VERSION ""

NS_ :

BS_:

BU_: L_DHRR_FD L_UWB_BLE_MST_FD L_UWB_RR_FD L_UWB_BLE_SLV_FD L_UWB_FR_FD L_ROA_FR_FD L_ROA_FD L_DHRL_FD L_UWB_TRNK_FD L_EDT_FD L_UWB_FRNK_FD L_UWB_FL_FD GW_BDC_FD L_UWB_RL_FD L_SAL_FD L_WPC_FD L_TPMS_FD L_DHL_FD L_DHR_FD

BO_ 402391152 NM_CGW_CCU: 32 GW_BDC_FD
 SG_ SNI_CGW_CCU : 0|8@1+ (1,0) [0|0] ""  L_DHL_FD,L_DHRL_FD,L_DHRR_FD,L_DHR_FD,L_SAL_FD,L_TPMS_FD,L_UWB_BLE_MST_FD,L_UWB_BLE_SLV_FD,L_UWB_FL_FD,L_UWB_FRNK_FD,L_UWB_FR_FD,L_UWB_RL_FD,L_UWB_RR_FD,L_UWB_TRNK_FD,L_WPC_FD
 SG_ CBV_NMCoSRB_CGW_CCU : 11|1@1+ (1,0) [0|0] ""  L_DHL_FD,L_DHRL_FD,L_DHRR_FD,L_DHR_FD,L_SAL_FD,L_TPMS_FD,L_UWB_BLE_MST_FD,L_UWB_BLE_SLV_FD,L_UWB_FL_FD,L_UWB_FRNK_FD,L_UWB_FR_FD,L_UWB_RL_FD,L_UWB_RR_FD,L_UWB_TRNK_FD,L_WPC_FD
 SG_ CBV_AWB_CGW_CCU : 12|1@1+ (1,0) [0|0] ""  L_DHL_FD,L_DHRL_FD,L_DHRR_FD,L_DHR_FD,L_SAL_FD,L_TPMS_FD,L_UWB_BLE_MST_FD,L_UWB_BLE_SLV_FD,L_UWB_FL_FD,L_UWB_FRNK_FD,L_UWB_FR_FD,L_UWB_RL_FD,L_UWB_RR_FD,L_UWB_TRNK_FD,L_WPC_FD
 SG_ PNI_CGW_CCU_2 : 128|64@1+ (1,0) [0|0] ""  L_DHL_FD,L_DHRL_FD,L_DHRR_FD,L_DHR_FD,L_SAL_FD,L_TPMS_FD,L_UWB_BLE_MST_FD,L_UWB_BLE_SLV_FD,L_UWB_FL_FD,L_UWB_FRNK_FD,L_UWB_FR_FD,L_UWB_RL_FD,L_UWB_RR_FD,L_UWB_TRNK_FD,L_WPC_FD
 SG_ CBV_PNIB_CGW_CCU : 14|1@1+ (1,0) [0|0] ""  L_DHL_FD,L_DHRL_FD,L_DHRR_FD,L_DHR_FD,L_SAL_FD,L_TPMS_FD,L_UWB_BLE_MST_FD,L_UWB_BLE_SLV_FD,L_UWB_FL_FD,L_UWB_FRNK_FD,L_UWB_FR_FD,L_UWB_RL_FD,L_UWB_RR_FD,L_UWB_TRNK_FD,L_WPC_FD
 SG_ NRR_CGW_CCU : 16|8@1+ (1,0) [0|0] ""  L_DHL_FD,L_DHRL_FD,L_DHRR_FD,L_DHR_FD,L_SAL_FD,L_TPMS_FD,L_UWB_BLE_MST_FD,L_UWB_BLE_SLV_FD,L_UWB_FL_FD,L_UWB_FRNK_FD,L_UWB_FR_FD,L_UWB_RL_FD,L_UWB_RR_FD,L_UWB_TRNK_FD,L_WPC_FD
 SG_ PNI_CGW_CCU_3 : 192|64@1+ (1,0) [0|0] ""  L_DHL_FD,L_DHRL_FD,L_DHRR_FD,L_DHR_FD,L_SAL_FD,L_TPMS_FD,L_UWB_BLE_MST_FD,L_UWB_BLE_SLV_FD,L_UWB_FL_FD,L_UWB_FRNK_FD,L_UWB_FR_FD,L_UWB_RL_FD,L_UWB_RR_FD,L_UWB_TRNK_FD,L_WPC_FD
 SG_ NM_State_CGW_CCU : 24|8@1+ (1,0) [0|0] ""  L_DHL_FD,L_DHRL_FD,L_DHRR_FD,L_DHR_FD,L_SAL_FD,L_TPMS_FD,L_UWB_BLE_MST_FD,L_UWB_BLE_SLV_FD,L_UWB_FL_FD,L_UWB_FRNK_FD,L_UWB_FR_FD,L_UWB_RL_FD,L_UWB_RR_FD,L_UWB_TRNK_FD,L_WPC_FD
 SG_ PNI_CGW_CCU : 32|32@1+ (1,0) [0|0] ""  L_DHL_FD,L_DHRL_FD,L_DHRR_FD,L_DHR_FD,L_SAL_FD,L_TPMS_FD,L_UWB_BLE_MST_FD,L_UWB_BLE_SLV_FD,L_UWB_FL_FD,L_UWB_FRNK_FD,L_UWB_FR_FD,L_UWB_RL_FD,L_UWB_RR_FD,L_UWB_TRNK_FD,L_WPC_FD
 SG_ PNI_CGW_CCU_1 : 64|64@1+ (1,0) [0|0] ""  L_DHL_FD,L_DHRL_FD,L_DHRR_FD,L_DHR_FD,L_SAL_FD,L_TPMS_FD,L_UWB_BLE_MST_FD,L_UWB_BLE_SLV_FD,L_UWB_FL_FD,L_UWB_FRNK_FD,L_UWB_FR_FD,L_UWB_RL_FD,L_UWB_RR_FD,L_UWB_TRNK_FD,L_WPC_FD
 SG_ CBV_RMR_CGW_CCU : 8|1@1+ (1,0) [0|0] ""  L_DHL_FD,L_DHRL_FD,L_DHRR_FD,L_DHR_FD,L_SAL_FD,L_TPMS_FD,L_UWB_BLE_MST_FD,L_UWB_BLE_SLV_FD,L_UWB_FL_FD,L_UWB_FRNK_FD,L_UWB_FR_FD,L_UWB_RL_FD,L_UWB_RR_FD,L_UWB_TRNK_FD,L_WPC_FD
 SG_ CBV_NMCoID_CGW_CCU : 9|2@1+ (1,0) [0|0] ""  L_DHL_FD,L_DHRL_FD,L_DHRR_FD,L_DHR_FD,L_SAL_FD,L_TPMS_FD,L_UWB_BLE_MST_FD,L_UWB_BLE_SLV_FD,L_UWB_FL_FD,L_UWB_FRNK_FD,L_UWB_FR_FD,L_UWB_RL_FD,L_UWB_RR_FD,L_UWB_TRNK_FD,L_WPC_FD

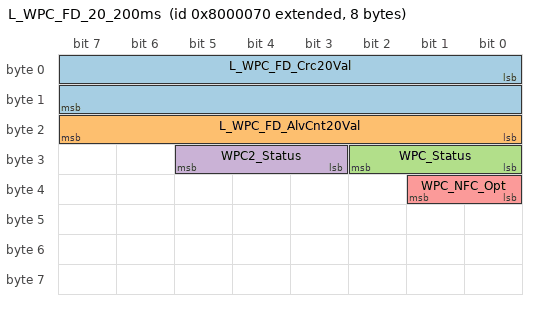
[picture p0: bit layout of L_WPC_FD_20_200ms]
BO_ 2281701488 L_WPC_FD_20_200ms: 8 L_WPC_FD
 SG_ L_WPC_FD_Crc20Val : 0|16@1+ (1,0) [0|0] "0"  Vector__XXX
 SG_ L_WPC_FD_AlvCnt20Val : 16|8@1+ (1,0) [0|0] "0"  Vector__XXX
 SG_ WPC_Status : 24|3@1+ (1,0) [0|0] ""  GW_BDC_FD
 SG_ WPC2_Status : 27|3@1+ (1,0) [0|0] ""  GW_BDC_FD
 SG_ WPC_NFC_Opt : 32|2@1+ (1,0) [0|0] ""  GW_BDC_FD

BO_ 2549874733 NM_L_DHRR_FD: 32 L_DHRR_FD
 SG_ SNI_L_DHRR_FD : 0|8@1+ (1,0) [0|0] ""  GW_BDC_FD,L_DHL_FD,L_DHRL_FD,L_DHR_FD,L_SAL_FD,L_TPMS_FD,L_UWB_BLE_MST_FD,L_UWB_BLE_SLV_FD,L_UWB_FL_FD,L_UWB_FRNK_FD,L_UWB_FR_FD,L_UWB_RL_FD,L_UWB_RR_FD,L_UWB_TRNK_FD,L_WPC_FD
 SG_ CBV_RMR_L_DHRR_FD : 8|1@1+ (1,0) [0|0] ""  GW_BDC_FD,L_DHL_FD,L_DHRL_FD,L_DHR_FD,L_SAL_FD,L_TPMS_FD,L_UWB_BLE_MST_FD,L_UWB_BLE_SLV_FD,L_UWB_FL_FD,L_UWB_FRNK_FD,L_UWB_FR_FD,L_UWB_RL_FD,L_UWB_RR_FD,L_UWB_TRNK_FD,L_WPC_FD
 SG_ CBV_NMCoID_L_DHRR_FD : 9|2@1+ (1,0) [0|0] ""  GW_BDC_FD,L_DHL_FD,L_DHRL_FD,L_DHR_FD,L_SAL_FD,L_TPMS_FD,L_UWB_BLE_MST_FD,L_UWB_BLE_SLV_FD,L_UWB_FL_FD,L_UWB_FRNK_FD,L_UWB_FR_FD,L_UWB_RL_FD,L_UWB_RR_FD,L_UWB_TRNK_FD,L_WPC_FD
 SG_ CBV_NMCoSRB_L_DHRR_FD : 11|1@1+ (1,0) [0|0] ""  GW_BDC_FD,L_DHL_FD,L_DHRL_FD,L_DHR_FD,L_SAL_FD,L_TPMS_FD,L_UWB_BLE_MST_FD,L_UWB_BLE_SLV_FD,L_UWB_FL_FD,L_UWB_FRNK_FD,L_UWB_FR_FD,L_UWB_RL_FD,L_UWB_RR_FD,L_UWB_TRNK_FD,L_WPC_FD
 SG_ CBV_AWB_L_DHRR_FD : 12|1@1+ (1,0) [0|0] ""  GW_BDC_FD,L_DHL_FD,L_DHRL_FD,L_DHR_FD,L_SAL_FD,L_TPMS_FD,L_UWB_BLE_MST_FD,L_UWB_BLE_SLV_FD,L_UWB_FL_FD,L_UWB_FRNK_FD,L_UWB_FR_FD,L_UWB_RL_FD,L_UWB_RR_FD,L_UWB_TRNK_FD,L_WPC_FD
 SG_ CBV_PNIB_L_DHRR_FD : 14|1@1+ (1,0) [0|0] ""  GW_BDC_FD,L_DHL_FD,L_DHRL_FD,L_DHR_FD,L_SAL_FD,L_TPMS_FD,L_UWB_BLE_MST_FD,L_UWB_BLE_SLV_FD,L_UWB_FL_FD,L_UWB_FRNK_FD,L_UWB_FR_FD,L_UWB_RL_FD,L_UWB_RR_FD,L_UWB_TRNK_FD,L_WPC_FD
 SG_ NRR_L_DHRR_FD : 16|8@1+ (1,0) [0|0] ""  GW_BDC_FD,L_DHL_FD,L_DHRL_FD,L_DHR_FD,L_SAL_FD,L_TPMS_FD,L_UWB_BLE_MST_FD,L_UWB_BLE_SLV_FD,L_UWB_FL_FD,L_UWB_FRNK_FD,L_UWB_FR_FD,L_UWB_RL_FD,L_UWB_RR_FD,L_UWB_TRNK_FD,L_WPC_FD
 SG_ NM_State_L_DHRR_FD : 24|8@1+ (1,0) [0|0] ""  GW_BDC_FD,L_DHL_FD,L_DHRL_FD,L_DHR_FD,L_SAL_FD,L_TPMS_FD,L_UWB_BLE_MST_FD,L_UWB_BLE_SLV_FD,L_UWB_FL_FD,L_UWB_FRNK_FD,L_UWB_FR_FD,L_UWB_RL_FD,L_UWB_RR_FD,L_UWB_TRNK_FD,L_WPC_FD
 SG_ PNI_L_DHRR_FD : 32|32@1+ (1,0) [0|0] ""  GW_BDC_FD,L_DHL_FD,L_DHRL_FD,L_DHR_FD,L_SAL_FD,L_TPMS_FD,L_UWB_BLE_MST_FD,L_UWB_BLE_SLV_FD,L_UWB_FL_FD,L_UWB_FRNK_FD,L_UWB_FR_FD,L_UWB_RL_FD,L_UWB_RR_FD,L_UWB_TRNK_FD,L_WPC_FD
 SG_ PNI_L_DHRR_FD_1 : 64|64@1+ (1,0) [0|0] ""  GW_BDC_FD,L_DHL_FD,L_DHRL_FD,L_DHR_FD,L_SAL_FD,L_TPMS_FD,L_UWB_BLE_MST_FD,L_UWB_BLE_SLV_FD,L_UWB_FL_FD,L_UWB_FRNK_FD,L_UWB_FR_FD,L_UWB_RL_FD,L_UWB_RR_FD,L_UWB_TRNK_FD,L_WPC_FD
 SG_ PNI_L_DHRR_FD_2 : 128|64@1+ (1,0) [0|0] ""  GW_BDC_FD,L_DHL_FD,L_DHRL_FD,L_DHR_FD,L_SAL_FD,L_TPMS_FD,L_UWB_BLE_MST_FD,L_UWB_BLE_SLV_FD,L_UWB_FL_FD,L_UWB_FRNK_FD,L_UWB_FR_FD,L_UWB_RL_FD,L_UWB_RR_FD,L_UWB_TRNK_FD,L_WPC_FD
 SG_ PNI_L_DHRR_FD_3 : 192|64@1+ (1,0) [0|0] ""  GW_BDC_FD,L_DHL_FD,L_DHRL_FD,L_DHR_FD,L_SAL_FD,L_TPMS_FD,L_UWB_BLE_MST_FD,L_UWB_BLE_SLV_FD,L_UWB_FL_FD,L_UWB_FRNK_FD,L_UWB_FR_FD,L_UWB_RL_FD,L_UWB_RR_FD,L_UWB_TRNK_FD,L_WPC_FD

BO_ 2549874720 NM_L_UWB_BLE_MST_FD: 32 L_UWB_BLE_MST_FD
 SG_ SNI_L_UWB_BLE_MST_FD : 0|8@1+ (1,0) [0|0] ""  GW_BDC_FD,L_DHL_FD,L_DHRL_FD,L_DHRR_FD,L_DHR_FD,L_SAL_FD,L_TPMS_FD,L_UWB_BLE_SLV_FD,L_UWB_FL_FD,L_UWB_FRNK_FD,L_UWB_FR_FD,L_UWB_RL_FD,L_UWB_RR_FD,L_UWB_TRNK_FD,L_WPC_FD
 SG_ CBV_RMR_L_UWB_BLE_MST_FD : 8|1@1+ (1,0) [0|0] ""  GW_BDC_FD,L_DHL_FD,L_DHRL_FD,L_DHRR_FD,L_DHR_FD,L_SAL_FD,L_TPMS_FD,L_UWB_BLE_SLV_FD,L_UWB_FL_FD,L_UWB_FRNK_FD,L_UWB_FR_FD,L_UWB_RL_FD,L_UWB_RR_FD,L_UWB_TRNK_FD,L_WPC_FD
 SG_ CBV_NMCoID_L_UWB_BLE_MST_FD : 9|2@1+ (1,0) [0|0] ""  GW_BDC_FD,L_DHL_FD,L_DHRL_FD,L_DHRR_FD,L_DHR_FD,L_SAL_FD,L_TPMS_FD,L_UWB_BLE_SLV_FD,L_UWB_FL_FD,L_UWB_FRNK_FD,L_UWB_FR_FD,L_UWB_RL_FD,L_UWB_RR_FD,L_UWB_TRNK_FD,L_WPC_FD
 SG_ CBV_NMCoSRB_L_UWB_BLE_MST_FD : 11|1@1+ (1,0) [0|0] ""  GW_BDC_FD,L_DHL_FD,L_DHRL_FD,L_DHRR_FD,L_DHR_FD,L_SAL_FD,L_TPMS_FD,L_UWB_BLE_SLV_FD,L_UWB_FL_FD,L_UWB_FRNK_FD,L_UWB_FR_FD,L_UWB_RL_FD,L_UWB_RR_FD,L_UWB_TRNK_FD,L_WPC_FD
 SG_ CBV_AWB_L_UWB_BLE_MST_FD : 12|1@1+ (1,0) [0|0] ""  GW_BDC_FD,L_DHL_FD,L_DHRL_FD,L_DHRR_FD,L_DHR_FD,L_SAL_FD,L_TPMS_FD,L_UWB_BLE_SLV_FD,L_UWB_FL_FD,L_UWB_FRNK_FD,L_UWB_FR_FD,L_UWB_RL_FD,L_UWB_RR_FD,L_UWB_TRNK_FD,L_WPC_FD
 SG_ CBV_PNIB_L_UWB_BLE_MST_FD : 14|1@1+ (1,0) [0|0] ""  GW_BDC_FD,L_DHL_FD,L_DHRL_FD,L_DHRR_FD,L_DHR_FD,L_SAL_FD,L_TPMS_FD,L_UWB_BLE_SLV_FD,L_UWB_FL_FD,L_UWB_FRNK_FD,L_UWB_FR_FD,L_UWB_RL_FD,L_UWB_RR_FD,L_UWB_TRNK_FD,L_WPC_FD
 SG_ NRR_L_UWB_BLE_MST_FD : 16|8@1+ (1,0) [0|0] ""  GW_BDC_FD,L_DHL_FD,L_DHRL_FD,L_DHRR_FD,L_DHR_FD,L_SAL_FD,L_TPMS_FD,L_UWB_BLE_SLV_FD,L_UWB_FL_FD,L_UWB_FRNK_FD,L_UWB_FR_FD,L_UWB_RL_FD,L_UWB_RR_FD,L_UWB_TRNK_FD,L_WPC_FD
 SG_ NM_State_L_UWB_BLE_MST_FD : 24|8@1+ (1,0) [0|0] ""  GW_BDC_FD,L_DHL_FD,L_DHRL_FD,L_DHRR_FD,L_DHR_FD,L_SAL_FD,L_TPMS_FD,L_UWB_BLE_SLV_FD,L_UWB_FL_FD,L_UWB_FRNK_FD,L_UWB_FR_FD,L_UWB_RL_FD,L_UWB_RR_FD,L_UWB_TRNK_FD,L_WPC_FD
 SG_ PNI_L_UWB_BLE_MST_FD : 32|32@1+ (1,0) [0|0] ""  GW_BDC_FD,L_DHL_FD,L_DHRL_FD,L_DHRR_FD,L_DHR_FD,L_SAL_FD,L_TPMS_FD,L_UWB_BLE_SLV_FD,L_UWB_FL_FD,L_UWB_FRNK_FD,L_UWB_FR_FD,L_UWB_RL_FD,L_UWB_RR_FD,L_UWB_TRNK_FD,L_WPC_FD
 SG_ PNI_L_UWB_BLE_MST_FD_1 : 64|64@1+ (1,0) [0|0] ""  GW_BDC_FD,L_DHL_FD,L_DHRL_FD,L_DHRR_FD,L_DHR_FD,L_SAL_FD,L_TPMS_FD,L_UWB_BLE_SLV_FD,L_UWB_FL_FD,L_UWB_FRNK_FD,L_UWB_FR_FD,L_UWB_RL_FD,L_UWB_RR_FD,L_UWB_TRNK_FD,L_WPC_FD
 SG_ PNI_L_UWB_BLE_MST_FD_2 : 128|64@1+ (1,0) [0|0] ""  GW_BDC_FD,L_DHL_FD,L_DHRL_FD,L_DHRR_FD,L_DHR_FD,L_SAL_FD,L_TPMS_FD,L_UWB_BLE_SLV_FD,L_UWB_FL_FD,L_UWB_FRNK_FD,L_UWB_FR_FD,L_UWB_RL_FD,L_UWB_RR_FD,L_UWB_TRNK_FD,L_WPC_FD
 SG_ PNI_L_UWB_BLE_MST_FD_3 : 192|64@1+ (1,0) [0|0] ""  GW_BDC_FD,L_DHL_FD,L_DHRL_FD,L_DHRR_FD,L_DHR_FD,L_SAL_FD,L_TPMS_FD,L_UWB_BLE_SLV_FD,L_UWB_FL_FD,L_UWB_FRNK_FD,L_UWB_FR_FD,L_UWB_RL_FD,L_UWB_RR_FD,L_UWB_TRNK_FD,L_WPC_FD

BO_ 2549874726 NM_L_UWB_RR_FD: 32 L_UWB_RR_FD
 SG_ SNI_L_UWB_RR_FD : 0|8@1+ (1,0) [0|0] ""  GW_BDC_FD,L_DHL_FD,L_DHRL_FD,L_DHRR_FD,L_DHR_FD,L_SAL_FD,L_TPMS_FD,L_UWB_BLE_MST_FD,L_UWB_BLE_SLV_FD,L_UWB_FL_FD,L_UWB_FRNK_FD,L_UWB_FR_FD,L_UWB_RL_FD,L_UWB_TRNK_FD,L_WPC_FD
 SG_ CBV_RMR_L_UWB_RR_FD : 8|1@1+ (1,0) [0|0] ""  GW_BDC_FD,L_DHL_FD,L_DHRL_FD,L_DHRR_FD,L_DHR_FD,L_SAL_FD,L_TPMS_FD,L_UWB_BLE_MST_FD,L_UWB_BLE_SLV_FD,L_UWB_FL_FD,L_UWB_FRNK_FD,L_UWB_FR_FD,L_UWB_RL_FD,L_UWB_TRNK_FD,L_WPC_FD
 SG_ CBV_NMCoID_L_UWB_RR_FD : 9|2@1+ (1,0) [0|0] ""  GW_BDC_FD,L_DHL_FD,L_DHRL_FD,L_DHRR_FD,L_DHR_FD,L_SAL_FD,L_TPMS_FD,L_UWB_BLE_MST_FD,L_UWB_BLE_SLV_FD,L_UWB_FL_FD,L_UWB_FRNK_FD,L_UWB_FR_FD,L_UWB_RL_FD,L_UWB_TRNK_FD,L_WPC_FD
 SG_ CBV_NMCoSRB_L_UWB_RR_FD : 11|1@1+ (1,0) [0|0] ""  GW_BDC_FD,L_DHL_FD,L_DHRL_FD,L_DHRR_FD,L_DHR_FD,L_SAL_FD,L_TPMS_FD,L_UWB_BLE_MST_FD,L_UWB_BLE_SLV_FD,L_UWB_FL_FD,L_UWB_FRNK_FD,L_UWB_FR_FD,L_UWB_RL_FD,L_UWB_TRNK_FD,L_WPC_FD
 SG_ CBV_AWB_L_UWB_RR_FD : 12|1@1+ (1,0) [0|0] ""  GW_BDC_FD,L_DHL_FD,L_DHRL_FD,L_DHRR_FD,L_DHR_FD,L_SAL_FD,L_TPMS_FD,L_UWB_BLE_MST_FD,L_UWB_BLE_SLV_FD,L_UWB_FL_FD,L_UWB_FRNK_FD,L_UWB_FR_FD,L_UWB_RL_FD,L_UWB_TRNK_FD,L_WPC_FD
 SG_ CBV_PNIB_L_UWB_RR_FD : 14|1@1+ (1,0) [0|0] ""  GW_BDC_FD,L_DHL_FD,L_DHRL_FD,L_DHRR_FD,L_DHR_FD,L_SAL_FD,L_TPMS_FD,L_UWB_BLE_MST_FD,L_UWB_BLE_SLV_FD,L_UWB_FL_FD,L_UWB_FRNK_FD,L_UWB_FR_FD,L_UWB_RL_FD,L_UWB_TRNK_FD,L_WPC_FD
 SG_ NRR_L_UWB_RR_FD : 16|8@1+ (1,0) [0|0] ""  GW_BDC_FD,L_DHL_FD,L_DHRL_FD,L_DHRR_FD,L_DHR_FD,L_SAL_FD,L_TPMS_FD,L_UWB_BLE_MST_FD,L_UWB_BLE_SLV_FD,L_UWB_FL_FD,L_UWB_FRNK_FD,L_UWB_FR_FD,L_UWB_RL_FD,L_UWB_TRNK_FD,L_WPC_FD
 SG_ NM_State_L_UWB_RR_FD : 24|8@1+ (1,0) [0|0] ""  GW_BDC_FD,L_DHL_FD,L_DHRL_FD,L_DHRR_FD,L_DHR_FD,L_SAL_FD,L_TPMS_FD,L_UWB_BLE_MST_FD,L_UWB_BLE_SLV_FD,L_UWB_FL_FD,L_UWB_FRNK_FD,L_UWB_FR_FD,L_UWB_RL_FD,L_UWB_TRNK_FD,L_WPC_FD
 SG_ PNI_L_UWB_RR_FD : 32|32@1+ (1,0) [0|0] ""  GW_BDC_FD,L_DHL_FD,L_DHRL_FD,L_DHRR_FD,L_DHR_FD,L_SAL_FD,L_TPMS_FD,L_UWB_BLE_MST_FD,L_UWB_BLE_SLV_FD,L_UWB_FL_FD,L_UWB_FRNK_FD,L_UWB_FR_FD,L_UWB_RL_FD,L_UWB_TRNK_FD,L_WPC_FD
 SG_ PNI_L_UWB_RR_FD_1 : 64|64@1+ (1,0) [0|0] ""  GW_BDC_FD,L_DHL_FD,L_DHRL_FD,L_DHRR_FD,L_DHR_FD,L_SAL_FD,L_TPMS_FD,L_UWB_BLE_MST_FD,L_UWB_BLE_SLV_FD,L_UWB_FL_FD,L_UWB_FRNK_FD,L_UWB_FR_FD,L_UWB_RL_FD,L_UWB_TRNK_FD,L_WPC_FD
 SG_ PNI_L_UWB_RR_FD_2 : 128|64@1+ (1,0) [0|0] ""  GW_BDC_FD,L_DHL_FD,L_DHRL_FD,L_DHRR_FD,L_DHR_FD,L_SAL_FD,L_TPMS_FD,L_UWB_BLE_MST_FD,L_UWB_BLE_SLV_FD,L_UWB_FL_FD,L_UWB_FRNK_FD,L_UWB_FR_FD,L_UWB_RL_FD,L_UWB_TRNK_FD,L_WPC_FD
 SG_ PNI_L_UWB_RR_FD_3 : 192|64@1+ (1,0) [0|0] ""  GW_BDC_FD,L_DHL_FD,L_DHRL_FD,L_DHRR_FD,L_DHR_FD,L_SAL_FD,L_TPMS_FD,L_UWB_BLE_MST_FD,L_UWB_BLE_SLV_FD,L_UWB_FL_FD,L_UWB_FRNK_FD,L_UWB_FR_FD,L_UWB_RL_FD,L_UWB_TRNK_FD,L_WPC_FD

BO_ 2549874721 NM_L_UWB_BLE_SLV_FD: 32 L_UWB_BLE_SLV_FD
 SG_ SNI_L_UWB_BLE_SLV_FD : 0|8@1+ (1,0) [0|0] ""  GW_BDC_FD,L_DHL_FD,L_DHRL_FD,L_DHRR_FD,L_DHR_FD,L_SAL_FD,L_TPMS_FD,L_UWB_BLE_MST_FD,L_UWB_FL_FD,L_UWB_FRNK_FD,L_UWB_FR_FD,L_UWB_RL_FD,L_UWB_RR_FD,L_UWB_TRNK_FD,L_WPC_FD
 SG_ CBV_RMR_L_UWB_BLE_SLV_FD : 8|1@1+ (1,0) [0|0] ""  GW_BDC_FD,L_DHL_FD,L_DHRL_FD,L_DHRR_FD,L_DHR_FD,L_SAL_FD,L_TPMS_FD,L_UWB_BLE_MST_FD,L_UWB_FL_FD,L_UWB_FRNK_FD,L_UWB_FR_FD,L_UWB_RL_FD,L_UWB_RR_FD,L_UWB_TRNK_FD,L_WPC_FD
 SG_ CBV_NMCoID_L_UWB_BLE_SLV_FD : 9|2@1+ (1,0) [0|0] ""  GW_BDC_FD,L_DHL_FD,L_DHRL_FD,L_DHRR_FD,L_DHR_FD,L_SAL_FD,L_TPMS_FD,L_UWB_BLE_MST_FD,L_UWB_FL_FD,L_UWB_FRNK_FD,L_UWB_FR_FD,L_UWB_RL_FD,L_UWB_RR_FD,L_UWB_TRNK_FD,L_WPC_FD
 SG_ CBV_NMCoSRB_L_UWB_BLE_SLV_FD : 11|1@1+ (1,0) [0|0] ""  GW_BDC_FD,L_DHL_FD,L_DHRL_FD,L_DHRR_FD,L_DHR_FD,L_SAL_FD,L_TPMS_FD,L_UWB_BLE_MST_FD,L_UWB_FL_FD,L_UWB_FRNK_FD,L_UWB_FR_FD,L_UWB_RL_FD,L_UWB_RR_FD,L_UWB_TRNK_FD,L_WPC_FD
 SG_ CBV_AWB_L_UWB_BLE_SLV_FD : 12|1@1+ (1,0) [0|0] ""  GW_BDC_FD,L_DHL_FD,L_DHRL_FD,L_DHRR_FD,L_DHR_FD,L_SAL_FD,L_TPMS_FD,L_UWB_BLE_MST_FD,L_UWB_FL_FD,L_UWB_FRNK_FD,L_UWB_FR_FD,L_UWB_RL_FD,L_UWB_RR_FD,L_UWB_TRNK_FD,L_WPC_FD
 SG_ CBV_PNIB_L_UWB_BLE_SLV_FD : 14|1@1+ (1,0) [0|0] ""  GW_BDC_FD,L_DHL_FD,L_DHRL_FD,L_DHRR_FD,L_DHR_FD,L_SAL_FD,L_TPMS_FD,L_UWB_BLE_MST_FD,L_UWB_FL_FD,L_UWB_FRNK_FD,L_UWB_FR_FD,L_UWB_RL_FD,L_UWB_RR_FD,L_UWB_TRNK_FD,L_WPC_FD
 SG_ NRR_L_UWB_BLE_SLV_FD : 16|8@1+ (1,0) [0|0] ""  GW_BDC_FD,L_DHL_FD,L_DHRL_FD,L_DHRR_FD,L_DHR_FD,L_SAL_FD,L_TPMS_FD,L_UWB_BLE_MST_FD,L_UWB_FL_FD,L_UWB_FRNK_FD,L_UWB_FR_FD,L_UWB_RL_FD,L_UWB_RR_FD,L_UWB_TRNK_FD,L_WPC_FD
 SG_ NM_State_L_UWB_BLE_SLV_FD : 24|8@1+ (1,0) [0|0] ""  GW_BDC_FD,L_DHL_FD,L_DHRL_FD,L_DHRR_FD,L_DHR_FD,L_SAL_FD,L_TPMS_FD,L_UWB_BLE_MST_FD,L_UWB_FL_FD,L_UWB_FRNK_FD,L_UWB_FR_FD,L_UWB_RL_FD,L_UWB_RR_FD,L_UWB_TRNK_FD,L_WPC_FD
 SG_ PNI_L_UWB_BLE_SLV_FD : 32|32@1+ (1,0) [0|0] ""  GW_BDC_FD,L_DHL_FD,L_DHRL_FD,L_DHRR_FD,L_DHR_FD,L_SAL_FD,L_TPMS_FD,L_UWB_BLE_MST_FD,L_UWB_FL_FD,L_UWB_FRNK_FD,L_UWB_FR_FD,L_UWB_RL_FD,L_UWB_RR_FD,L_UWB_TRNK_FD,L_WPC_FD
 SG_ PNI_L_UWB_BLE_SLV_FD_1 : 64|64@1+ (1,0) [0|0] ""  GW_BDC_FD,L_DHL_FD,L_DHRL_FD,L_DHRR_FD,L_DHR_FD,L_SAL_FD,L_TPMS_FD,L_UWB_BLE_MST_FD,L_UWB_FL_FD,L_UWB_FRNK_FD,L_UWB_FR_FD,L_UWB_RL_FD,L_UWB_RR_FD,L_UWB_TRNK_FD,L_WPC_FD
 SG_ PNI_L_UWB_BLE_SLV_FD_2 : 128|64@1+ (1,0) [0|0] ""  GW_BDC_FD,L_DHL_FD,L_DHRL_FD,L_DHRR_FD,L_DHR_FD,L_SAL_FD,L_TPMS_FD,L_UWB_BLE_MST_FD,L_UWB_FL_FD,L_UWB_FRNK_FD,L_UWB_FR_FD,L_UWB_RL_FD,L_UWB_RR_FD,L_UWB_TRNK_FD,L_WPC_FD
 SG_ PNI_L_UWB_BLE_SLV_FD_3 : 192|64@1+ (1,0) [0|0] ""  GW_BDC_FD,L_DHL_FD,L_DHRL_FD,L_DHRR_FD,L_DHR_FD,L_SAL_FD,L_TPMS_FD,L_UWB_BLE_MST_FD,L_UWB_FL_FD,L_UWB_FRNK_FD,L_UWB_FR_FD,L_UWB_RL_FD,L_UWB_RR_FD,L_UWB_TRNK_FD,L_WPC_FD

BO_ 2549874723 NM_L_UWB_FR_FD: 32 L_UWB_FR_FD
 SG_ SNI_L_UWB_FR_FD : 0|8@1+ (1,0) [0|0] ""  GW_BDC_FD,L_DHL_FD,L_DHRL_FD,L_DHRR_FD,L_DHR_FD,L_SAL_FD,L_TPMS_FD,L_UWB_BLE_MST_FD,L_UWB_BLE_SLV_FD,L_UWB_FL_FD,L_UWB_FRNK_FD,L_UWB_RL_FD,L_UWB_RR_FD,L_UWB_TRNK_FD,L_WPC_FD
 SG_ CBV_RMR_L_UWB_FR_FD : 8|1@1+ (1,0) [0|0] ""  GW_BDC_FD,L_DHL_FD,L_DHRL_FD,L_DHRR_FD,L_DHR_FD,L_SAL_FD,L_TPMS_FD,L_UWB_BLE_MST_FD,L_UWB_BLE_SLV_FD,L_UWB_FL_FD,L_UWB_FRNK_FD,L_UWB_RL_FD,L_UWB_RR_FD,L_UWB_TRNK_FD,L_WPC_FD
 SG_ CBV_NMCoID_L_UWB_FR_FD : 9|2@1+ (1,0) [0|0] ""  GW_BDC_FD,L_DHL_FD,L_DHRL_FD,L_DHRR_FD,L_DHR_FD,L_SAL_FD,L_TPMS_FD,L_UWB_BLE_MST_FD,L_UWB_BLE_SLV_FD,L_UWB_FL_FD,L_UWB_FRNK_FD,L_UWB_RL_FD,L_UWB_RR_FD,L_UWB_TRNK_FD,L_WPC_FD
 SG_ CBV_NMCoSRB_L_UWB_FR_FD : 11|1@1+ (1,0) [0|0] ""  GW_BDC_FD,L_DHL_FD,L_DHRL_FD,L_DHRR_FD,L_DHR_FD,L_SAL_FD,L_TPMS_FD,L_UWB_BLE_MST_FD,L_UWB_BLE_SLV_FD,L_UWB_FL_FD,L_UWB_FRNK_FD,L_UWB_RL_FD,L_UWB_RR_FD,L_UWB_TRNK_FD,L_WPC_FD
 SG_ CBV_AWB_L_UWB_FR_FD : 12|1@1+ (1,0) [0|0] ""  GW_BDC_FD,L_DHL_FD,L_DHRL_FD,L_DHRR_FD,L_DHR_FD,L_SAL_FD,L_TPMS_FD,L_UWB_BLE_MST_FD,L_UWB_BLE_SLV_FD,L_UWB_FL_FD,L_UWB_FRNK_FD,L_UWB_RL_FD,L_UWB_RR_FD,L_UWB_TRNK_FD,L_WPC_FD
 SG_ CBV_PNIB_L_UWB_FR_FD : 14|1@1+ (1,0) [0|0] ""  GW_BDC_FD,L_DHL_FD,L_DHRL_FD,L_DHRR_FD,L_DHR_FD,L_SAL_FD,L_TPMS_FD,L_UWB_BLE_MST_FD,L_UWB_BLE_SLV_FD,L_UWB_FL_FD,L_UWB_FRNK_FD,L_UWB_RL_FD,L_UWB_RR_FD,L_UWB_TRNK_FD,L_WPC_FD
 SG_ NRR_L_UWB_FR_FD : 16|8@1+ (1,0) [0|0] ""  GW_BDC_FD,L_DHL_FD,L_DHRL_FD,L_DHRR_FD,L_DHR_FD,L_SAL_FD,L_TPMS_FD,L_UWB_BLE_MST_FD,L_UWB_BLE_SLV_FD,L_UWB_FL_FD,L_UWB_FRNK_FD,L_UWB_RL_FD,L_UWB_RR_FD,L_UWB_TRNK_FD,L_WPC_FD
 SG_ NM_State_L_UWB_FR_FD : 24|8@1+ (1,0) [0|0] ""  GW_BDC_FD,L_DHL_FD,L_DHRL_FD,L_DHRR_FD,L_DHR_FD,L_SAL_FD,L_TPMS_FD,L_UWB_BLE_MST_FD,L_UWB_BLE_SLV_FD,L_UWB_FL_FD,L_UWB_FRNK_FD,L_UWB_RL_FD,L_UWB_RR_FD,L_UWB_TRNK_FD,L_WPC_FD
 SG_ PNI_L_UWB_FR_FD : 32|32@1+ (1,0) [0|0] ""  GW_BDC_FD,L_DHL_FD,L_DHRL_FD,L_DHRR_FD,L_DHR_FD,L_SAL_FD,L_TPMS_FD,L_UWB_BLE_MST_FD,L_UWB_BLE_SLV_FD,L_UWB_FL_FD,L_UWB_FRNK_FD,L_UWB_RL_FD,L_UWB_RR_FD,L_UWB_TRNK_FD,L_WPC_FD
 SG_ PNI_L_UWB_FR_FD_1 : 64|64@1+ (1,0) [0|0] ""  GW_BDC_FD,L_DHL_FD,L_DHRL_FD,L_DHRR_FD,L_DHR_FD,L_SAL_FD,L_TPMS_FD,L_UWB_BLE_MST_FD,L_UWB_BLE_SLV_FD,L_UWB_FL_FD,L_UWB_FRNK_FD,L_UWB_RL_FD,L_UWB_RR_FD,L_UWB_TRNK_FD,L_WPC_FD
 SG_ PNI_L_UWB_FR_FD_2 : 128|64@1+ (1,0) [0|0] ""  GW_BDC_FD,L_DHL_FD,L_DHRL_FD,L_DHRR_FD,L_DHR_FD,L_SAL_FD,L_TPMS_FD,L_UWB_BLE_MST_FD,L_UWB_BLE_SLV_FD,L_UWB_FL_FD,L_UWB_FRNK_FD,L_UWB_RL_FD,L_UWB_RR_FD,L_UWB_TRNK_FD,L_WPC_FD
 SG_ PNI_L_UWB_FR_FD_3 : 192|64@1+ (1,0) [0|0] ""  GW_BDC_FD,L_DHL_FD,L_DHRL_FD,L_DHRR_FD,L_DHR_FD,L_SAL_FD,L_TPMS_FD,L_UWB_BLE_MST_FD,L_UWB_BLE_SLV_FD,L_UWB_FL_FD,L_UWB_FRNK_FD,L_UWB_RL_FD,L_UWB_RR_FD,L_UWB_TRNK_FD,L_WPC_FD

BO_ 2549874732 NM_L_DHRL_FD: 32 L_DHRL_FD
 SG_ SNI_L_DHRL_FD : 0|8@1+ (1,0) [0|0] ""  GW_BDC_FD,L_DHL_FD,L_DHRR_FD,L_DHR_FD,L_SAL_FD,L_TPMS_FD,L_UWB_BLE_MST_FD,L_UWB_BLE_SLV_FD,L_UWB_FL_FD,L_UWB_FRNK_FD,L_UWB_FR_FD,L_UWB_RL_FD,L_UWB_RR_FD,L_UWB_TRNK_FD,L_WPC_FD
 SG_ CBV_RMR_L_DHRL_FD : 8|1@1+ (1,0) [0|0] ""  GW_BDC_FD,L_DHL_FD,L_DHRR_FD,L_DHR_FD,L_SAL_FD,L_TPMS_FD,L_UWB_BLE_MST_FD,L_UWB_BLE_SLV_FD,L_UWB_FL_FD,L_UWB_FRNK_FD,L_UWB_FR_FD,L_UWB_RL_FD,L_UWB_RR_FD,L_UWB_TRNK_FD,L_WPC_FD
 SG_ CBV_NMCoID_L_DHRL_FD : 9|2@1+ (1,0) [0|0] ""  GW_BDC_FD,L_DHL_FD,L_DHRR_FD,L_DHR_FD,L_SAL_FD,L_TPMS_FD,L_UWB_BLE_MST_FD,L_UWB_BLE_SLV_FD,L_UWB_FL_FD,L_UWB_FRNK_FD,L_UWB_FR_FD,L_UWB_RL_FD,L_UWB_RR_FD,L_UWB_TRNK_FD,L_WPC_FD
 SG_ CBV_NMCoSRB_L_DHRL_FD : 11|1@1+ (1,0) [0|0] ""  GW_BDC_FD,L_DHL_FD,L_DHRR_FD,L_DHR_FD,L_SAL_FD,L_TPMS_FD,L_UWB_BLE_MST_FD,L_UWB_BLE_SLV_FD,L_UWB_FL_FD,L_UWB_FRNK_FD,L_UWB_FR_FD,L_UWB_RL_FD,L_UWB_RR_FD,L_UWB_TRNK_FD,L_WPC_FD
 SG_ CBV_AWB_L_DHRL_FD : 12|1@1+ (1,0) [0|0] ""  GW_BDC_FD,L_DHL_FD,L_DHRR_FD,L_DHR_FD,L_SAL_FD,L_TPMS_FD,L_UWB_BLE_MST_FD,L_UWB_BLE_SLV_FD,L_UWB_FL_FD,L_UWB_FRNK_FD,L_UWB_FR_FD,L_UWB_RL_FD,L_UWB_RR_FD,L_UWB_TRNK_FD,L_WPC_FD
 SG_ CBV_PNIB_L_DHRL_FD : 14|1@1+ (1,0) [0|0] ""  GW_BDC_FD,L_DHL_FD,L_DHRR_FD,L_DHR_FD,L_SAL_FD,L_TPMS_FD,L_UWB_BLE_MST_FD,L_UWB_BLE_SLV_FD,L_UWB_FL_FD,L_UWB_FRNK_FD,L_UWB_FR_FD,L_UWB_RL_FD,L_UWB_RR_FD,L_UWB_TRNK_FD,L_WPC_FD
 SG_ NRR_L_DHRL_FD : 16|8@1+ (1,0) [0|0] ""  GW_BDC_FD,L_DHL_FD,L_DHRR_FD,L_DHR_FD,L_SAL_FD,L_TPMS_FD,L_UWB_BLE_MST_FD,L_UWB_BLE_SLV_FD,L_UWB_FL_FD,L_UWB_FRNK_FD,L_UWB_FR_FD,L_UWB_RL_FD,L_UWB_RR_FD,L_UWB_TRNK_FD,L_WPC_FD
 SG_ NM_State_L_DHRL_FD : 24|8@1+ (1,0) [0|0] ""  GW_BDC_FD,L_DHL_FD,L_DHRR_FD,L_DHR_FD,L_SAL_FD,L_TPMS_FD,L_UWB_BLE_MST_FD,L_UWB_BLE_SLV_FD,L_UWB_FL_FD,L_UWB_FRNK_FD,L_UWB_FR_FD,L_UWB_RL_FD,L_UWB_RR_FD,L_UWB_TRNK_FD,L_WPC_FD
 SG_ PNI_L_DHRL_FD : 32|32@1+ (1,0) [0|0] ""  GW_BDC_FD,L_DHL_FD,L_DHRR_FD,L_DHR_FD,L_SAL_FD,L_TPMS_FD,L_UWB_BLE_MST_FD,L_UWB_BLE_SLV_FD,L_UWB_FL_FD,L_UWB_FRNK_FD,L_UWB_FR_FD,L_UWB_RL_FD,L_UWB_RR_FD,L_UWB_TRNK_FD,L_WPC_FD
 SG_ PNI_L_DHRL_FD_1 : 64|64@1+ (1,0) [0|0] ""  GW_BDC_FD,L_DHL_FD,L_DHRR_FD,L_DHR_FD,L_SAL_FD,L_TPMS_FD,L_UWB_BLE_MST_FD,L_UWB_BLE_SLV_FD,L_UWB_FL_FD,L_UWB_FRNK_FD,L_UWB_FR_FD,L_UWB_RL_FD,L_UWB_RR_FD,L_UWB_TRNK_FD,L_WPC_FD
 SG_ PNI_L_DHRL_FD_2 : 128|64@1+ (1,0) [0|0] ""  GW_BDC_FD,L_DHL_FD,L_DHRR_FD,L_DHR_FD,L_SAL_FD,L_TPMS_FD,L_UWB_BLE_MST_FD,L_UWB_BLE_SLV_FD,L_UWB_FL_FD,L_UWB_FRNK_FD,L_UWB_FR_FD,L_UWB_RL_FD,L_UWB_RR_FD,L_UWB_TRNK_FD,L_WPC_FD
 SG_ PNI_L_DHRL_FD_3 : 192|64@1+ (1,0) [0|0] ""  GW_BDC_FD,L_DHL_FD,L_DHRR_FD,L_DHR_FD,L_SAL_FD,L_TPMS_FD,L_UWB_BLE_MST_FD,L_UWB_BLE_SLV_FD,L_UWB_FL_FD,L_UWB_FRNK_FD,L_UWB_FR_FD,L_UWB_RL_FD,L_UWB_RR_FD,L_UWB_TRNK_FD,L_WPC_FD

BO_ 2549874727 NM_L_UWB_TRNK_FD: 32 L_UWB_TRNK_FD
 SG_ SNI_L_UWB_TRNK_FD : 0|8@1+ (1,0) [0|0] ""  GW_BDC_FD,L_DHL_FD,L_DHRL_FD,L_DHRR_FD,L_DHR_FD,L_SAL_FD,L_TPMS_FD,L_UWB_BLE_MST_FD,L_UWB_BLE_SLV_FD,L_UWB_FL_FD,L_UWB_FRNK_FD,L_UWB_FR_FD,L_UWB_RL_FD,L_UWB_RR_FD,L_WPC_FD
 SG_ CBV_RMR_L_UWB_TRNK_FD : 8|1@1+ (1,0) [0|0] ""  GW_BDC_FD,L_DHL_FD,L_DHRL_FD,L_DHRR_FD,L_DHR_FD,L_SAL_FD,L_TPMS_FD,L_UWB_BLE_MST_FD,L_UWB_BLE_SLV_FD,L_UWB_FL_FD,L_UWB_FRNK_FD,L_UWB_FR_FD,L_UWB_RL_FD,L_UWB_RR_FD,L_WPC_FD
 SG_ CBV_NMCoID_L_UWB_TRNK_FD : 9|2@1+ (1,0) [0|0] ""  GW_BDC_FD,L_DHL_FD,L_DHRL_FD,L_DHRR_FD,L_DHR_FD,L_SAL_FD,L_TPMS_FD,L_UWB_BLE_MST_FD,L_UWB_BLE_SLV_FD,L_UWB_FL_FD,L_UWB_FRNK_FD,L_UWB_FR_FD,L_UWB_RL_FD,L_UWB_RR_FD,L_WPC_FD
 SG_ CBV_NMCoSRB_L_UWB_TRNK_FD : 11|1@1+ (1,0) [0|0] ""  GW_BDC_FD,L_DHL_FD,L_DHRL_FD,L_DHRR_FD,L_DHR_FD,L_SAL_FD,L_TPMS_FD,L_UWB_BLE_MST_FD,L_UWB_BLE_SLV_FD,L_UWB_FL_FD,L_UWB_FRNK_FD,L_UWB_FR_FD,L_UWB_RL_FD,L_UWB_RR_FD,L_WPC_FD
 SG_ CBV_AWB_L_UWB_TRNK_FD : 12|1@1+ (1,0) [0|0] ""  GW_BDC_FD,L_DHL_FD,L_DHRL_FD,L_DHRR_FD,L_DHR_FD,L_SAL_FD,L_TPMS_FD,L_UWB_BLE_MST_FD,L_UWB_BLE_SLV_FD,L_UWB_FL_FD,L_UWB_FRNK_FD,L_UWB_FR_FD,L_UWB_RL_FD,L_UWB_RR_FD,L_WPC_FD
 SG_ CBV_PNIB_L_UWB_TRNK_FD : 14|1@1+ (1,0) [0|0] ""  GW_BDC_FD,L_DHL_FD,L_DHRL_FD,L_DHRR_FD,L_DHR_FD,L_SAL_FD,L_TPMS_FD,L_UWB_BLE_MST_FD,L_UWB_BLE_SLV_FD,L_UWB_FL_FD,L_UWB_FRNK_FD,L_UWB_FR_FD,L_UWB_RL_FD,L_UWB_RR_FD,L_WPC_FD
 SG_ NRR_L_UWB_TRNK_FD : 16|8@1+ (1,0) [0|0] ""  GW_BDC_FD,L_DHL_FD,L_DHRL_FD,L_DHRR_FD,L_DHR_FD,L_SAL_FD,L_TPMS_FD,L_UWB_BLE_MST_FD,L_UWB_BLE_SLV_FD,L_UWB_FL_FD,L_UWB_FRNK_FD,L_UWB_FR_FD,L_UWB_RL_FD,L_UWB_RR_FD,L_WPC_FD
 SG_ NM_State_L_UWB_TRNK_FD : 24|8@1+ (1,0) [0|0] ""  GW_BDC_FD,L_DHL_FD,L_DHRL_FD,L_DHRR_FD,L_DHR_FD,L_SAL_FD,L_TPMS_FD,L_UWB_BLE_MST_FD,L_UWB_BLE_SLV_FD,L_UWB_FL_FD,L_UWB_FRNK_FD,L_UWB_FR_FD,L_UWB_RL_FD,L_UWB_RR_FD,L_WPC_FD
 SG_ PNI_L_UWB_TRNK_FD : 32|32@1+ (1,0) [0|0] ""  GW_BDC_FD,L_DHL_FD,L_DHRL_FD,L_DHRR_FD,L_DHR_FD,L_SAL_FD,L_TPMS_FD,L_UWB_BLE_MST_FD,L_UWB_BLE_SLV_FD,L_UWB_FL_FD,L_UWB_FRNK_FD,L_UWB_FR_FD,L_UWB_RL_FD,L_UWB_RR_FD,L_WPC_FD
 SG_ PNI_L_UWB_TRNK_FD_1 : 64|64@1+ (1,0) [0|0] ""  GW_BDC_FD,L_DHL_FD,L_DHRL_FD,L_DHRR_FD,L_DHR_FD,L_SAL_FD,L_TPMS_FD,L_UWB_BLE_MST_FD,L_UWB_BLE_SLV_FD,L_UWB_FL_FD,L_UWB_FRNK_FD,L_UWB_FR_FD,L_UWB_RL_FD,L_UWB_RR_FD,L_WPC_FD
 SG_ PNI_L_UWB_TRNK_FD_2 : 128|64@1+ (1,0) [0|0] ""  GW_BDC_FD,L_DHL_FD,L_DHRL_FD,L_DHRR_FD,L_DHR_FD,L_SAL_FD,L_TPMS_FD,L_UWB_BLE_MST_FD,L_UWB_BLE_SLV_FD,L_UWB_FL_FD,L_UWB_FRNK_FD,L_UWB_FR_FD,L_UWB_RL_FD,L_UWB_RR_FD,L_WPC_FD
 SG_ PNI_L_UWB_TRNK_FD_3 : 192|64@1+ (1,0) [0|0] ""  GW_BDC_FD,L_DHL_FD,L_DHRL_FD,L_DHRR_FD,L_DHR_FD,L_SAL_FD,L_TPMS_FD,L_UWB_BLE_MST_FD,L_UWB_BLE_SLV_FD,L_UWB_FL_FD,L_UWB_FRNK_FD,L_UWB_FR_FD,L_UWB_RL_FD,L_UWB_RR_FD,L_WPC_FD

BO_ 2549874724 NM_L_UWB_FRNK_FD: 32 L_UWB_FRNK_FD
 SG_ SNI_L_UWB_FRNK_FD : 0|8@1+ (1,0) [0|0] ""  GW_BDC_FD,L_DHL_FD,L_DHRL_FD,L_DHRR_FD,L_DHR_FD,L_SAL_FD,L_TPMS_FD,L_UWB_BLE_MST_FD,L_UWB_BLE_SLV_FD,L_UWB_FL_FD,L_UWB_FR_FD,L_UWB_RL_FD,L_UWB_RR_FD,L_UWB_TRNK_FD,L_WPC_FD
 SG_ CBV_RMR_L_UWB_FRNK_FD : 8|1@1+ (1,0) [0|0] ""  GW_BDC_FD,L_DHL_FD,L_DHRL_FD,L_DHRR_FD,L_DHR_FD,L_SAL_FD,L_TPMS_FD,L_UWB_BLE_MST_FD,L_UWB_BLE_SLV_FD,L_UWB_FL_FD,L_UWB_FR_FD,L_UWB_RL_FD,L_UWB_RR_FD,L_UWB_TRNK_FD,L_WPC_FD
 SG_ CBV_NMCoID_L_UWB_FRNK_FD : 9|2@1+ (1,0) [0|0] ""  GW_BDC_FD,L_DHL_FD,L_DHRL_FD,L_DHRR_FD,L_DHR_FD,L_SAL_FD,L_TPMS_FD,L_UWB_BLE_MST_FD,L_UWB_BLE_SLV_FD,L_UWB_FL_FD,L_UWB_FR_FD,L_UWB_RL_FD,L_UWB_RR_FD,L_UWB_TRNK_FD,L_WPC_FD
 SG_ CBV_NMCoSRB_L_UWB_FRNK_FD : 11|1@1+ (1,0) [0|0] ""  GW_BDC_FD,L_DHL_FD,L_DHRL_FD,L_DHRR_FD,L_DHR_FD,L_SAL_FD,L_TPMS_FD,L_UWB_BLE_MST_FD,L_UWB_BLE_SLV_FD,L_UWB_FL_FD,L_UWB_FR_FD,L_UWB_RL_FD,L_UWB_RR_FD,L_UWB_TRNK_FD,L_WPC_FD
 SG_ CBV_AWB_L_UWB_FRNK_FD : 12|1@1+ (1,0) [0|0] ""  GW_BDC_FD,L_DHL_FD,L_DHRL_FD,L_DHRR_FD,L_DHR_FD,L_SAL_FD,L_TPMS_FD,L_UWB_BLE_MST_FD,L_UWB_BLE_SLV_FD,L_UWB_FL_FD,L_UWB_FR_FD,L_UWB_RL_FD,L_UWB_RR_FD,L_UWB_TRNK_FD,L_WPC_FD
 SG_ CBV_PNIB_L_UWB_FRNK_FD : 14|1@1+ (1,0) [0|0] ""  GW_BDC_FD,L_DHL_FD,L_DHRL_FD,L_DHRR_FD,L_DHR_FD,L_SAL_FD,L_TPMS_FD,L_UWB_BLE_MST_FD,L_UWB_BLE_SLV_FD,L_UWB_FL_FD,L_UWB_FR_FD,L_UWB_RL_FD,L_UWB_RR_FD,L_UWB_TRNK_FD,L_WPC_FD
 SG_ NRR_L_UWB_FRNK_FD : 16|8@1+ (1,0) [0|0] ""  GW_BDC_FD,L_DHL_FD,L_DHRL_FD,L_DHRR_FD,L_DHR_FD,L_SAL_FD,L_TPMS_FD,L_UWB_BLE_MST_FD,L_UWB_BLE_SLV_FD,L_UWB_FL_FD,L_UWB_FR_FD,L_UWB_RL_FD,L_UWB_RR_FD,L_UWB_TRNK_FD,L_WPC_FD
 SG_ NM_State_L_UWB_FRNK_FD : 24|8@1+ (1,0) [0|0] ""  GW_BDC_FD,L_DHL_FD,L_DHRL_FD,L_DHRR_FD,L_DHR_FD,L_SAL_FD,L_TPMS_FD,L_UWB_BLE_MST_FD,L_UWB_BLE_SLV_FD,L_UWB_FL_FD,L_UWB_FR_FD,L_UWB_RL_FD,L_UWB_RR_FD,L_UWB_TRNK_FD,L_WPC_FD
 SG_ PNI_L_UWB_FRNK_FD : 32|32@1+ (1,0) [0|0] ""  GW_BDC_FD,L_DHL_FD,L_DHRL_FD,L_DHRR_FD,L_DHR_FD,L_SAL_FD,L_TPMS_FD,L_UWB_BLE_MST_FD,L_UWB_BLE_SLV_FD,L_UWB_FL_FD,L_UWB_FR_FD,L_UWB_RL_FD,L_UWB_RR_FD,L_UWB_TRNK_FD,L_WPC_FD
 SG_ PNI_L_UWB_FRNK_FD_1 : 64|64@1+ (1,0) [0|0] ""  GW_BDC_FD,L_DHL_FD,L_DHRL_FD,L_DHRR_FD,L_DHR_FD,L_SAL_FD,L_TPMS_FD,L_UWB_BLE_MST_FD,L_UWB_BLE_SLV_FD,L_UWB_FL_FD,L_UWB_FR_FD,L_UWB_RL_FD,L_UWB_RR_FD,L_UWB_TRNK_FD,L_WPC_FD
 SG_ PNI_L_UWB_FRNK_FD_2 : 128|64@1+ (1,0) [0|0] ""  GW_BDC_FD,L_DHL_FD,L_DHRL_FD,L_DHRR_FD,L_DHR_FD,L_SAL_FD,L_TPMS_FD,L_UWB_BLE_MST_FD,L_UWB_BLE_SLV_FD,L_UWB_FL_FD,L_UWB_FR_FD,L_UWB_RL_FD,L_UWB_RR_FD,L_UWB_TRNK_FD,L_WPC_FD
 SG_ PNI_L_UWB_FRNK_FD_3 : 192|64@1+ (1,0) [0|0] ""  GW_BDC_FD,L_DHL_FD,L_DHRL_FD,L_DHRR_FD,L_DHR_FD,L_SAL_FD,L_TPMS_FD,L_UWB_BLE_MST_FD,L_UWB_BLE_SLV_FD,L_UWB_FL_FD,L_UWB_FR_FD,L_UWB_RL_FD,L_UWB_RR_FD,L_UWB_TRNK_FD,L_WPC_FD

BO_ 2549874722 NM_L_UWB_FL_FD: 32 L_UWB_FL_FD
 SG_ SNI_L_UWB_FL_FD : 0|8@1+ (1,0) [0|0] ""  GW_BDC_FD,L_DHL_FD,L_DHRL_FD,L_DHRR_FD,L_DHR_FD,L_SAL_FD,L_TPMS_FD,L_UWB_BLE_MST_FD,L_UWB_BLE_SLV_FD,L_UWB_FRNK_FD,L_UWB_FR_FD,L_UWB_RL_FD,L_UWB_RR_FD,L_UWB_TRNK_FD,L_WPC_FD
 SG_ CBV_RMR_L_UWB_FL_FD : 8|1@1+ (1,0) [0|0] ""  GW_BDC_FD,L_DHL_FD,L_DHRL_FD,L_DHRR_FD,L_DHR_FD,L_SAL_FD,L_TPMS_FD,L_UWB_BLE_MST_FD,L_UWB_BLE_SLV_FD,L_UWB_FRNK_FD,L_UWB_FR_FD,L_UWB_RL_FD,L_UWB_RR_FD,L_UWB_TRNK_FD,L_WPC_FD
 SG_ CBV_NMCoID_L_UWB_FL_FD : 9|2@1+ (1,0) [0|0] ""  GW_BDC_FD,L_DHL_FD,L_DHRL_FD,L_DHRR_FD,L_DHR_FD,L_SAL_FD,L_TPMS_FD,L_UWB_BLE_MST_FD,L_UWB_BLE_SLV_FD,L_UWB_FRNK_FD,L_UWB_FR_FD,L_UWB_RL_FD,L_UWB_RR_FD,L_UWB_TRNK_FD,L_WPC_FD
 SG_ CBV_NMCoSRB_L_UWB_FL_FD : 11|1@1+ (1,0) [0|0] ""  GW_BDC_FD,L_DHL_FD,L_DHRL_FD,L_DHRR_FD,L_DHR_FD,L_SAL_FD,L_TPMS_FD,L_UWB_BLE_MST_FD,L_UWB_BLE_SLV_FD,L_UWB_FRNK_FD,L_UWB_FR_FD,L_UWB_RL_FD,L_UWB_RR_FD,L_UWB_TRNK_FD,L_WPC_FD
 SG_ CBV_AWB_L_UWB_FL_FD : 12|1@1+ (1,0) [0|0] ""  GW_BDC_FD,L_DHL_FD,L_DHRL_FD,L_DHRR_FD,L_DHR_FD,L_SAL_FD,L_TPMS_FD,L_UWB_BLE_MST_FD,L_UWB_BLE_SLV_FD,L_UWB_FRNK_FD,L_UWB_FR_FD,L_UWB_RL_FD,L_UWB_RR_FD,L_UWB_TRNK_FD,L_WPC_FD
 SG_ CBV_PNIB_L_UWB_FL_FD : 14|1@1+ (1,0) [0|0] ""  GW_BDC_FD,L_DHL_FD,L_DHRL_FD,L_DHRR_FD,L_DHR_FD,L_SAL_FD,L_TPMS_FD,L_UWB_BLE_MST_FD,L_UWB_BLE_SLV_FD,L_UWB_FRNK_FD,L_UWB_FR_FD,L_UWB_RL_FD,L_UWB_RR_FD,L_UWB_TRNK_FD,L_WPC_FD
 SG_ NRR_L_UWB_FL_FD : 16|8@1+ (1,0) [0|0] ""  GW_BDC_FD,L_DHL_FD,L_DHRL_FD,L_DHRR_FD,L_DHR_FD,L_SAL_FD,L_TPMS_FD,L_UWB_BLE_MST_FD,L_UWB_BLE_SLV_FD,L_UWB_FRNK_FD,L_UWB_FR_FD,L_UWB_RL_FD,L_UWB_RR_FD,L_UWB_TRNK_FD,L_WPC_FD
 SG_ NM_State_L_UWB_FL_FD : 24|8@1+ (1,0) [0|0] ""  GW_BDC_FD,L_DHL_FD,L_DHRL_FD,L_DHRR_FD,L_DHR_FD,L_SAL_FD,L_TPMS_FD,L_UWB_BLE_MST_FD,L_UWB_BLE_SLV_FD,L_UWB_FRNK_FD,L_UWB_FR_FD,L_UWB_RL_FD,L_UWB_RR_FD,L_UWB_TRNK_FD,L_WPC_FD
 SG_ PNI_L_UWB_FL_FD : 32|32@1+ (1,0) [0|0] ""  GW_BDC_FD,L_DHL_FD,L_DHRL_FD,L_DHRR_FD,L_DHR_FD,L_SAL_FD,L_TPMS_FD,L_UWB_BLE_MST_FD,L_UWB_BLE_SLV_FD,L_UWB_FRNK_FD,L_UWB_FR_FD,L_UWB_RL_FD,L_UWB_RR_FD,L_UWB_TRNK_FD,L_WPC_FD
 SG_ PNI_L_UWB_FL_FD_1 : 64|64@1+ (1,0) [0|0] ""  GW_BDC_FD,L_DHL_FD,L_DHRL_FD,L_DHRR_FD,L_DHR_FD,L_SAL_FD,L_TPMS_FD,L_UWB_BLE_MST_FD,L_UWB_BLE_SLV_FD,L_UWB_FRNK_FD,L_UWB_FR_FD,L_UWB_RL_FD,L_UWB_RR_FD,L_UWB_TRNK_FD,L_WPC_FD
 SG_ PNI_L_UWB_FL_FD_2 : 128|64@1+ (1,0) [0|0] ""  GW_BDC_FD,L_DHL_FD,L_DHRL_FD,L_DHRR_FD,L_DHR_FD,L_SAL_FD,L_TPMS_FD,L_UWB_BLE_MST_FD,L_UWB_BLE_SLV_FD,L_UWB_FRNK_FD,L_UWB_FR_FD,L_UWB_RL_FD,L_UWB_RR_FD,L_UWB_TRNK_FD,L_WPC_FD
 SG_ PNI_L_UWB_FL_FD_3 : 192|64@1+ (1,0) [0|0] ""  GW_BDC_FD,L_DHL_FD,L_DHRL_FD,L_DHRR_FD,L_DHR_FD,L_SAL_FD,L_TPMS_FD,L_UWB_BLE_MST_FD,L_UWB_BLE_SLV_FD,L_UWB_FRNK_FD,L_UWB_FR_FD,L_UWB_RL_FD,L_UWB_RR_FD,L_UWB_TRNK_FD,L_WPC_FD

BO_ 2549874816 NM_GW_BDC_FD: 32 GW_BDC_FD
 SG_ SNI_GW_BDC_FD : 0|8@1+ (1,0) [0|0] ""  L_DHL_FD,L_DHRL_FD,L_DHRR_FD,L_DHR_FD,L_SAL_FD,L_TPMS_FD,L_UWB_BLE_MST_FD,L_UWB_BLE_SLV_FD,L_UWB_FL_FD,L_UWB_FRNK_FD,L_UWB_FR_FD,L_UWB_RL_FD,L_UWB_RR_FD,L_UWB_TRNK_FD,L_WPC_FD
 SG_ CBV_RMR_GW_BDC_FD : 8|1@1+ (1,0) [0|0] ""  L_DHL_FD,L_DHRL_FD,L_DHRR_FD,L_DHR_FD,L_SAL_FD,L_TPMS_FD,L_UWB_BLE_MST_FD,L_UWB_BLE_SLV_FD,L_UWB_FL_FD,L_UWB_FRNK_FD,L_UWB_FR_FD,L_UWB_RL_FD,L_UWB_RR_FD,L_UWB_TRNK_FD,L_WPC_FD
 SG_ CBV_NMCoID_GW_BDC_FD : 9|2@1+ (1,0) [0|0] ""  L_DHL_FD,L_DHRL_FD,L_DHRR_FD,L_DHR_FD,L_SAL_FD,L_TPMS_FD,L_UWB_BLE_MST_FD,L_UWB_BLE_SLV_FD,L_UWB_FL_FD,L_UWB_FRNK_FD,L_UWB_FR_FD,L_UWB_RL_FD,L_UWB_RR_FD,L_UWB_TRNK_FD,L_WPC_FD
 SG_ CBV_NMCoSRB_GW_BDC_FD : 11|1@1+ (1,0) [0|0] ""  L_DHL_FD,L_DHRL_FD,L_DHRR_FD,L_DHR_FD,L_SAL_FD,L_TPMS_FD,L_UWB_BLE_MST_FD,L_UWB_BLE_SLV_FD,L_UWB_FL_FD,L_UWB_FRNK_FD,L_UWB_FR_FD,L_UWB_RL_FD,L_UWB_RR_FD,L_UWB_TRNK_FD,L_WPC_FD
 SG_ CBV_AWB_GW_BDC_FD : 12|1@1+ (1,0) [0|0] ""  L_DHL_FD,L_DHRL_FD,L_DHRR_FD,L_DHR_FD,L_SAL_FD,L_TPMS_FD,L_UWB_BLE_MST_FD,L_UWB_BLE_SLV_FD,L_UWB_FL_FD,L_UWB_FRNK_FD,L_UWB_FR_FD,L_UWB_RL_FD,L_UWB_RR_FD,L_UWB_TRNK_FD,L_WPC_FD
 SG_ CBV_PNIB_GW_BDC_FD : 14|1@1+ (1,0) [0|0] ""  L_DHL_FD,L_DHRL_FD,L_DHRR_FD,L_DHR_FD,L_SAL_FD,L_TPMS_FD,L_UWB_BLE_MST_FD,L_UWB_BLE_SLV_FD,L_UWB_FL_FD,L_UWB_FRNK_FD,L_UWB_FR_FD,L_UWB_RL_FD,L_UWB_RR_FD,L_UWB_TRNK_FD,L_WPC_FD
 SG_ NRR_GW_BDC_FD : 16|8@1+ (1,0) [0|0] ""  L_DHL_FD,L_DHRL_FD,L_DHRR_FD,L_DHR_FD,L_SAL_FD,L_TPMS_FD,L_UWB_BLE_MST_FD,L_UWB_BLE_SLV_FD,L_UWB_FL_FD,L_UWB_FRNK_FD,L_UWB_FR_FD,L_UWB_RL_FD,L_UWB_RR_FD,L_UWB_TRNK_FD,L_WPC_FD
 SG_ NM_State_GW_BDC_FD : 24|8@1+ (1,0) [0|0] ""  L_DHL_FD,L_DHRL_FD,L_DHRR_FD,L_DHR_FD,L_SAL_FD,L_TPMS_FD,L_UWB_BLE_MST_FD,L_UWB_BLE_SLV_FD,L_UWB_FL_FD,L_UWB_FRNK_FD,L_UWB_FR_FD,L_UWB_RL_FD,L_UWB_RR_FD,L_UWB_TRNK_FD,L_WPC_FD
 SG_ PNI_GW_BDC_FD : 32|32@1+ (1,0) [0|0] ""  L_DHL_FD,L_DHRL_FD,L_DHRR_FD,L_DHR_FD,L_SAL_FD,L_TPMS_FD,L_UWB_BLE_MST_FD,L_UWB_BLE_SLV_FD,L_UWB_FL_FD,L_UWB_FRNK_FD,L_UWB_FR_FD,L_UWB_RL_FD,L_UWB_RR_FD,L_UWB_TRNK_FD,L_WPC_FD
 SG_ PNI_GW_BDC_FD_1 : 64|64@1+ (1,0) [0|0] ""  L_DHL_FD,L_DHRL_FD,L_DHRR_FD,L_DHR_FD,L_SAL_FD,L_TPMS_FD,L_UWB_BLE_MST_FD,L_UWB_BLE_SLV_FD,L_UWB_FL_FD,L_UWB_FRNK_FD,L_UWB_FR_FD,L_UWB_RL_FD,L_UWB_RR_FD,L_UWB_TRNK_FD,L_WPC_FD
 SG_ PNI_GW_BDC_FD_2 : 128|64@1+ (1,0) [0|0] ""  L_DHL_FD,L_DHRL_FD,L_DHRR_FD,L_DHR_FD,L_SAL_FD,L_TPMS_FD,L_UWB_BLE_MST_FD,L_UWB_BLE_SLV_FD,L_UWB_FL_FD,L_UWB_FRNK_FD,L_UWB_FR_FD,L_UWB_RL_FD,L_UWB_RR_FD,L_UWB_TRNK_FD,L_WPC_FD
 SG_ PNI_GW_BDC_FD_3 : 192|64@1+ (1,0) [0|0] ""  L_DHL_FD,L_DHRL_FD,L_DHRR_FD,L_DHR_FD,L_SAL_FD,L_TPMS_FD,L_UWB_BLE_MST_FD,L_UWB_BLE_SLV_FD,L_UWB_FL_FD,L_UWB_FRNK_FD,L_UWB_FR_FD,L_UWB_RL_FD,L_UWB_RR_FD,L_UWB_TRNK_FD,L_WPC_FD

BO_ 2549874725 NM_L_UWB_RL_FD: 32 L_UWB_RL_FD
 SG_ SNI_L_UWB_RL_FD : 0|8@1+ (1,0) [0|0] ""  GW_BDC_FD,L_DHL_FD,L_DHRL_FD,L_DHRR_FD,L_DHR_FD,L_SAL_FD,L_TPMS_FD,L_UWB_BLE_MST_FD,L_UWB_BLE_SLV_FD,L_UWB_FL_FD,L_UWB_FRNK_FD,L_UWB_FR_FD,L_UWB_RR_FD,L_UWB_TRNK_FD,L_WPC_FD
 SG_ CBV_RMR_L_UWB_RL_FD : 8|1@1+ (1,0) [0|0] ""  GW_BDC_FD,L_DHL_FD,L_DHRL_FD,L_DHRR_FD,L_DHR_FD,L_SAL_FD,L_TPMS_FD,L_UWB_BLE_MST_FD,L_UWB_BLE_SLV_FD,L_UWB_FL_FD,L_UWB_FRNK_FD,L_UWB_FR_FD,L_UWB_RR_FD,L_UWB_TRNK_FD,L_WPC_FD
 SG_ CBV_NMCoID_L_UWB_RL_FD : 9|2@1+ (1,0) [0|0] ""  GW_BDC_FD,L_DHL_FD,L_DHRL_FD,L_DHRR_FD,L_DHR_FD,L_SAL_FD,L_TPMS_FD,L_UWB_BLE_MST_FD,L_UWB_BLE_SLV_FD,L_UWB_FL_FD,L_UWB_FRNK_FD,L_UWB_FR_FD,L_UWB_RR_FD,L_UWB_TRNK_FD,L_WPC_FD
 SG_ CBV_NMCoSRB_L_UWB_RL_FD : 11|1@1+ (1,0) [0|0] ""  GW_BDC_FD,L_DHL_FD,L_DHRL_FD,L_DHRR_FD,L_DHR_FD,L_SAL_FD,L_TPMS_FD,L_UWB_BLE_MST_FD,L_UWB_BLE_SLV_FD,L_UWB_FL_FD,L_UWB_FRNK_FD,L_UWB_FR_FD,L_UWB_RR_FD,L_UWB_TRNK_FD,L_WPC_FD
 SG_ CBV_AWB_L_UWB_RL_FD : 12|1@1+ (1,0) [0|0] ""  GW_BDC_FD,L_DHL_FD,L_DHRL_FD,L_DHRR_FD,L_DHR_FD,L_SAL_FD,L_TPMS_FD,L_UWB_BLE_MST_FD,L_UWB_BLE_SLV_FD,L_UWB_FL_FD,L_UWB_FRNK_FD,L_UWB_FR_FD,L_UWB_RR_FD,L_UWB_TRNK_FD,L_WPC_FD
 SG_ CBV_PNIB_L_UWB_RL_FD : 14|1@1+ (1,0) [0|0] ""  GW_BDC_FD,L_DHL_FD,L_DHRL_FD,L_DHRR_FD,L_DHR_FD,L_SAL_FD,L_TPMS_FD,L_UWB_BLE_MST_FD,L_UWB_BLE_SLV_FD,L_UWB_FL_FD,L_UWB_FRNK_FD,L_UWB_FR_FD,L_UWB_RR_FD,L_UWB_TRNK_FD,L_WPC_FD
 SG_ NRR_L_UWB_RL_FD : 16|8@1+ (1,0) [0|0] ""  GW_BDC_FD,L_DHL_FD,L_DHRL_FD,L_DHRR_FD,L_DHR_FD,L_SAL_FD,L_TPMS_FD,L_UWB_BLE_MST_FD,L_UWB_BLE_SLV_FD,L_UWB_FL_FD,L_UWB_FRNK_FD,L_UWB_FR_FD,L_UWB_RR_FD,L_UWB_TRNK_FD,L_WPC_FD
 SG_ NM_State_L_UWB_RL_FD : 24|8@1+ (1,0) [0|0] ""  GW_BDC_FD,L_DHL_FD,L_DHRL_FD,L_DHRR_FD,L_DHR_FD,L_SAL_FD,L_TPMS_FD,L_UWB_BLE_MST_FD,L_UWB_BLE_SLV_FD,L_UWB_FL_FD,L_UWB_FRNK_FD,L_UWB_FR_FD,L_UWB_RR_FD,L_UWB_TRNK_FD,L_WPC_FD
 SG_ PNI_L_UWB_RL_FD : 32|32@1+ (1,0) [0|0] ""  GW_BDC_FD,L_DHL_FD,L_DHRL_FD,L_DHRR_FD,L_DHR_FD,L_SAL_FD,L_TPMS_FD,L_UWB_BLE_MST_FD,L_UWB_BLE_SLV_FD,L_UWB_FL_FD,L_UWB_FRNK_FD,L_UWB_FR_FD,L_UWB_RR_FD,L_UWB_TRNK_FD,L_WPC_FD
 SG_ PNI_L_UWB_RL_FD_1 : 64|64@1+ (1,0) [0|0] ""  GW_BDC_FD,L_DHL_FD,L_DHRL_FD,L_DHRR_FD,L_DHR_FD,L_SAL_FD,L_TPMS_FD,L_UWB_BLE_MST_FD,L_UWB_BLE_SLV_FD,L_UWB_FL_FD,L_UWB_FRNK_FD,L_UWB_FR_FD,L_UWB_RR_FD,L_UWB_TRNK_FD,L_WPC_FD
 SG_ PNI_L_UWB_RL_FD_2 : 128|64@1+ (1,0) [0|0] ""  GW_BDC_FD,L_DHL_FD,L_DHRL_FD,L_DHRR_FD,L_DHR_FD,L_SAL_FD,L_TPMS_FD,L_UWB_BLE_MST_FD,L_UWB_BLE_SLV_FD,L_UWB_FL_FD,L_UWB_FRNK_FD,L_UWB_FR_FD,L_UWB_RR_FD,L_UWB_TRNK_FD,L_WPC_FD
 SG_ PNI_L_UWB_RL_FD_3 : 192|64@1+ (1,0) [0|0] ""  GW_BDC_FD,L_DHL_FD,L_DHRL_FD,L_DHRR_FD,L_DHR_FD,L_SAL_FD,L_TPMS_FD,L_UWB_BLE_MST_FD,L_UWB_BLE_SLV_FD,L_UWB_FL_FD,L_UWB_FRNK_FD,L_UWB_FR_FD,L_UWB_RR_FD,L_UWB_TRNK_FD,L_WPC_FD

BO_ 2549874857 NM_L_SAL_FD: 32 L_SAL_FD
 SG_ SNI_L_SAL_FD : 0|8@1+ (1,0) [0|0] ""  GW_BDC_FD,L_DHL_FD,L_DHRL_FD,L_DHRR_FD,L_DHR_FD,L_TPMS_FD,L_UWB_BLE_MST_FD,L_UWB_BLE_SLV_FD,L_UWB_FL_FD,L_UWB_FRNK_FD,L_UWB_FR_FD,L_UWB_RL_FD,L_UWB_RR_FD,L_UWB_TRNK_FD,L_WPC_FD
 SG_ CBV_RMR_L_SAL_FD : 8|1@1+ (1,0) [0|0] ""  GW_BDC_FD,L_DHL_FD,L_DHRL_FD,L_DHRR_FD,L_DHR_FD,L_TPMS_FD,L_UWB_BLE_MST_FD,L_UWB_BLE_SLV_FD,L_UWB_FL_FD,L_UWB_FRNK_FD,L_UWB_FR_FD,L_UWB_RL_FD,L_UWB_RR_FD,L_UWB_TRNK_FD,L_WPC_FD
 SG_ CBV_NMCoID_L_SAL_FD : 9|2@1+ (1,0) [0|0] ""  GW_BDC_FD,L_DHL_FD,L_DHRL_FD,L_DHRR_FD,L_DHR_FD,L_TPMS_FD,L_UWB_BLE_MST_FD,L_UWB_BLE_SLV_FD,L_UWB_FL_FD,L_UWB_FRNK_FD,L_UWB_FR_FD,L_UWB_RL_FD,L_UWB_RR_FD,L_UWB_TRNK_FD,L_WPC_FD
 SG_ CBV_NMCoSRB_L_SAL_FD : 11|1@1+ (1,0) [0|0] ""  GW_BDC_FD,L_DHL_FD,L_DHRL_FD,L_DHRR_FD,L_DHR_FD,L_TPMS_FD,L_UWB_BLE_MST_FD,L_UWB_BLE_SLV_FD,L_UWB_FL_FD,L_UWB_FRNK_FD,L_UWB_FR_FD,L_UWB_RL_FD,L_UWB_RR_FD,L_UWB_TRNK_FD,L_WPC_FD
 SG_ CBV_AWB_L_SAL_FD : 12|1@1+ (1,0) [0|0] ""  GW_BDC_FD,L_DHL_FD,L_DHRL_FD,L_DHRR_FD,L_DHR_FD,L_TPMS_FD,L_UWB_BLE_MST_FD,L_UWB_BLE_SLV_FD,L_UWB_FL_FD,L_UWB_FRNK_FD,L_UWB_FR_FD,L_UWB_RL_FD,L_UWB_RR_FD,L_UWB_TRNK_FD,L_WPC_FD
 SG_ CBV_PNIB_L_SAL_FD : 14|1@1+ (1,0) [0|0] ""  GW_BDC_FD,L_DHL_FD,L_DHRL_FD,L_DHRR_FD,L_DHR_FD,L_TPMS_FD,L_UWB_BLE_MST_FD,L_UWB_BLE_SLV_FD,L_UWB_FL_FD,L_UWB_FRNK_FD,L_UWB_FR_FD,L_UWB_RL_FD,L_UWB_RR_FD,L_UWB_TRNK_FD,L_WPC_FD
 SG_ NRR_L_SAL_FD : 16|8@1+ (1,0) [0|0] ""  GW_BDC_FD,L_DHL_FD,L_DHRL_FD,L_DHRR_FD,L_DHR_FD,L_TPMS_FD,L_UWB_BLE_MST_FD,L_UWB_BLE_SLV_FD,L_UWB_FL_FD,L_UWB_FRNK_FD,L_UWB_FR_FD,L_UWB_RL_FD,L_UWB_RR_FD,L_UWB_TRNK_FD,L_WPC_FD
 SG_ NM_State_L_SAL_FD : 24|8@1+ (1,0) [0|0] ""  GW_BDC_FD,L_DHL_FD,L_DHRL_FD,L_DHRR_FD,L_DHR_FD,L_TPMS_FD,L_UWB_BLE_MST_FD,L_UWB_BLE_SLV_FD,L_UWB_FL_FD,L_UWB_FRNK_FD,L_UWB_FR_FD,L_UWB_RL_FD,L_UWB_RR_FD,L_UWB_TRNK_FD,L_WPC_FD
 SG_ PNI_L_SAL_FD : 32|32@1+ (1,0) [0|0] ""  GW_BDC_FD,L_DHL_FD,L_DHRL_FD,L_DHRR_FD,L_DHR_FD,L_TPMS_FD,L_UWB_BLE_MST_FD,L_UWB_BLE_SLV_FD,L_UWB_FL_FD,L_UWB_FRNK_FD,L_UWB_FR_FD,L_UWB_RL_FD,L_UWB_RR_FD,L_UWB_TRNK_FD,L_WPC_FD
 SG_ PNI_L_SAL_FD_1 : 64|64@1+ (1,0) [0|0] ""  GW_BDC_FD,L_DHL_FD,L_DHRL_FD,L_DHRR_FD,L_DHR_FD,L_TPMS_FD,L_UWB_BLE_MST_FD,L_UWB_BLE_SLV_FD,L_UWB_FL_FD,L_UWB_FRNK_FD,L_UWB_FR_FD,L_UWB_RL_FD,L_UWB_RR_FD,L_UWB_TRNK_FD,L_WPC_FD
 SG_ PNI_L_SAL_FD_2 : 128|64@1+ (1,0) [0|0] ""  GW_BDC_FD,L_DHL_FD,L_DHRL_FD,L_DHRR_FD,L_DHR_FD,L_TPMS_FD,L_UWB_BLE_MST_FD,L_UWB_BLE_SLV_FD,L_UWB_FL_FD,L_UWB_FRNK_FD,L_UWB_FR_FD,L_UWB_RL_FD,L_UWB_RR_FD,L_UWB_TRNK_FD,L_WPC_FD
 SG_ PNI_L_SAL_FD_3 : 192|64@1+ (1,0) [0|0] ""  GW_BDC_FD,L_DHL_FD,L_DHRL_FD,L_DHRR_FD,L_DHR_FD,L_TPMS_FD,L_UWB_BLE_MST_FD,L_UWB_BLE_SLV_FD,L_UWB_FL_FD,L_UWB_FRNK_FD,L_UWB_FR_FD,L_UWB_RL_FD,L_UWB_RR_FD,L_UWB_TRNK_FD,L_WPC_FD

BO_ 2549874718 NM_L_WPC_FD: 32 L_WPC_FD
 SG_ SNI_L_WPC_FD : 0|8@1+ (1,0) [0|0] ""  GW_BDC_FD,L_DHL_FD,L_DHRL_FD,L_DHRR_FD,L_DHR_FD,L_SAL_FD,L_TPMS_FD,L_UWB_BLE_MST_FD,L_UWB_BLE_SLV_FD,L_UWB_FL_FD,L_UWB_FRNK_FD,L_UWB_FR_FD,L_UWB_RL_FD,L_UWB_RR_FD,L_UWB_TRNK_FD
 SG_ CBV_RMR_L_WPC_FD : 8|1@1+ (1,0) [0|0] ""  GW_BDC_FD,L_DHL_FD,L_DHRL_FD,L_DHRR_FD,L_DHR_FD,L_SAL_FD,L_TPMS_FD,L_UWB_BLE_MST_FD,L_UWB_BLE_SLV_FD,L_UWB_FL_FD,L_UWB_FRNK_FD,L_UWB_FR_FD,L_UWB_RL_FD,L_UWB_RR_FD,L_UWB_TRNK_FD
 SG_ CBV_NMCoID_L_WPC_FD : 9|2@1+ (1,0) [0|0] ""  GW_BDC_FD,L_DHL_FD,L_DHRL_FD,L_DHRR_FD,L_DHR_FD,L_SAL_FD,L_TPMS_FD,L_UWB_BLE_MST_FD,L_UWB_BLE_SLV_FD,L_UWB_FL_FD,L_UWB_FRNK_FD,L_UWB_FR_FD,L_UWB_RL_FD,L_UWB_RR_FD,L_UWB_TRNK_FD
 SG_ CBV_NMCoSRB_L_WPC_FD : 11|1@1+ (1,0) [0|0] ""  GW_BDC_FD,L_DHL_FD,L_DHRL_FD,L_DHRR_FD,L_DHR_FD,L_SAL_FD,L_TPMS_FD,L_UWB_BLE_MST_FD,L_UWB_BLE_SLV_FD,L_UWB_FL_FD,L_UWB_FRNK_FD,L_UWB_FR_FD,L_UWB_RL_FD,L_UWB_RR_FD,L_UWB_TRNK_FD
 SG_ CBV_AWB_L_WPC_FD : 12|1@1+ (1,0) [0|0] ""  GW_BDC_FD,L_DHL_FD,L_DHRL_FD,L_DHRR_FD,L_DHR_FD,L_SAL_FD,L_TPMS_FD,L_UWB_BLE_MST_FD,L_UWB_BLE_SLV_FD,L_UWB_FL_FD,L_UWB_FRNK_FD,L_UWB_FR_FD,L_UWB_RL_FD,L_UWB_RR_FD,L_UWB_TRNK_FD
 SG_ CBV_PNIB_L_WPC_FD : 14|1@1+ (1,0) [0|0] ""  GW_BDC_FD,L_DHL_FD,L_DHRL_FD,L_DHRR_FD,L_DHR_FD,L_SAL_FD,L_TPMS_FD,L_UWB_BLE_MST_FD,L_UWB_BLE_SLV_FD,L_UWB_FL_FD,L_UWB_FRNK_FD,L_UWB_FR_FD,L_UWB_RL_FD,L_UWB_RR_FD,L_UWB_TRNK_FD
 SG_ NRR_L_WPC_FD : 16|8@1+ (1,0) [0|0] ""  GW_BDC_FD,L_DHL_FD,L_DHRL_FD,L_DHRR_FD,L_DHR_FD,L_SAL_FD,L_TPMS_FD,L_UWB_BLE_MST_FD,L_UWB_BLE_SLV_FD,L_UWB_FL_FD,L_UWB_FRNK_FD,L_UWB_FR_FD,L_UWB_RL_FD,L_UWB_RR_FD,L_UWB_TRNK_FD
 SG_ NM_State_L_WPC_FD : 24|8@1+ (1,0) [0|0] ""  GW_BDC_FD,L_DHL_FD,L_DHRL_FD,L_DHRR_FD,L_DHR_FD,L_SAL_FD,L_TPMS_FD,L_UWB_BLE_MST_FD,L_UWB_BLE_SLV_FD,L_UWB_FL_FD,L_UWB_FRNK_FD,L_UWB_FR_FD,L_UWB_RL_FD,L_UWB_RR_FD,L_UWB_TRNK_FD
 SG_ PNI_L_WPC_FD : 32|32@1+ (1,0) [0|0] ""  GW_BDC_FD,L_DHL_FD,L_DHRL_FD,L_DHRR_FD,L_DHR_FD,L_SAL_FD,L_TPMS_FD,L_UWB_BLE_MST_FD,L_UWB_BLE_SLV_FD,L_UWB_FL_FD,L_UWB_FRNK_FD,L_UWB_FR_FD,L_UWB_RL_FD,L_UWB_RR_FD,L_UWB_TRNK_FD
 SG_ PNI_L_WPC_FD_1 : 64|64@1+ (1,0) [0|0] ""  GW_BDC_FD,L_DHL_FD,L_DHRL_FD,L_DHRR_FD,L_DHR_FD,L_SAL_FD,L_TPMS_FD,L_UWB_BLE_MST_FD,L_UWB_BLE_SLV_FD,L_UWB_FL_FD,L_UWB_FRNK_FD,L_UWB_FR_FD,L_UWB_RL_FD,L_UWB_RR_FD,L_UWB_TRNK_FD
 SG_ PNI_L_WPC_FD_2 : 128|64@1+ (1,0) [0|0] ""  GW_BDC_FD,L_DHL_FD,L_DHRL_FD,L_DHRR_FD,L_DHR_FD,L_SAL_FD,L_TPMS_FD,L_UWB_BLE_MST_FD,L_UWB_BLE_SLV_FD,L_UWB_FL_FD,L_UWB_FRNK_FD,L_UWB_FR_FD,L_UWB_RL_FD,L_UWB_RR_FD,L_UWB_TRNK_FD
 SG_ PNI_L_WPC_FD_3 : 192|64@1+ (1,0) [0|0] ""  GW_BDC_FD,L_DHL_FD,L_DHRL_FD,L_DHRR_FD,L_DHR_FD,L_SAL_FD,L_TPMS_FD,L_UWB_BLE_MST_FD,L_UWB_BLE_SLV_FD,L_UWB_FL_FD,L_UWB_FRNK_FD,L_UWB_FR_FD,L_UWB_RL_FD,L_UWB_RR_FD,L_UWB_TRNK_FD

BO_ 2549874728 NM_L_TPMS_FD: 32 L_TPMS_FD
 SG_ SNI_L_TPMS_FD : 0|8@1+ (1,0) [0|0] ""  GW_BDC_FD,L_DHL_FD,L_DHRL_FD,L_DHRR_FD,L_DHR_FD,L_SAL_FD,L_UWB_BLE_MST_FD,L_UWB_BLE_SLV_FD,L_UWB_FL_FD,L_UWB_FRNK_FD,L_UWB_FR_FD,L_UWB_RL_FD,L_UWB_RR_FD,L_UWB_TRNK_FD,L_WPC_FD
 SG_ CBV_RMR_L_TPMS_FD : 8|1@1+ (1,0) [0|0] ""  GW_BDC_FD,L_DHL_FD,L_DHRL_FD,L_DHRR_FD,L_DHR_FD,L_SAL_FD,L_UWB_BLE_MST_FD,L_UWB_BLE_SLV_FD,L_UWB_FL_FD,L_UWB_FRNK_FD,L_UWB_FR_FD,L_UWB_RL_FD,L_UWB_RR_FD,L_UWB_TRNK_FD,L_WPC_FD
 SG_ CBV_NMCoID_L_TPMS_FD : 9|2@1+ (1,0) [0|0] ""  GW_BDC_FD,L_DHL_FD,L_DHRL_FD,L_DHRR_FD,L_DHR_FD,L_SAL_FD,L_UWB_BLE_MST_FD,L_UWB_BLE_SLV_FD,L_UWB_FL_FD,L_UWB_FRNK_FD,L_UWB_FR_FD,L_UWB_RL_FD,L_UWB_RR_FD,L_UWB_TRNK_FD,L_WPC_FD
 SG_ CBV_NMCoSRB_L_TPMS_FD : 11|1@1+ (1,0) [0|0] ""  GW_BDC_FD,L_DHL_FD,L_DHRL_FD,L_DHRR_FD,L_DHR_FD,L_SAL_FD,L_UWB_BLE_MST_FD,L_UWB_BLE_SLV_FD,L_UWB_FL_FD,L_UWB_FRNK_FD,L_UWB_FR_FD,L_UWB_RL_FD,L_UWB_RR_FD,L_UWB_TRNK_FD,L_WPC_FD
 SG_ CBV_AWB_L_TPMS_FD : 12|1@1+ (1,0) [0|0] ""  GW_BDC_FD,L_DHL_FD,L_DHRL_FD,L_DHRR_FD,L_DHR_FD,L_SAL_FD,L_UWB_BLE_MST_FD,L_UWB_BLE_SLV_FD,L_UWB_FL_FD,L_UWB_FRNK_FD,L_UWB_FR_FD,L_UWB_RL_FD,L_UWB_RR_FD,L_UWB_TRNK_FD,L_WPC_FD
 SG_ CBV_PNIB_L_TPMS_FD : 14|1@1+ (1,0) [0|0] ""  GW_BDC_FD,L_DHL_FD,L_DHRL_FD,L_DHRR_FD,L_DHR_FD,L_SAL_FD,L_UWB_BLE_MST_FD,L_UWB_BLE_SLV_FD,L_UWB_FL_FD,L_UWB_FRNK_FD,L_UWB_FR_FD,L_UWB_RL_FD,L_UWB_RR_FD,L_UWB_TRNK_FD,L_WPC_FD
 SG_ NRR_L_TPMS_FD : 16|8@1+ (1,0) [0|0] ""  GW_BDC_FD,L_DHL_FD,L_DHRL_FD,L_DHRR_FD,L_DHR_FD,L_SAL_FD,L_UWB_BLE_MST_FD,L_UWB_BLE_SLV_FD,L_UWB_FL_FD,L_UWB_FRNK_FD,L_UWB_FR_FD,L_UWB_RL_FD,L_UWB_RR_FD,L_UWB_TRNK_FD,L_WPC_FD
 SG_ NM_State_L_TPMS_FD : 24|8@1+ (1,0) [0|0] ""  GW_BDC_FD,L_DHL_FD,L_DHRL_FD,L_DHRR_FD,L_DHR_FD,L_SAL_FD,L_UWB_BLE_MST_FD,L_UWB_BLE_SLV_FD,L_UWB_FL_FD,L_UWB_FRNK_FD,L_UWB_FR_FD,L_UWB_RL_FD,L_UWB_RR_FD,L_UWB_TRNK_FD,L_WPC_FD
 SG_ PNI_L_TPMS_FD : 32|32@1+ (1,0) [0|0] ""  GW_BDC_FD,L_DHL_FD,L_DHRL_FD,L_DHRR_FD,L_DHR_FD,L_SAL_FD,L_UWB_BLE_MST_FD,L_UWB_BLE_SLV_FD,L_UWB_FL_FD,L_UWB_FRNK_FD,L_UWB_FR_FD,L_UWB_RL_FD,L_UWB_RR_FD,L_UWB_TRNK_FD,L_WPC_FD
 SG_ PNI_L_TPMS_FD_1 : 64|64@1+ (1,0) [0|0] ""  GW_BDC_FD,L_DHL_FD,L_DHRL_FD,L_DHRR_FD,L_DHR_FD,L_SAL_FD,L_UWB_BLE_MST_FD,L_UWB_BLE_SLV_FD,L_UWB_FL_FD,L_UWB_FRNK_FD,L_UWB_FR_FD,L_UWB_RL_FD,L_UWB_RR_FD,L_UWB_TRNK_FD,L_WPC_FD
 SG_ PNI_L_TPMS_FD_2 : 128|64@1+ (1,0) [0|0] ""  GW_BDC_FD,L_DHL_FD,L_DHRL_FD,L_DHRR_FD,L_DHR_FD,L_SAL_FD,L_UWB_BLE_MST_FD,L_UWB_BLE_SLV_FD,L_UWB_FL_FD,L_UWB_FRNK_FD,L_UWB_FR_FD,L_UWB_RL_FD,L_UWB_RR_FD,L_UWB_TRNK_FD,L_WPC_FD
 SG_ PNI_L_TPMS_FD_3 : 192|64@1+ (1,0) [0|0] ""  GW_BDC_FD,L_DHL_FD,L_DHRL_FD,L_DHRR_FD,L_DHR_FD,L_SAL_FD,L_UWB_BLE_MST_FD,L_UWB_BLE_SLV_FD,L_UWB_FL_FD,L_UWB_FRNK_FD,L_UWB_FR_FD,L_UWB_RL_FD,L_UWB_RR_FD,L_UWB_TRNK_FD,L_WPC_FD

BO_ 2549874730 NM_L_DHL_FD: 32 L_DHL_FD
 SG_ SNI_L_DHL_FD : 0|8@1+ (1,0) [0|0] ""  GW_BDC_FD,L_DHRL_FD,L_DHRR_FD,L_DHR_FD,L_SAL_FD,L_TPMS_FD,L_UWB_BLE_MST_FD,L_UWB_BLE_SLV_FD,L_UWB_FL_FD,L_UWB_FRNK_FD,L_UWB_FR_FD,L_UWB_RL_FD,L_UWB_RR_FD,L_UWB_TRNK_FD,L_WPC_FD
 SG_ CBV_RMR_L_DHL_FD : 8|1@1+ (1,0) [0|0] ""  GW_BDC_FD,L_DHRL_FD,L_DHRR_FD,L_DHR_FD,L_SAL_FD,L_TPMS_FD,L_UWB_BLE_MST_FD,L_UWB_BLE_SLV_FD,L_UWB_FL_FD,L_UWB_FRNK_FD,L_UWB_FR_FD,L_UWB_RL_FD,L_UWB_RR_FD,L_UWB_TRNK_FD,L_WPC_FD
 SG_ CBV_NMCoID_L_DHL_FD : 9|2@1+ (1,0) [0|0] ""  GW_BDC_FD,L_DHRL_FD,L_DHRR_FD,L_DHR_FD,L_SAL_FD,L_TPMS_FD,L_UWB_BLE_MST_FD,L_UWB_BLE_SLV_FD,L_UWB_FL_FD,L_UWB_FRNK_FD,L_UWB_FR_FD,L_UWB_RL_FD,L_UWB_RR_FD,L_UWB_TRNK_FD,L_WPC_FD
 SG_ CBV_NMCoSRB_L_DHL_FD : 11|1@1+ (1,0) [0|0] ""  GW_BDC_FD,L_DHRL_FD,L_DHRR_FD,L_DHR_FD,L_SAL_FD,L_TPMS_FD,L_UWB_BLE_MST_FD,L_UWB_BLE_SLV_FD,L_UWB_FL_FD,L_UWB_FRNK_FD,L_UWB_FR_FD,L_UWB_RL_FD,L_UWB_RR_FD,L_UWB_TRNK_FD,L_WPC_FD
 SG_ CBV_AWB_L_DHL_FD : 12|1@1+ (1,0) [0|0] ""  GW_BDC_FD,L_DHRL_FD,L_DHRR_FD,L_DHR_FD,L_SAL_FD,L_TPMS_FD,L_UWB_BLE_MST_FD,L_UWB_BLE_SLV_FD,L_UWB_FL_FD,L_UWB_FRNK_FD,L_UWB_FR_FD,L_UWB_RL_FD,L_UWB_RR_FD,L_UWB_TRNK_FD,L_WPC_FD
 SG_ CBV_PNIB_L_DHL_FD : 14|1@1+ (1,0) [0|0] ""  GW_BDC_FD,L_DHRL_FD,L_DHRR_FD,L_DHR_FD,L_SAL_FD,L_TPMS_FD,L_UWB_BLE_MST_FD,L_UWB_BLE_SLV_FD,L_UWB_FL_FD,L_UWB_FRNK_FD,L_UWB_FR_FD,L_UWB_RL_FD,L_UWB_RR_FD,L_UWB_TRNK_FD,L_WPC_FD
 SG_ NRR_L_DHL_FD : 16|8@1+ (1,0) [0|0] ""  GW_BDC_FD,L_DHRL_FD,L_DHRR_FD,L_DHR_FD,L_SAL_FD,L_TPMS_FD,L_UWB_BLE_MST_FD,L_UWB_BLE_SLV_FD,L_UWB_FL_FD,L_UWB_FRNK_FD,L_UWB_FR_FD,L_UWB_RL_FD,L_UWB_RR_FD,L_UWB_TRNK_FD,L_WPC_FD
 SG_ NM_State_L_DHL_FD : 24|8@1+ (1,0) [0|0] ""  GW_BDC_FD,L_DHRL_FD,L_DHRR_FD,L_DHR_FD,L_SAL_FD,L_TPMS_FD,L_UWB_BLE_MST_FD,L_UWB_BLE_SLV_FD,L_UWB_FL_FD,L_UWB_FRNK_FD,L_UWB_FR_FD,L_UWB_RL_FD,L_UWB_RR_FD,L_UWB_TRNK_FD,L_WPC_FD
 SG_ PNI_L_DHL_FD : 32|32@1+ (1,0) [0|0] ""  GW_BDC_FD,L_DHRL_FD,L_DHRR_FD,L_DHR_FD,L_SAL_FD,L_TPMS_FD,L_UWB_BLE_MST_FD,L_UWB_BLE_SLV_FD,L_UWB_FL_FD,L_UWB_FRNK_FD,L_UWB_FR_FD,L_UWB_RL_FD,L_UWB_RR_FD,L_UWB_TRNK_FD,L_WPC_FD
 SG_ PNI_L_DHL_FD_1 : 64|64@1+ (1,0) [0|0] ""  GW_BDC_FD,L_DHRL_FD,L_DHRR_FD,L_DHR_FD,L_SAL_FD,L_TPMS_FD,L_UWB_BLE_MST_FD,L_UWB_BLE_SLV_FD,L_UWB_FL_FD,L_UWB_FRNK_FD,L_UWB_FR_FD,L_UWB_RL_FD,L_UWB_RR_FD,L_UWB_TRNK_FD,L_WPC_FD
 SG_ PNI_L_DHL_FD_2 : 128|64@1+ (1,0) [0|0] ""  GW_BDC_FD,L_DHRL_FD,L_DHRR_FD,L_DHR_FD,L_SAL_FD,L_TPMS_FD,L_UWB_BLE_MST_FD,L_UWB_BLE_SLV_FD,L_UWB_FL_FD,L_UWB_FRNK_FD,L_UWB_FR_FD,L_UWB_RL_FD,L_UWB_RR_FD,L_UWB_TRNK_FD,L_WPC_FD
 SG_ PNI_L_DHL_FD_3 : 192|64@1+ (1,0) [0|0] ""  GW_BDC_FD,L_DHRL_FD,L_DHRR_FD,L_DHR_FD,L_SAL_FD,L_TPMS_FD,L_UWB_BLE_MST_FD,L_UWB_BLE_SLV_FD,L_UWB_FL_FD,L_UWB_FRNK_FD,L_UWB_FR_FD,L_UWB_RL_FD,L_UWB_RR_FD,L_UWB_TRNK_FD,L_WPC_FD

BO_ 2549874731 NM_L_DHR_FD: 32 L_DHR_FD
 SG_ SNI_L_DHR_FD : 0|8@1+ (1,0) [0|0] ""  GW_BDC_FD,L_DHL_FD,L_DHRL_FD,L_DHRR_FD,L_SAL_FD,L_TPMS_FD,L_UWB_BLE_MST_FD,L_UWB_BLE_SLV_FD,L_UWB_FL_FD,L_UWB_FRNK_FD,L_UWB_FR_FD,L_UWB_RL_FD,L_UWB_RR_FD,L_UWB_TRNK_FD,L_WPC_FD
 SG_ CBV_RMR_L_DHR_FD : 8|1@1+ (1,0) [0|0] ""  GW_BDC_FD,L_DHL_FD,L_DHRL_FD,L_DHRR_FD,L_SAL_FD,L_TPMS_FD,L_UWB_BLE_MST_FD,L_UWB_BLE_SLV_FD,L_UWB_FL_FD,L_UWB_FRNK_FD,L_UWB_FR_FD,L_UWB_RL_FD,L_UWB_RR_FD,L_UWB_TRNK_FD,L_WPC_FD
 SG_ CBV_NMCoID_L_DHR_FD : 9|2@1+ (1,0) [0|0] ""  GW_BDC_FD,L_DHL_FD,L_DHRL_FD,L_DHRR_FD,L_SAL_FD,L_TPMS_FD,L_UWB_BLE_MST_FD,L_UWB_BLE_SLV_FD,L_UWB_FL_FD,L_UWB_FRNK_FD,L_UWB_FR_FD,L_UWB_RL_FD,L_UWB_RR_FD,L_UWB_TRNK_FD,L_WPC_FD
 SG_ CBV_NMCoSRB_L_DHR_FD : 11|1@1+ (1,0) [0|0] ""  GW_BDC_FD,L_DHL_FD,L_DHRL_FD,L_DHRR_FD,L_SAL_FD,L_TPMS_FD,L_UWB_BLE_MST_FD,L_UWB_BLE_SLV_FD,L_UWB_FL_FD,L_UWB_FRNK_FD,L_UWB_FR_FD,L_UWB_RL_FD,L_UWB_RR_FD,L_UWB_TRNK_FD,L_WPC_FD
 SG_ CBV_AWB_L_DHR_FD : 12|1@1+ (1,0) [0|0] ""  GW_BDC_FD,L_DHL_FD,L_DHRL_FD,L_DHRR_FD,L_SAL_FD,L_TPMS_FD,L_UWB_BLE_MST_FD,L_UWB_BLE_SLV_FD,L_UWB_FL_FD,L_UWB_FRNK_FD,L_UWB_FR_FD,L_UWB_RL_FD,L_UWB_RR_FD,L_UWB_TRNK_FD,L_WPC_FD
 SG_ CBV_PNIB_L_DHR_FD : 14|1@1+ (1,0) [0|0] ""  GW_BDC_FD,L_DHL_FD,L_DHRL_FD,L_DHRR_FD,L_SAL_FD,L_TPMS_FD,L_UWB_BLE_MST_FD,L_UWB_BLE_SLV_FD,L_UWB_FL_FD,L_UWB_FRNK_FD,L_UWB_FR_FD,L_UWB_RL_FD,L_UWB_RR_FD,L_UWB_TRNK_FD,L_WPC_FD
 SG_ NRR_L_DHR_FD : 16|8@1+ (1,0) [0|0] ""  GW_BDC_FD,L_DHL_FD,L_DHRL_FD,L_DHRR_FD,L_SAL_FD,L_TPMS_FD,L_UWB_BLE_MST_FD,L_UWB_BLE_SLV_FD,L_UWB_FL_FD,L_UWB_FRNK_FD,L_UWB_FR_FD,L_UWB_RL_FD,L_UWB_RR_FD,L_UWB_TRNK_FD,L_WPC_FD
 SG_ NM_State_L_DHR_FD : 24|8@1+ (1,0) [0|0] ""  GW_BDC_FD,L_DHL_FD,L_DHRL_FD,L_DHRR_FD,L_SAL_FD,L_TPMS_FD,L_UWB_BLE_MST_FD,L_UWB_BLE_SLV_FD,L_UWB_FL_FD,L_UWB_FRNK_FD,L_UWB_FR_FD,L_UWB_RL_FD,L_UWB_RR_FD,L_UWB_TRNK_FD,L_WPC_FD
 SG_ PNI_L_DHR_FD : 32|32@1+ (1,0) [0|0] ""  GW_BDC_FD,L_DHL_FD,L_DHRL_FD,L_DHRR_FD,L_SAL_FD,L_TPMS_FD,L_UWB_BLE_MST_FD,L_UWB_BLE_SLV_FD,L_UWB_FL_FD,L_UWB_FRNK_FD,L_UWB_FR_FD,L_UWB_RL_FD,L_UWB_RR_FD,L_UWB_TRNK_FD,L_WPC_FD
 SG_ PNI_L_DHR_FD_1 : 64|64@1+ (1,0) [0|0] ""  GW_BDC_FD,L_DHL_FD,L_DHRL_FD,L_DHRR_FD,L_SAL_FD,L_TPMS_FD,L_UWB_BLE_MST_FD,L_UWB_BLE_SLV_FD,L_UWB_FL_FD,L_UWB_FRNK_FD,L_UWB_FR_FD,L_UWB_RL_FD,L_UWB_RR_FD,L_UWB_TRNK_FD,L_WPC_FD
 SG_ PNI_L_DHR_FD_2 : 128|64@1+ (1,0) [0|0] ""  GW_BDC_FD,L_DHL_FD,L_DHRL_FD,L_DHRR_FD,L_SAL_FD,L_TPMS_FD,L_UWB_BLE_MST_FD,L_UWB_BLE_SLV_FD,L_UWB_FL_FD,L_UWB_FRNK_FD,L_UWB_FR_FD,L_UWB_RL_FD,L_UWB_RR_FD,L_UWB_TRNK_FD,L_WPC_FD
 SG_ PNI_L_DHR_FD_3 : 192|64@1+ (1,0) [0|0] ""  GW_BDC_FD,L_DHL_FD,L_DHRL_FD,L_DHRR_FD,L_SAL_FD,L_TPMS_FD,L_UWB_BLE_MST_FD,L_UWB_BLE_SLV_FD,L_UWB_FL_FD,L_UWB_FRNK_FD,L_UWB_FR_FD,L_UWB_RL_FD,L_UWB_RR_FD,L_UWB_TRNK_FD,L_WPC_FD

CM_ BO_ 2281701488 "[PE] Periodic and On Event";
CM_ SG_ 2281701488 L_WPC_FD_Crc20Val "L_WPC_FD_CyclicRedundancyCheck20Value";
CM_ SG_ 2281701488 L_WPC_FD_AlvCnt20Val "L_WPC_FD_AliveCounter20Value";
CM_ SG_ 2281701488 WPC_Status "WPC Processing Status";
CM_ SG_ 2281701488 WPC2_Status "WPC2 Processing Status";
CM_ SG_ 2281701488 WPC_NFC_Opt "WPC NFC Option Applied Signal";
CM_ BO_ 402391152 "[P] Periodic";
CM_ SG_ 402391152 SNI_CGW_CCU "ASR NM Source Node Identifier";
CM_ SG_ 402391152 CBV_NMCoSRB_CGW_CCU "ASR NM Control Bit Vector - ASR NM Coordinator Sleep Ready Bit";
CM_ SG_ 402391152 CBV_AWB_CGW_CCU "ASR NM Control Bit Vector - Active Wakeup Bit";
CM_ SG_ 402391152 PNI_CGW_CCU_2 "ASR NM Partial Networking Information";
CM_ SG_ 402391152 CBV_PNIB_CGW_CCU "ASR NM Control Bit Vector - PN Info Bit";
CM_ SG_ 402391152 NRR_CGW_CCU "ASR NM Network Request Reason";
CM_ SG_ 402391152 PNI_CGW_CCU_3 "ASR NM Partial Networking Information";
CM_ SG_ 402391152 NM_State_CGW_CCU "ASR NM State_Current State_Previous State";
CM_ SG_ 402391152 PNI_CGW_CCU "ASR NM Partial Networking Information";
CM_ SG_ 402391152 PNI_CGW_CCU_1 "ASR NM Partial Networking Information";
CM_ SG_ 402391152 CBV_RMR_CGW_CCU "ASR NM Control Bit Vector - Repeat Message Request";
CM_ SG_ 402391152 CBV_NMCoID_CGW_CCU "ASR NM Control Bit Vector - ASR NM Coordinator ID";
CM_ SG_ 2549874733 SNI_L_DHRR_FD "ASR NM Source Node Identifier";
CM_ SG_ 2549874733 CBV_RMR_L_DHRR_FD "ASR NM Control Bit Vector - Repeat Message Request";
CM_ SG_ 2549874733 CBV_NMCoID_L_DHRR_FD "ASR NM Control Bit Vector - ASR NM Coordinator ID";
CM_ SG_ 2549874733 CBV_NMCoSRB_L_DHRR_FD "ASR NM Control Bit Vector - ASR NM Coordinator Sleep Ready Bit";
CM_ SG_ 2549874733 CBV_AWB_L_DHRR_FD "ASR NM Control Bit Vector - Active Wakeup Bit";
CM_ SG_ 2549874733 CBV_PNIB_L_DHRR_FD "ASR NM Control Bit Vector - PN Info Bit";
CM_ SG_ 2549874733 NRR_L_DHRR_FD "ASR NM Network Request Reason";
CM_ SG_ 2549874733 NM_State_L_DHRR_FD "ASR NM State_Current State_Previous State";
CM_ SG_ 2549874733 PNI_L_DHRR_FD "ASR NM Partial Networking Information";
CM_ SG_ 2549874733 PNI_L_DHRR_FD_1 "ASR NM Partial Networking Information";
CM_ SG_ 2549874733 PNI_L_DHRR_FD_2 "ASR NM Partial Networking Information";
CM_ SG_ 2549874733 PNI_L_DHRR_FD_3 "ASR NM Partial Networking Information";
CM_ SG_ 2549874720 SNI_L_UWB_BLE_MST_FD "ASR NM Source Node Identifier";
CM_ SG_ 2549874720 CBV_RMR_L_UWB_BLE_MST_FD "ASR NM Control Bit Vector - Repeat Message Request";
CM_ SG_ 2549874720 CBV_NMCoID_L_UWB_BLE_MST_FD "ASR NM Control Bit Vector - ASR NM Coordinator ID";
CM_ SG_ 2549874720 CBV_NMCoSRB_L_UWB_BLE_MST_FD "ASR NM Control Bit Vector - ASR NM Coordinator Sleep Ready Bit";
CM_ SG_ 2549874720 CBV_AWB_L_UWB_BLE_MST_FD "ASR NM Control Bit Vector - Active Wakeup Bit";
CM_ SG_ 2549874720 CBV_PNIB_L_UWB_BLE_MST_FD "ASR NM Control Bit Vector - PN Info Bit";
CM_ SG_ 2549874720 NRR_L_UWB_BLE_MST_FD "ASR NM Network Request Reason";
CM_ SG_ 2549874720 NM_State_L_UWB_BLE_MST_FD "ASR NM State_Current State_Previous State";
CM_ SG_ 2549874720 PNI_L_UWB_BLE_MST_FD "ASR NM Partial Networking Information";
CM_ SG_ 2549874720 PNI_L_UWB_BLE_MST_FD_1 "ASR NM Partial Networking Information";
CM_ SG_ 2549874720 PNI_L_UWB_BLE_MST_FD_2 "ASR NM Partial Networking Information";
CM_ SG_ 2549874720 PNI_L_UWB_BLE_MST_FD_3 "ASR NM Partial Networking Information";
CM_ SG_ 2549874726 SNI_L_UWB_RR_FD "ASR NM Source Node Identifier";
CM_ SG_ 2549874726 CBV_RMR_L_UWB_RR_FD "ASR NM Control Bit Vector - Repeat Message Request";
CM_ SG_ 2549874726 CBV_NMCoID_L_UWB_RR_FD "ASR NM Control Bit Vector - ASR NM Coordinator ID";
CM_ SG_ 2549874726 CBV_NMCoSRB_L_UWB_RR_FD "ASR NM Control Bit Vector - ASR NM Coordinator Sleep Ready Bit";
CM_ SG_ 2549874726 CBV_AWB_L_UWB_RR_FD "ASR NM Control Bit Vector - Active Wakeup Bit";
CM_ SG_ 2549874726 CBV_PNIB_L_UWB_RR_FD "ASR NM Control Bit Vector - PN Info Bit";
CM_ SG_ 2549874726 NRR_L_UWB_RR_FD "ASR NM Network Request Reason";
CM_ SG_ 2549874726 NM_State_L_UWB_RR_FD "ASR NM State_Current State_Previous State";
CM_ SG_ 2549874726 PNI_L_UWB_RR_FD "ASR NM Partial Networking Information";
CM_ SG_ 2549874726 PNI_L_UWB_RR_FD_1 "ASR NM Partial Networking Information";
CM_ SG_ 2549874726 PNI_L_UWB_RR_FD_2 "ASR NM Partial Networking Information";
CM_ SG_ 2549874726 PNI_L_UWB_RR_FD_3 "ASR NM Partial Networking Information";
CM_ SG_ 2549874721 SNI_L_UWB_BLE_SLV_FD "ASR NM Source Node Identifier";
CM_ SG_ 2549874721 CBV_RMR_L_UWB_BLE_SLV_FD "ASR NM Control Bit Vector - Repeat Message Request";
CM_ SG_ 2549874721 CBV_NMCoID_L_UWB_BLE_SLV_FD "ASR NM Control Bit Vector - ASR NM Coordinator ID";
CM_ SG_ 2549874721 CBV_NMCoSRB_L_UWB_BLE_SLV_FD "ASR NM Control Bit Vector - ASR NM Coordinator Sleep Ready Bit";
CM_ SG_ 2549874721 CBV_AWB_L_UWB_BLE_SLV_FD "ASR NM Control Bit Vector - Active Wakeup Bit";
CM_ SG_ 2549874721 CBV_PNIB_L_UWB_BLE_SLV_FD "ASR NM Control Bit Vector - PN Info Bit";
CM_ SG_ 2549874721 NRR_L_UWB_BLE_SLV_FD "ASR NM Network Request Reason";
CM_ SG_ 2549874721 NM_State_L_UWB_BLE_SLV_FD "ASR NM State_Current State_Previous State";
CM_ SG_ 2549874721 PNI_L_UWB_BLE_SLV_FD "ASR NM Partial Networking Information";
CM_ SG_ 2549874721 PNI_L_UWB_BLE_SLV_FD_1 "ASR NM Partial Networking Information";
CM_ SG_ 2549874721 PNI_L_UWB_BLE_SLV_FD_2 "ASR NM Partial Networking Information";
CM_ SG_ 2549874721 PNI_L_UWB_BLE_SLV_FD_3 "ASR NM Partial Networking Information";
CM_ SG_ 2549874723 SNI_L_UWB_FR_FD "ASR NM Source Node Identifier";
CM_ SG_ 2549874723 CBV_RMR_L_UWB_FR_FD "ASR NM Control Bit Vector - Repeat Message Request";
CM_ SG_ 2549874723 CBV_NMCoID_L_UWB_FR_FD "ASR NM Control Bit Vector - ASR NM Coordinator ID";
CM_ SG_ 2549874723 CBV_NMCoSRB_L_UWB_FR_FD "ASR NM Control Bit Vector - ASR NM Coordinator Sleep Ready Bit";
CM_ SG_ 2549874723 CBV_AWB_L_UWB_FR_FD "ASR NM Control Bit Vector - Active Wakeup Bit";
CM_ SG_ 2549874723 CBV_PNIB_L_UWB_FR_FD "ASR NM Control Bit Vector - PN Info Bit";
CM_ SG_ 2549874723 NRR_L_UWB_FR_FD "ASR NM Network Request Reason";
CM_ SG_ 2549874723 NM_State_L_UWB_FR_FD "ASR NM State_Current State_Previous State";
CM_ SG_ 2549874723 PNI_L_UWB_FR_FD "ASR NM Partial Networking Information";
CM_ SG_ 2549874723 PNI_L_UWB_FR_FD_1 "ASR NM Partial Networking Information";
CM_ SG_ 2549874723 PNI_L_UWB_FR_FD_2 "ASR NM Partial Networking Information";
CM_ SG_ 2549874723 PNI_L_UWB_FR_FD_3 "ASR NM Partial Networking Information";
CM_ SG_ 2549874732 SNI_L_DHRL_FD "ASR NM Source Node Identifier";
CM_ SG_ 2549874732 CBV_RMR_L_DHRL_FD "ASR NM Control Bit Vector - Repeat Message Request";
CM_ SG_ 2549874732 CBV_NMCoID_L_DHRL_FD "ASR NM Control Bit Vector - ASR NM Coordinator ID";
CM_ SG_ 2549874732 CBV_NMCoSRB_L_DHRL_FD "ASR NM Control Bit Vector - ASR NM Coordinator Sleep Ready Bit";
CM_ SG_ 2549874732 CBV_AWB_L_DHRL_FD "ASR NM Control Bit Vector - Active Wakeup Bit";
CM_ SG_ 2549874732 CBV_PNIB_L_DHRL_FD "ASR NM Control Bit Vector - PN Info Bit";
CM_ SG_ 2549874732 NRR_L_DHRL_FD "ASR NM Network Request Reason";
CM_ SG_ 2549874732 NM_State_L_DHRL_FD "ASR NM State_Current State_Previous State";
CM_ SG_ 2549874732 PNI_L_DHRL_FD "ASR NM Partial Networking Information";
CM_ SG_ 2549874732 PNI_L_DHRL_FD_1 "ASR NM Partial Networking Information";
CM_ SG_ 2549874732 PNI_L_DHRL_FD_2 "ASR NM Partial Networking Information";
CM_ SG_ 2549874732 PNI_L_DHRL_FD_3 "ASR NM Partial Networking Information";
CM_ SG_ 2549874727 SNI_L_UWB_TRNK_FD "ASR NM Source Node Identifier";
CM_ SG_ 2549874727 CBV_RMR_L_UWB_TRNK_FD "ASR NM Control Bit Vector - Repeat Message Request";
CM_ SG_ 2549874727 CBV_NMCoID_L_UWB_TRNK_FD "ASR NM Control Bit Vector - ASR NM Coordinator ID";
CM_ SG_ 2549874727 CBV_NMCoSRB_L_UWB_TRNK_FD "ASR NM Control Bit Vector - ASR NM Coordinator Sleep Ready Bit";
CM_ SG_ 2549874727 CBV_AWB_L_UWB_TRNK_FD "ASR NM Control Bit Vector - Active Wakeup Bit";
CM_ SG_ 2549874727 CBV_PNIB_L_UWB_TRNK_FD "ASR NM Control Bit Vector - PN Info Bit";
CM_ SG_ 2549874727 NRR_L_UWB_TRNK_FD "ASR NM Network Request Reason";
CM_ SG_ 2549874727 NM_State_L_UWB_TRNK_FD "ASR NM State_Current State_Previous State";
CM_ SG_ 2549874727 PNI_L_UWB_TRNK_FD "ASR NM Partial Networking Information";
CM_ SG_ 2549874727 PNI_L_UWB_TRNK_FD_1 "ASR NM Partial Networking Information";
CM_ SG_ 2549874727 PNI_L_UWB_TRNK_FD_2 "ASR NM Partial Networking Information";
CM_ SG_ 2549874727 PNI_L_UWB_TRNK_FD_3 "ASR NM Partial Networking Information";
CM_ SG_ 2549874724 SNI_L_UWB_FRNK_FD "ASR NM Source Node Identifier";
CM_ SG_ 2549874724 CBV_RMR_L_UWB_FRNK_FD "ASR NM Control Bit Vector - Repeat Message Request";
CM_ SG_ 2549874724 CBV_NMCoID_L_UWB_FRNK_FD "ASR NM Control Bit Vector - ASR NM Coordinator ID";
CM_ SG_ 2549874724 CBV_NMCoSRB_L_UWB_FRNK_FD "ASR NM Control Bit Vector - ASR NM Coordinator Sleep Ready Bit";
CM_ SG_ 2549874724 CBV_AWB_L_UWB_FRNK_FD "ASR NM Control Bit Vector - Active Wakeup Bit";
CM_ SG_ 2549874724 CBV_PNIB_L_UWB_FRNK_FD "ASR NM Control Bit Vector - PN Info Bit";
CM_ SG_ 2549874724 NRR_L_UWB_FRNK_FD "ASR NM Network Request Reason";
CM_ SG_ 2549874724 NM_State_L_UWB_FRNK_FD "ASR NM State_Current State_Previous State";
CM_ SG_ 2549874724 PNI_L_UWB_FRNK_FD "ASR NM Partial Networking Information";
CM_ SG_ 2549874724 PNI_L_UWB_FRNK_FD_1 "ASR NM Partial Networking Information";
CM_ SG_ 2549874724 PNI_L_UWB_FRNK_FD_2 "ASR NM Partial Networking Information";
CM_ SG_ 2549874724 PNI_L_UWB_FRNK_FD_3 "ASR NM Partial Networking Information";
CM_ SG_ 2549874722 SNI_L_UWB_FL_FD "ASR NM Source Node Identifier";
CM_ SG_ 2549874722 CBV_RMR_L_UWB_FL_FD "ASR NM Control Bit Vector - Repeat Message Request";
CM_ SG_ 2549874722 CBV_NMCoID_L_UWB_FL_FD "ASR NM Control Bit Vector - ASR NM Coordinator ID";
CM_ SG_ 2549874722 CBV_NMCoSRB_L_UWB_FL_FD "ASR NM Control Bit Vector - ASR NM Coordinator Sleep Ready Bit";
CM_ SG_ 2549874722 CBV_AWB_L_UWB_FL_FD "ASR NM Control Bit Vector - Active Wakeup Bit";
CM_ SG_ 2549874722 CBV_PNIB_L_UWB_FL_FD "ASR NM Control Bit Vector - PN Info Bit";
CM_ SG_ 2549874722 NRR_L_UWB_FL_FD "ASR NM Network Request Reason";
CM_ SG_ 2549874722 NM_State_L_UWB_FL_FD "ASR NM State_Current State_Previous State";
CM_ SG_ 2549874722 PNI_L_UWB_FL_FD "ASR NM Partial Networking Information";
CM_ SG_ 2549874722 PNI_L_UWB_FL_FD_1 "ASR NM Partial Networking Information";
CM_ SG_ 2549874722 PNI_L_UWB_FL_FD_2 "ASR NM Partial Networking Information";
CM_ SG_ 2549874722 PNI_L_UWB_FL_FD_3 "ASR NM Partial Networking Information";
CM_ SG_ 2549874816 SNI_GW_BDC_FD "ASR NM Source Node Identifier";
CM_ SG_ 2549874816 CBV_RMR_GW_BDC_FD "ASR NM Control Bit Vector - Repeat Message Request";
CM_ SG_ 2549874816 CBV_NMCoID_GW_BDC_FD "ASR NM Control Bit Vector - ASR NM Coordinator ID";
CM_ SG_ 2549874816 CBV_NMCoSRB_GW_BDC_FD "ASR NM Control Bit Vector - ASR NM Coordinator Sleep Ready Bit";
CM_ SG_ 2549874816 CBV_AWB_GW_BDC_FD "ASR NM Control Bit Vector - Active Wakeup Bit";
CM_ SG_ 2549874816 CBV_PNIB_GW_BDC_FD "ASR NM Control Bit Vector - PN Info Bit";
CM_ SG_ 2549874816 NRR_GW_BDC_FD "ASR NM Network Request Reason";
CM_ SG_ 2549874816 NM_State_GW_BDC_FD "ASR NM State_Current State_Previous State";
CM_ SG_ 2549874816 PNI_GW_BDC_FD "ASR NM Partial Networking Information";
CM_ SG_ 2549874816 PNI_GW_BDC_FD_1 "ASR NM Partial Networking Information";
CM_ SG_ 2549874816 PNI_GW_BDC_FD_2 "ASR NM Partial Networking Information";
CM_ SG_ 2549874816 PNI_GW_BDC_FD_3 "ASR NM Partial Networking Information";
CM_ SG_ 2549874725 SNI_L_UWB_RL_FD "ASR NM Source Node Identifier";
CM_ SG_ 2549874725 CBV_RMR_L_UWB_RL_FD "ASR NM Control Bit Vector - Repeat Message Request";
CM_ SG_ 2549874725 CBV_NMCoID_L_UWB_RL_FD "ASR NM Control Bit Vector - ASR NM Coordinator ID";
CM_ SG_ 2549874725 CBV_NMCoSRB_L_UWB_RL_FD "ASR NM Control Bit Vector - ASR NM Coordinator Sleep Ready Bit";
CM_ SG_ 2549874725 CBV_AWB_L_UWB_RL_FD "ASR NM Control Bit Vector - Active Wakeup Bit";
CM_ SG_ 2549874725 CBV_PNIB_L_UWB_RL_FD "ASR NM Control Bit Vector - PN Info Bit";
CM_ SG_ 2549874725 NRR_L_UWB_RL_FD "ASR NM Network Request Reason";
CM_ SG_ 2549874725 NM_State_L_UWB_RL_FD "ASR NM State_Current State_Previous State";
CM_ SG_ 2549874725 PNI_L_UWB_RL_FD "ASR NM Partial Networking Information";
CM_ SG_ 2549874725 PNI_L_UWB_RL_FD_1 "ASR NM Partial Networking Information";
CM_ SG_ 2549874725 PNI_L_UWB_RL_FD_2 "ASR NM Partial Networking Information";
CM_ SG_ 2549874725 PNI_L_UWB_RL_FD_3 "ASR NM Partial Networking Information";
CM_ SG_ 2549874857 SNI_L_SAL_FD "ASR NM Source Node Identifier";
CM_ SG_ 2549874857 CBV_RMR_L_SAL_FD "ASR NM Control Bit Vector - Repeat Message Request";
CM_ SG_ 2549874857 CBV_NMCoID_L_SAL_FD "ASR NM Control Bit Vector - ASR NM Coordinator ID";
CM_ SG_ 2549874857 CBV_NMCoSRB_L_SAL_FD "ASR NM Control Bit Vector - ASR NM Coordinator Sleep Ready Bit";
CM_ SG_ 2549874857 CBV_AWB_L_SAL_FD "ASR NM Control Bit Vector - Active Wakeup Bit";
CM_ SG_ 2549874857 CBV_PNIB_L_SAL_FD "ASR NM Control Bit Vector - PN Info Bit";
CM_ SG_ 2549874857 NRR_L_SAL_FD "ASR NM Network Request Reason";
CM_ SG_ 2549874857 NM_State_L_SAL_FD "ASR NM State_Current State_Previous State";
CM_ SG_ 2549874857 PNI_L_SAL_FD "ASR NM Partial Networking Information";
CM_ SG_ 2549874857 PNI_L_SAL_FD_1 "ASR NM Partial Networking Information";
CM_ SG_ 2549874857 PNI_L_SAL_FD_2 "ASR NM Partial Networking Information";
CM_ SG_ 2549874857 PNI_L_SAL_FD_3 "ASR NM Partial Networking Information";
CM_ SG_ 2549874718 SNI_L_WPC_FD "ASR NM Source Node Identifier";
CM_ SG_ 2549874718 CBV_RMR_L_WPC_FD "ASR NM Control Bit Vector - Repeat Message Request";
CM_ SG_ 2549874718 CBV_NMCoID_L_WPC_FD "ASR NM Control Bit Vector - ASR NM Coordinator ID";
CM_ SG_ 2549874718 CBV_NMCoSRB_L_WPC_FD "ASR NM Control Bit Vector - ASR NM Coordinator Sleep Ready Bit";
CM_ SG_ 2549874718 CBV_AWB_L_WPC_FD "ASR NM Control Bit Vector - Active Wakeup Bit";
CM_ SG_ 2549874718 CBV_PNIB_L_WPC_FD "ASR NM Control Bit Vector - PN Info Bit";
CM_ SG_ 2549874718 NRR_L_WPC_FD "ASR NM Network Request Reason";
CM_ SG_ 2549874718 NM_State_L_WPC_FD "ASR NM State_Current State_Previous State";
CM_ SG_ 2549874718 PNI_L_WPC_FD "ASR NM Partial Networking Information";
CM_ SG_ 2549874718 PNI_L_WPC_FD_1 "ASR NM Partial Networking Information";
CM_ SG_ 2549874718 PNI_L_WPC_FD_2 "ASR NM Partial Networking Information";
CM_ SG_ 2549874718 PNI_L_WPC_FD_3 "ASR NM Partial Networking Information";
CM_ SG_ 2549874728 SNI_L_TPMS_FD "ASR NM Source Node Identifier";
CM_ SG_ 2549874728 CBV_RMR_L_TPMS_FD "ASR NM Control Bit Vector - Repeat Message Request";
CM_ SG_ 2549874728 CBV_NMCoID_L_TPMS_FD "ASR NM Control Bit Vector - ASR NM Coordinator ID";
CM_ SG_ 2549874728 CBV_NMCoSRB_L_TPMS_FD "ASR NM Control Bit Vector - ASR NM Coordinator Sleep Ready Bit";
CM_ SG_ 2549874728 CBV_AWB_L_TPMS_FD "ASR NM Control Bit Vector - Active Wakeup Bit";
CM_ SG_ 2549874728 CBV_PNIB_L_TPMS_FD "ASR NM Control Bit Vector - PN Info Bit";
CM_ SG_ 2549874728 NRR_L_TPMS_FD "ASR NM Network Request Reason";
CM_ SG_ 2549874728 NM_State_L_TPMS_FD "ASR NM State_Current State_Previous State";
CM_ SG_ 2549874728 PNI_L_TPMS_FD "ASR NM Partial Networking Information";
CM_ SG_ 2549874728 PNI_L_TPMS_FD_1 "ASR NM Partial Networking Information";
CM_ SG_ 2549874728 PNI_L_TPMS_FD_2 "ASR NM Partial Networking Information";
CM_ SG_ 2549874728 PNI_L_TPMS_FD_3 "ASR NM Partial Networking Information";
CM_ SG_ 2549874730 SNI_L_DHL_FD "ASR NM Source Node Identifier";
CM_ SG_ 2549874730 CBV_RMR_L_DHL_FD "ASR NM Control Bit Vector - Repeat Message Request";
CM_ SG_ 2549874730 CBV_NMCoID_L_DHL_FD "ASR NM Control Bit Vector - ASR NM Coordinator ID";
CM_ SG_ 2549874730 CBV_NMCoSRB_L_DHL_FD "ASR NM Control Bit Vector - ASR NM Coordinator Sleep Ready Bit";
CM_ SG_ 2549874730 CBV_AWB_L_DHL_FD "ASR NM Control Bit Vector - Active Wakeup Bit";
CM_ SG_ 2549874730 CBV_PNIB_L_DHL_FD "ASR NM Control Bit Vector - PN Info Bit";
CM_ SG_ 2549874730 NRR_L_DHL_FD "ASR NM Network Request Reason";
CM_ SG_ 2549874730 NM_State_L_DHL_FD "ASR NM State_Current State_Previous State";
CM_ SG_ 2549874730 PNI_L_DHL_FD "ASR NM Partial Networking Information";
CM_ SG_ 2549874730 PNI_L_DHL_FD_1 "ASR NM Partial Networking Information";
CM_ SG_ 2549874730 PNI_L_DHL_FD_2 "ASR NM Partial Networking Information";
CM_ SG_ 2549874730 PNI_L_DHL_FD_3 "ASR NM Partial Networking Information";
CM_ SG_ 2549874731 SNI_L_DHR_FD "ASR NM Source Node Identifier";
CM_ SG_ 2549874731 CBV_RMR_L_DHR_FD "ASR NM Control Bit Vector - Repeat Message Request";
CM_ SG_ 2549874731 CBV_NMCoID_L_DHR_FD "ASR NM Control Bit Vector - ASR NM Coordinator ID";
CM_ SG_ 2549874731 CBV_NMCoSRB_L_DHR_FD "ASR NM Control Bit Vector - ASR NM Coordinator Sleep Ready Bit";
CM_ SG_ 2549874731 CBV_AWB_L_DHR_FD "ASR NM Control Bit Vector - Active Wakeup Bit";
CM_ SG_ 2549874731 CBV_PNIB_L_DHR_FD "ASR NM Control Bit Vector - PN Info Bit";
CM_ SG_ 2549874731 NRR_L_DHR_FD "ASR NM Network Request Reason";
CM_ SG_ 2549874731 NM_State_L_DHR_FD "ASR NM State_Current State_Previous State";
CM_ SG_ 2549874731 PNI_L_DHR_FD "ASR NM Partial Networking Information";
CM_ SG_ 2549874731 PNI_L_DHR_FD_1 "ASR NM Partial Networking Information";
CM_ SG_ 2549874731 PNI_L_DHR_FD_2 "ASR NM Partial Networking Information";
CM_ SG_ 2549874731 PNI_L_DHR_FD_3 "ASR NM Partial Networking Information";
BA_DEF_ BO_ "CANFD_BRS" ENUM "0","1" ;
BA_DEF_ BO_ "GenMsgEVName" STRING ;
BA_DEF_ BO_ "NmAsrMessage" ENUM "No","Yes" ;
BA_DEF_ BO_ "DiagState" ENUM "No","Yes" ;
BA_DEF_ BO_ "TpMessage" ENUM "No","Yes" ;
BA_DEF_ BO_ "UsrMsgIDSforwardDeviation" INT 0 100 ;
BA_DEF_ BO_ "UsrMsgIDSbackwardDeviation" INT 50 1000 ;
BA_DEF_ BO_ "GenMsgCycleTime" INT 0 2000 ;
BA_DEF_ BO_ "GenMsgStartDelayTime" INT 0 2000 ;
BA_DEF_ BO_ "GenMsgSendType" ENUM "Cyclic","NoMsgSendType" ;
BA_DEF_ BO_ "GenMsgCycleTimeFast" INT 0 500 ;
BA_DEF_ BO_ "GenMsgDelayTime" INT 0 20 ;
BA_DEF_ BO_ "GenMsgILSupport" ENUM "No","Yes" ;
BA_DEF_ BO_ "GenMsgNrOfRepetition" INT 0 3 ;
BA_DEF_ BO_ "TpTxIndex" INT 0 65535 ;
BA_DEF_ BO_ "VFrameFormat" ENUM "StandardCAN","ExtendedCAN","reserved","reserved","reserved","reserved","reserved","reserved","reserved","reserved","reserved","reserved","reserved","reserved","StandardCAN_FD","ExtendedCAN_FD" ;
BA_DEF_ SG_ "UserSigValidity" ENUM "B+","ACC","IG","IG1","IG2","IG3","IG1 or IG2","IG1 or IG3","Undef" ;
BA_DEF_ SG_ "TimeoutValue" STRING ;
BA_DEF_ SG_ "UsrSigPurpose" ENUM "Undef","FN","DIAG","DIAG(Req)","DIAG(Res)","DIAG(Func)","DEV","CCP","NM","TP" ;
BA_DEF_ SG_ "GenSigStartValue" INT 0 1215752192 ;
BA_DEF_ SG_ "NetworkRequest" ENUM "Yes","No" ;
BA_DEF_ SG_ "NetworkRequestHoldingTime" INT 0 65535 ;
BA_DEF_ SG_ "Description" STRING ;
BA_DEF_ SG_ "Version" STRING ;
BA_DEF_ SG_ "GenSigEnvVarType" ENUM "Int","Float","Undef" ;
BA_DEF_ SG_ "GenSigSendType" ENUM "Cyclic","OnWrite","OnWriteWithRepetition","OnChange","OnChangeWithRepetition","IfActive","IfActiveWithRepetition","NoSigSendType","OnChangeAndIfActive","OnChangeAndIfActiveWithRepetition" ;
BA_DEF_ SG_ "GwSigLatencyTime" INT 0 65536 ;
BA_DEF_ SG_ "GwSigMissingSourceType" ENUM "Undef","OldValue","DefaultValue","InitialValue" ;
BA_DEF_ SG_ "NWM-WakeupAllowed" ENUM "<n.a.>" ;
BA_DEF_ SG_ "RoutingFactor" INT 1 1215752192 ;
BA_DEF_REL_ BU_SG_REL_ "GenSigTimeoutTime" INT 0 7000 ;
BA_DEF_DEF_ "CANFD_BRS" "1" ;
BA_DEF_DEF_ "GenMsgEVName" "@Signame" ;
BA_DEF_DEF_ "NmAsrMessage" "No" ;
BA_DEF_DEF_ "DiagState" "No" ;
BA_DEF_DEF_ "TpMessage" "No" ;
BA_DEF_DEF_ "UsrMsgIDSforwardDeviation" 10 ;
BA_DEF_DEF_ "UsrMsgIDSbackwardDeviation" 100 ;
BA_DEF_DEF_ "GenMsgCycleTime" 200 ;
BA_DEF_DEF_ "GenMsgStartDelayTime" 0 ;
BA_DEF_DEF_ "GenMsgSendType" "NoMsgSendType" ;
BA_DEF_DEF_ "GenMsgCycleTimeFast" 40 ;
BA_DEF_DEF_ "GenMsgDelayTime" 20 ;
BA_DEF_DEF_ "GenMsgILSupport" "Yes" ;
BA_DEF_DEF_ "GenMsgNrOfRepetition" 3 ;
BA_DEF_DEF_ "TpTxIndex" 0 ;
BA_DEF_DEF_ "VFrameFormat" "StandardCAN" ;
BA_DEF_DEF_ "UserSigValidity" "IG" ;
BA_DEF_DEF_ "TimeoutValue" "" ;
BA_DEF_DEF_ "UsrSigPurpose" "FN" ;
BA_DEF_DEF_ "GenSigStartValue" 0 ;
BA_DEF_DEF_ "NetworkRequest" "No" ;
BA_DEF_DEF_ "NetworkRequestHoldingTime" 0 ;
BA_DEF_DEF_ "Description" "" ;
BA_DEF_DEF_ "Version" "" ;
BA_DEF_DEF_ "GenSigEnvVarType" "Undef" ;
BA_DEF_DEF_ "GenSigSendType" "NoSigSendType" ;
BA_DEF_DEF_ "GwSigLatencyTime" 40 ;
BA_DEF_DEF_ "GwSigMissingSourceType" "Undef" ;
BA_DEF_DEF_ "NWM-WakeupAllowed" "<n.a.>" ;
BA_DEF_DEF_ "RoutingFactor" 1 ;
BA_DEF_DEF_REL_ "GenSigTimeoutTime" 500 ;
BA_ "GenMsgSendType" BO_ 2281701488 0;
BA_ "VFrameFormat" BO_ 2281701488 15;
BA_ "Description" SG_ 2281701488 L_WPC_FD_Crc20Val "The data area for CRC calculation is based on the data length (DLC) of the message DB.

The CRC shall be calculated over the entire data block (excluding the CRC bytes) including the user data, alive counter and Data ID



- CRC Polynomial (0x1021) , Initial Value : 0xFFFF, XOR value : 0x0000, Data ID : Message ID + 0xF800 

- The initial value is for CRC calculation and the message should be sent with the calculated result value. 

- The mathematical expression to 16 bit CRC polynomial is given here. G(x) = x16 + x12 + x5 + 1



<For CRC calculation of CAN-FD Msg for HS CAN domain ECUs>



- HS-CAN Messages that routed from CAN-FD domain are using 29 bit Extended CAN ID and splitted into 8 Byte Messages.

(from 1 to 4 Msgs, depending on source CAN-FD Msg¡¯s DLC)

- For splitted CAN-FD Msgs¡¯ CRC calculation, HS CAN ECUs should use source CAN-FD Msg¡¯s original STD ID. 

- The original STD ID can be read from Ext ID¡¯s 4~6th Byte.

Eg. STD 0x6AA : EXT SPLT 0x1A8[6AA]01 / 0x1A8[6AA]02 / 0x1A8[6AA]03 / 0x1A8[6AA]04 

(2~4th splitited Msgs can be omitted depending on source CAN-FD Msg¡¯s DLC)

- Aslo, HS-CAN ECUs should use merged data block (from whole splitted Msg) for CRC calculation.";
BA_ "GenSigSendType" SG_ 2281701488 L_WPC_FD_Crc20Val 4;
BA_ "GenSigStartValue" SG_ 2281701488 L_WPC_FD_Crc20Val 65535;
BA_ "UserSigValidity" SG_ 2281701488 L_WPC_FD_Crc20Val 3;
BA_ "Version" SG_ 2281701488 L_WPC_FD_Crc20Val "23.01.02";
BA_ "Description" SG_ 2281701488 L_WPC_FD_AlvCnt20Val "For the first transmission request for a data element the counter shall be initialized with 0 and shall be incremented by 1 for every subsequent send request. 

When the counter reaches the maximum value(0xFF), then it shall restart with 0 for the next send request";
BA_ "GenSigSendType" SG_ 2281701488 L_WPC_FD_AlvCnt20Val 4;
BA_ "UserSigValidity" SG_ 2281701488 L_WPC_FD_AlvCnt20Val 3;
BA_ "Version" SG_ 2281701488 L_WPC_FD_AlvCnt20Val "23.01.02";
BA_ "GenSigSendType" SG_ 2281701488 WPC_Status 4;
BA_ "UserSigValidity" SG_ 2281701488 WPC_Status 0;
BA_REL_ "GenSigTimeoutTime" BU_SG_REL_ GW_BDC_FD SG_ 2281701488 WPC_Status 1500;
BA_ "Version" SG_ 2281701488 WPC_Status "23.01.02";
BA_ "Description" SG_ 2281701488 WPC2_Status "WPC2 Processing Status";
BA_ "GenSigSendType" SG_ 2281701488 WPC2_Status 4;
BA_ "UserSigValidity" SG_ 2281701488 WPC2_Status 0;
BA_REL_ "GenSigTimeoutTime" BU_SG_REL_ GW_BDC_FD SG_ 2281701488 WPC2_Status 1500;
BA_ "Version" SG_ 2281701488 WPC2_Status "24.06.00";
BA_ "GenSigSendType" SG_ 2281701488 WPC_NFC_Opt 4;
BA_ "UserSigValidity" SG_ 2281701488 WPC_NFC_Opt 0;
BA_REL_ "GenSigTimeoutTime" BU_SG_REL_ GW_BDC_FD SG_ 2281701488 WPC_NFC_Opt 1500;
BA_ "Version" SG_ 2281701488 WPC_NFC_Opt "23.01.02";
BA_ "GenMsgSendType" BO_ 402391152 0;
BA_ "GenMsgCycleTime" BO_ 402391152 100;
BA_ "GenMsgCycleTimeFast" BO_ 402391152 0;
BA_ "GenMsgNrOfRepetition" BO_ 402391152 0;
BA_ "VFrameFormat" BO_ 402391152 15;
BA_ "UsrSigPurpose" SG_ 402391152 SNI_CGW_CCU 8;
BA_ "UserSigValidity" SG_ 402391152 SNI_CGW_CCU 0;
BA_REL_ "GenSigTimeoutTime" BU_SG_REL_ L_DHL_FD SG_ 402391152 SNI_CGW_CCU 1500;
BA_REL_ "GenSigTimeoutTime" BU_SG_REL_ L_DHRL_FD SG_ 402391152 SNI_CGW_CCU 1500;
BA_REL_ "GenSigTimeoutTime" BU_SG_REL_ L_DHRR_FD SG_ 402391152 SNI_CGW_CCU 1500;
BA_REL_ "GenSigTimeoutTime" BU_SG_REL_ L_DHR_FD SG_ 402391152 SNI_CGW_CCU 1500;
BA_REL_ "GenSigTimeoutTime" BU_SG_REL_ L_SAL_FD SG_ 402391152 SNI_CGW_CCU 1500;
BA_REL_ "GenSigTimeoutTime" BU_SG_REL_ L_TPMS_FD SG_ 402391152 SNI_CGW_CCU 1500;
BA_REL_ "GenSigTimeoutTime" BU_SG_REL_ L_UWB_BLE_MST_FD SG_ 402391152 SNI_CGW_CCU 1500;
BA_REL_ "GenSigTimeoutTime" BU_SG_REL_ L_UWB_BLE_SLV_FD SG_ 402391152 SNI_CGW_CCU 1500;
BA_REL_ "GenSigTimeoutTime" BU_SG_REL_ L_UWB_FL_FD SG_ 402391152 SNI_CGW_CCU 1500;
BA_REL_ "GenSigTimeoutTime" BU_SG_REL_ L_UWB_FRNK_FD SG_ 402391152 SNI_CGW_CCU 1500;
BA_REL_ "GenSigTimeoutTime" BU_SG_REL_ L_UWB_FR_FD SG_ 402391152 SNI_CGW_CCU 1500;
BA_REL_ "GenSigTimeoutTime" BU_SG_REL_ L_UWB_RL_FD SG_ 402391152 SNI_CGW_CCU 1500;
BA_REL_ "GenSigTimeoutTime" BU_SG_REL_ L_UWB_RR_FD SG_ 402391152 SNI_CGW_CCU 1500;
BA_REL_ "GenSigTimeoutTime" BU_SG_REL_ L_UWB_TRNK_FD SG_ 402391152 SNI_CGW_CCU 1500;
BA_REL_ "GenSigTimeoutTime" BU_SG_REL_ L_WPC_FD SG_ 402391152 SNI_CGW_CCU 1500;
BA_ "RoutingFactor" SG_ 402391152 SNI_CGW_CCU 0;
BA_ "UsrSigPurpose" SG_ 402391152 CBV_NMCoSRB_CGW_CCU 8;
BA_ "UserSigValidity" SG_ 402391152 CBV_NMCoSRB_CGW_CCU 0;
BA_REL_ "GenSigTimeoutTime" BU_SG_REL_ L_DHL_FD SG_ 402391152 CBV_NMCoSRB_CGW_CCU 1500;
BA_REL_ "GenSigTimeoutTime" BU_SG_REL_ L_DHRL_FD SG_ 402391152 CBV_NMCoSRB_CGW_CCU 1500;
BA_REL_ "GenSigTimeoutTime" BU_SG_REL_ L_DHRR_FD SG_ 402391152 CBV_NMCoSRB_CGW_CCU 1500;
BA_REL_ "GenSigTimeoutTime" BU_SG_REL_ L_DHR_FD SG_ 402391152 CBV_NMCoSRB_CGW_CCU 1500;
BA_REL_ "GenSigTimeoutTime" BU_SG_REL_ L_SAL_FD SG_ 402391152 CBV_NMCoSRB_CGW_CCU 1500;
BA_REL_ "GenSigTimeoutTime" BU_SG_REL_ L_TPMS_FD SG_ 402391152 CBV_NMCoSRB_CGW_CCU 1500;
BA_REL_ "GenSigTimeoutTime" BU_SG_REL_ L_UWB_BLE_MST_FD SG_ 402391152 CBV_NMCoSRB_CGW_CCU 1500;
BA_REL_ "GenSigTimeoutTime" BU_SG_REL_ L_UWB_BLE_SLV_FD SG_ 402391152 CBV_NMCoSRB_CGW_CCU 1500;
BA_REL_ "GenSigTimeoutTime" BU_SG_REL_ L_UWB_FL_FD SG_ 402391152 CBV_NMCoSRB_CGW_CCU 1500;
BA_REL_ "GenSigTimeoutTime" BU_SG_REL_ L_UWB_FRNK_FD SG_ 402391152 CBV_NMCoSRB_CGW_CCU 1500;
BA_REL_ "GenSigTimeoutTime" BU_SG_REL_ L_UWB_FR_FD SG_ 402391152 CBV_NMCoSRB_CGW_CCU 1500;
BA_REL_ "GenSigTimeoutTime" BU_SG_REL_ L_UWB_RL_FD SG_ 402391152 CBV_NMCoSRB_CGW_CCU 1500;
BA_REL_ "GenSigTimeoutTime" BU_SG_REL_ L_UWB_RR_FD SG_ 402391152 CBV_NMCoSRB_CGW_CCU 1500;
BA_REL_ "GenSigTimeoutTime" BU_SG_REL_ L_UWB_TRNK_FD SG_ 402391152 CBV_NMCoSRB_CGW_CCU 1500;
BA_REL_ "GenSigTimeoutTime" BU_SG_REL_ L_WPC_FD SG_ 402391152 CBV_NMCoSRB_CGW_CCU 1500;
BA_ "RoutingFactor" SG_ 402391152 CBV_NMCoSRB_CGW_CCU 0;
BA_ "UsrSigPurpose" SG_ 402391152 CBV_AWB_CGW_CCU 8;
BA_ "UserSigValidity" SG_ 402391152 CBV_AWB_CGW_CCU 0;
BA_REL_ "GenSigTimeoutTime" BU_SG_REL_ L_DHL_FD SG_ 402391152 CBV_AWB_CGW_CCU 1500;
BA_REL_ "GenSigTimeoutTime" BU_SG_REL_ L_DHRL_FD SG_ 402391152 CBV_AWB_CGW_CCU 1500;
BA_REL_ "GenSigTimeoutTime" BU_SG_REL_ L_DHRR_FD SG_ 402391152 CBV_AWB_CGW_CCU 1500;
BA_REL_ "GenSigTimeoutTime" BU_SG_REL_ L_DHR_FD SG_ 402391152 CBV_AWB_CGW_CCU 1500;
BA_REL_ "GenSigTimeoutTime" BU_SG_REL_ L_SAL_FD SG_ 402391152 CBV_AWB_CGW_CCU 1500;
BA_REL_ "GenSigTimeoutTime" BU_SG_REL_ L_TPMS_FD SG_ 402391152 CBV_AWB_CGW_CCU 1500;
BA_REL_ "GenSigTimeoutTime" BU_SG_REL_ L_UWB_BLE_MST_FD SG_ 402391152 CBV_AWB_CGW_CCU 1500;
BA_REL_ "GenSigTimeoutTime" BU_SG_REL_ L_UWB_BLE_SLV_FD SG_ 402391152 CBV_AWB_CGW_CCU 1500;
BA_REL_ "GenSigTimeoutTime" BU_SG_REL_ L_UWB_FL_FD SG_ 402391152 CBV_AWB_CGW_CCU 1500;
BA_REL_ "GenSigTimeoutTime" BU_SG_REL_ L_UWB_FRNK_FD SG_ 402391152 CBV_AWB_CGW_CCU 1500;
BA_REL_ "GenSigTimeoutTime" BU_SG_REL_ L_UWB_FR_FD SG_ 402391152 CBV_AWB_CGW_CCU 1500;
BA_REL_ "GenSigTimeoutTime" BU_SG_REL_ L_UWB_RL_FD SG_ 402391152 CBV_AWB_CGW_CCU 1500;
BA_REL_ "GenSigTimeoutTime" BU_SG_REL_ L_UWB_RR_FD SG_ 402391152 CBV_AWB_CGW_CCU 1500;
BA_REL_ "GenSigTimeoutTime" BU_SG_REL_ L_UWB_TRNK_FD SG_ 402391152 CBV_AWB_CGW_CCU 1500;
BA_REL_ "GenSigTimeoutTime" BU_SG_REL_ L_WPC_FD SG_ 402391152 CBV_AWB_CGW_CCU 1500;
BA_ "RoutingFactor" SG_ 402391152 CBV_AWB_CGW_CCU 0;
BA_ "Description" SG_ 402391152 PNI_CGW_CCU_2 "For PN ECUs, each partial networking cluster (PNC) is assigned a Partial Networking Information bit. The Partial Networking Information bit field contains the signals PNC_1 to PNC_224.







PNC_1(All ECUs), PNC_2(OTA Cooperative ECUs), PNC_3(OTA Cooperative ECUs for infotainment channel)







PNC_2, PNC_3 signal sends to support ECUs that needed to perform the OTA cooperative function.



0 : Support ECUs are not required.



1 : Support ECUs are required.







PNC_4 ~ PNC_224 signals are individually assinged to the target ECU.



Refer to ES95480-03 for details.







Detailed information is as follows: 6. PNC Configuration @ cody-ecm";
BA_ "UsrSigPurpose" SG_ 402391152 PNI_CGW_CCU_2 8;
BA_ "UserSigValidity" SG_ 402391152 PNI_CGW_CCU_2 0;
BA_REL_ "GenSigTimeoutTime" BU_SG_REL_ L_DHL_FD SG_ 402391152 PNI_CGW_CCU_2 1500;
BA_REL_ "GenSigTimeoutTime" BU_SG_REL_ L_DHRL_FD SG_ 402391152 PNI_CGW_CCU_2 1500;
BA_REL_ "GenSigTimeoutTime" BU_SG_REL_ L_DHRR_FD SG_ 402391152 PNI_CGW_CCU_2 1500;
BA_REL_ "GenSigTimeoutTime" BU_SG_REL_ L_DHR_FD SG_ 402391152 PNI_CGW_CCU_2 1500;
BA_REL_ "GenSigTimeoutTime" BU_SG_REL_ L_SAL_FD SG_ 402391152 PNI_CGW_CCU_2 1500;
BA_REL_ "GenSigTimeoutTime" BU_SG_REL_ L_TPMS_FD SG_ 402391152 PNI_CGW_CCU_2 1500;
BA_REL_ "GenSigTimeoutTime" BU_SG_REL_ L_UWB_BLE_MST_FD SG_ 402391152 PNI_CGW_CCU_2 1500;
BA_REL_ "GenSigTimeoutTime" BU_SG_REL_ L_UWB_BLE_SLV_FD SG_ 402391152 PNI_CGW_CCU_2 1500;
BA_REL_ "GenSigTimeoutTime" BU_SG_REL_ L_UWB_FL_FD SG_ 402391152 PNI_CGW_CCU_2 1500;
BA_REL_ "GenSigTimeoutTime" BU_SG_REL_ L_UWB_FRNK_FD SG_ 402391152 PNI_CGW_CCU_2 1500;
BA_REL_ "GenSigTimeoutTime" BU_SG_REL_ L_UWB_FR_FD SG_ 402391152 PNI_CGW_CCU_2 1500;
BA_REL_ "GenSigTimeoutTime" BU_SG_REL_ L_UWB_RL_FD SG_ 402391152 PNI_CGW_CCU_2 1500;
BA_REL_ "GenSigTimeoutTime" BU_SG_REL_ L_UWB_RR_FD SG_ 402391152 PNI_CGW_CCU_2 1500;
BA_REL_ "GenSigTimeoutTime" BU_SG_REL_ L_UWB_TRNK_FD SG_ 402391152 PNI_CGW_CCU_2 1500;
BA_REL_ "GenSigTimeoutTime" BU_SG_REL_ L_WPC_FD SG_ 402391152 PNI_CGW_CCU_2 1500;
BA_ "RoutingFactor" SG_ 402391152 PNI_CGW_CCU_2 0;
BA_ "UsrSigPurpose" SG_ 402391152 CBV_PNIB_CGW_CCU 8;
BA_ "UserSigValidity" SG_ 402391152 CBV_PNIB_CGW_CCU 0;
BA_REL_ "GenSigTimeoutTime" BU_SG_REL_ L_DHL_FD SG_ 402391152 CBV_PNIB_CGW_CCU 1500;
BA_REL_ "GenSigTimeoutTime" BU_SG_REL_ L_DHRL_FD SG_ 402391152 CBV_PNIB_CGW_CCU 1500;
BA_REL_ "GenSigTimeoutTime" BU_SG_REL_ L_DHRR_FD SG_ 402391152 CBV_PNIB_CGW_CCU 1500;
BA_REL_ "GenSigTimeoutTime" BU_SG_REL_ L_DHR_FD SG_ 402391152 CBV_PNIB_CGW_CCU 1500;
BA_REL_ "GenSigTimeoutTime" BU_SG_REL_ L_SAL_FD SG_ 402391152 CBV_PNIB_CGW_CCU 1500;
BA_REL_ "GenSigTimeoutTime" BU_SG_REL_ L_TPMS_FD SG_ 402391152 CBV_PNIB_CGW_CCU 1500;
BA_REL_ "GenSigTimeoutTime" BU_SG_REL_ L_UWB_BLE_MST_FD SG_ 402391152 CBV_PNIB_CGW_CCU 1500;
BA_REL_ "GenSigTimeoutTime" BU_SG_REL_ L_UWB_BLE_SLV_FD SG_ 402391152 CBV_PNIB_CGW_CCU 1500;
BA_REL_ "GenSigTimeoutTime" BU_SG_REL_ L_UWB_FL_FD SG_ 402391152 CBV_PNIB_CGW_CCU 1500;
BA_REL_ "GenSigTimeoutTime" BU_SG_REL_ L_UWB_FRNK_FD SG_ 402391152 CBV_PNIB_CGW_CCU 1500;
BA_REL_ "GenSigTimeoutTime" BU_SG_REL_ L_UWB_FR_FD SG_ 402391152 CBV_PNIB_CGW_CCU 1500;
BA_REL_ "GenSigTimeoutTime" BU_SG_REL_ L_UWB_RL_FD SG_ 402391152 CBV_PNIB_CGW_CCU 1500;
BA_REL_ "GenSigTimeoutTime" BU_SG_REL_ L_UWB_RR_FD SG_ 402391152 CBV_PNIB_CGW_CCU 1500;
BA_REL_ "GenSigTimeoutTime" BU_SG_REL_ L_UWB_TRNK_FD SG_ 402391152 CBV_PNIB_CGW_CCU 1500;
BA_REL_ "GenSigTimeoutTime" BU_SG_REL_ L_WPC_FD SG_ 402391152 CBV_PNIB_CGW_CCU 1500;
BA_ "RoutingFactor" SG_ 402391152 CBV_PNIB_CGW_CCU 0;
BA_ "UsrSigPurpose" SG_ 402391152 NRR_CGW_CCU 8;
BA_ "UserSigValidity" SG_ 402391152 NRR_CGW_CCU 0;
BA_REL_ "GenSigTimeoutTime" BU_SG_REL_ L_DHL_FD SG_ 402391152 NRR_CGW_CCU 1500;
BA_REL_ "GenSigTimeoutTime" BU_SG_REL_ L_DHRL_FD SG_ 402391152 NRR_CGW_CCU 1500;
BA_REL_ "GenSigTimeoutTime" BU_SG_REL_ L_DHRR_FD SG_ 402391152 NRR_CGW_CCU 1500;
BA_REL_ "GenSigTimeoutTime" BU_SG_REL_ L_DHR_FD SG_ 402391152 NRR_CGW_CCU 1500;
BA_REL_ "GenSigTimeoutTime" BU_SG_REL_ L_SAL_FD SG_ 402391152 NRR_CGW_CCU 1500;
BA_REL_ "GenSigTimeoutTime" BU_SG_REL_ L_TPMS_FD SG_ 402391152 NRR_CGW_CCU 1500;
BA_REL_ "GenSigTimeoutTime" BU_SG_REL_ L_UWB_BLE_MST_FD SG_ 402391152 NRR_CGW_CCU 1500;
BA_REL_ "GenSigTimeoutTime" BU_SG_REL_ L_UWB_BLE_SLV_FD SG_ 402391152 NRR_CGW_CCU 1500;
BA_REL_ "GenSigTimeoutTime" BU_SG_REL_ L_UWB_FL_FD SG_ 402391152 NRR_CGW_CCU 1500;
BA_REL_ "GenSigTimeoutTime" BU_SG_REL_ L_UWB_FRNK_FD SG_ 402391152 NRR_CGW_CCU 1500;
BA_REL_ "GenSigTimeoutTime" BU_SG_REL_ L_UWB_FR_FD SG_ 402391152 NRR_CGW_CCU 1500;
BA_REL_ "GenSigTimeoutTime" BU_SG_REL_ L_UWB_RL_FD SG_ 402391152 NRR_CGW_CCU 1500;
BA_REL_ "GenSigTimeoutTime" BU_SG_REL_ L_UWB_RR_FD SG_ 402391152 NRR_CGW_CCU 1500;
BA_REL_ "GenSigTimeoutTime" BU_SG_REL_ L_UWB_TRNK_FD SG_ 402391152 NRR_CGW_CCU 1500;
BA_REL_ "GenSigTimeoutTime" BU_SG_REL_ L_WPC_FD SG_ 402391152 NRR_CGW_CCU 1500;
BA_ "RoutingFactor" SG_ 402391152 NRR_CGW_CCU 0;
BA_ "Description" SG_ 402391152 PNI_CGW_CCU_3 "For PN ECUs, each partial networking cluster (PNC) is assigned a Partial Networking Information bit. The Partial Networking Information bit field contains the signals PNC_1 to PNC_224.







PNC_1(All ECUs), PNC_2(OTA Cooperative ECUs), PNC_3(OTA Cooperative ECUs for infotainment channel)







PNC_2, PNC_3 signal sends to support ECUs that needed to perform the OTA cooperative function.



0 : Support ECUs are not required.



1 : Support ECUs are required.







PNC_4 ~ PNC_224 signals are individually assinged to the target ECU.



Refer to ES95480-03 for details.







Detailed information is as follows: 6. PNC Configuration @ cody-ecm";
BA_ "UsrSigPurpose" SG_ 402391152 PNI_CGW_CCU_3 8;
BA_ "UserSigValidity" SG_ 402391152 PNI_CGW_CCU_3 0;
BA_REL_ "GenSigTimeoutTime" BU_SG_REL_ L_DHL_FD SG_ 402391152 PNI_CGW_CCU_3 1500;
BA_REL_ "GenSigTimeoutTime" BU_SG_REL_ L_DHRL_FD SG_ 402391152 PNI_CGW_CCU_3 1500;
BA_REL_ "GenSigTimeoutTime" BU_SG_REL_ L_DHRR_FD SG_ 402391152 PNI_CGW_CCU_3 1500;
BA_REL_ "GenSigTimeoutTime" BU_SG_REL_ L_DHR_FD SG_ 402391152 PNI_CGW_CCU_3 1500;
BA_REL_ "GenSigTimeoutTime" BU_SG_REL_ L_SAL_FD SG_ 402391152 PNI_CGW_CCU_3 1500;
BA_REL_ "GenSigTimeoutTime" BU_SG_REL_ L_TPMS_FD SG_ 402391152 PNI_CGW_CCU_3 1500;
BA_REL_ "GenSigTimeoutTime" BU_SG_REL_ L_UWB_BLE_MST_FD SG_ 402391152 PNI_CGW_CCU_3 1500;
BA_REL_ "GenSigTimeoutTime" BU_SG_REL_ L_UWB_BLE_SLV_FD SG_ 402391152 PNI_CGW_CCU_3 1500;
BA_REL_ "GenSigTimeoutTime" BU_SG_REL_ L_UWB_FL_FD SG_ 402391152 PNI_CGW_CCU_3 1500;
BA_REL_ "GenSigTimeoutTime" BU_SG_REL_ L_UWB_FRNK_FD SG_ 402391152 PNI_CGW_CCU_3 1500;
BA_REL_ "GenSigTimeoutTime" BU_SG_REL_ L_UWB_FR_FD SG_ 402391152 PNI_CGW_CCU_3 1500;
BA_REL_ "GenSigTimeoutTime" BU_SG_REL_ L_UWB_RL_FD SG_ 402391152 PNI_CGW_CCU_3 1500;
BA_REL_ "GenSigTimeoutTime" BU_SG_REL_ L_UWB_RR_FD SG_ 402391152 PNI_CGW_CCU_3 1500;
BA_REL_ "GenSigTimeoutTime" BU_SG_REL_ L_UWB_TRNK_FD SG_ 402391152 PNI_CGW_CCU_3 1500;
BA_REL_ "GenSigTimeoutTime" BU_SG_REL_ L_WPC_FD SG_ 402391152 PNI_CGW_CCU_3 1500;
BA_ "RoutingFactor" SG_ 402391152 PNI_CGW_CCU_3 0;
BA_ "UsrSigPurpose" SG_ 402391152 NM_State_CGW_CCU 8;
BA_ "UserSigValidity" SG_ 402391152 NM_State_CGW_CCU 0;
BA_REL_ "GenSigTimeoutTime" BU_SG_REL_ L_DHL_FD SG_ 402391152 NM_State_CGW_CCU 1500;
BA_REL_ "GenSigTimeoutTime" BU_SG_REL_ L_DHRL_FD SG_ 402391152 NM_State_CGW_CCU 1500;
BA_REL_ "GenSigTimeoutTime" BU_SG_REL_ L_DHRR_FD SG_ 402391152 NM_State_CGW_CCU 1500;
BA_REL_ "GenSigTimeoutTime" BU_SG_REL_ L_DHR_FD SG_ 402391152 NM_State_CGW_CCU 1500;
BA_REL_ "GenSigTimeoutTime" BU_SG_REL_ L_SAL_FD SG_ 402391152 NM_State_CGW_CCU 1500;
BA_REL_ "GenSigTimeoutTime" BU_SG_REL_ L_TPMS_FD SG_ 402391152 NM_State_CGW_CCU 1500;
BA_REL_ "GenSigTimeoutTime" BU_SG_REL_ L_UWB_BLE_MST_FD SG_ 402391152 NM_State_CGW_CCU 1500;
BA_REL_ "GenSigTimeoutTime" BU_SG_REL_ L_UWB_BLE_SLV_FD SG_ 402391152 NM_State_CGW_CCU 1500;
BA_REL_ "GenSigTimeoutTime" BU_SG_REL_ L_UWB_FL_FD SG_ 402391152 NM_State_CGW_CCU 1500;
BA_REL_ "GenSigTimeoutTime" BU_SG_REL_ L_UWB_FRNK_FD SG_ 402391152 NM_State_CGW_CCU 1500;
BA_REL_ "GenSigTimeoutTime" BU_SG_REL_ L_UWB_FR_FD SG_ 402391152 NM_State_CGW_CCU 1500;
BA_REL_ "GenSigTimeoutTime" BU_SG_REL_ L_UWB_RL_FD SG_ 402391152 NM_State_CGW_CCU 1500;
BA_REL_ "GenSigTimeoutTime" BU_SG_REL_ L_UWB_RR_FD SG_ 402391152 NM_State_CGW_CCU 1500;
BA_REL_ "GenSigTimeoutTime" BU_SG_REL_ L_UWB_TRNK_FD SG_ 402391152 NM_State_CGW_CCU 1500;
BA_REL_ "GenSigTimeoutTime" BU_SG_REL_ L_WPC_FD SG_ 402391152 NM_State_CGW_CCU 1500;
BA_ "RoutingFactor" SG_ 402391152 NM_State_CGW_CCU 0;
BA_ "Description" SG_ 402391152 PNI_CGW_CCU "For PN ECUs, each partial networking cluster (PNC) is assigned a Partial Networking Information bit. The Partial Networking Information bit field contains the signals PNC_1 to PNC_224.







PNC_1(All ECUs), PNC_2(OTA Cooperative ECUs), PNC_3(OTA Cooperative ECUs for infotainment channel)







PNC_2, PNC_3 signal sends to support ECUs that needed to perform the OTA cooperative function.



0 : Support ECUs are not required.



1 : Support ECUs are required.







PNC_4 ~ PNC_224 signals are individually assinged to the target ECU.



Refer to ES95480-03 for details.







Detailed information is as follows: 6. PNC Configuration @ cody-ecm";
BA_ "UsrSigPurpose" SG_ 402391152 PNI_CGW_CCU 8;
BA_ "UserSigValidity" SG_ 402391152 PNI_CGW_CCU 0;
BA_REL_ "GenSigTimeoutTime" BU_SG_REL_ L_DHL_FD SG_ 402391152 PNI_CGW_CCU 1500;
BA_REL_ "GenSigTimeoutTime" BU_SG_REL_ L_DHRL_FD SG_ 402391152 PNI_CGW_CCU 1500;
BA_REL_ "GenSigTimeoutTime" BU_SG_REL_ L_DHRR_FD SG_ 402391152 PNI_CGW_CCU 1500;
BA_REL_ "GenSigTimeoutTime" BU_SG_REL_ L_DHR_FD SG_ 402391152 PNI_CGW_CCU 1500;
BA_REL_ "GenSigTimeoutTime" BU_SG_REL_ L_SAL_FD SG_ 402391152 PNI_CGW_CCU 1500;
BA_REL_ "GenSigTimeoutTime" BU_SG_REL_ L_TPMS_FD SG_ 402391152 PNI_CGW_CCU 1500;
BA_REL_ "GenSigTimeoutTime" BU_SG_REL_ L_UWB_BLE_MST_FD SG_ 402391152 PNI_CGW_CCU 1500;
BA_REL_ "GenSigTimeoutTime" BU_SG_REL_ L_UWB_BLE_SLV_FD SG_ 402391152 PNI_CGW_CCU 1500;
BA_REL_ "GenSigTimeoutTime" BU_SG_REL_ L_UWB_FL_FD SG_ 402391152 PNI_CGW_CCU 1500;
BA_REL_ "GenSigTimeoutTime" BU_SG_REL_ L_UWB_FRNK_FD SG_ 402391152 PNI_CGW_CCU 1500;
BA_REL_ "GenSigTimeoutTime" BU_SG_REL_ L_UWB_FR_FD SG_ 402391152 PNI_CGW_CCU 1500;
BA_REL_ "GenSigTimeoutTime" BU_SG_REL_ L_UWB_RL_FD SG_ 402391152 PNI_CGW_CCU 1500;
BA_REL_ "GenSigTimeoutTime" BU_SG_REL_ L_UWB_RR_FD SG_ 402391152 PNI_CGW_CCU 1500;
BA_REL_ "GenSigTimeoutTime" BU_SG_REL_ L_UWB_TRNK_FD SG_ 402391152 PNI_CGW_CCU 1500;
BA_REL_ "GenSigTimeoutTime" BU_SG_REL_ L_WPC_FD SG_ 402391152 PNI_CGW_CCU 1500;
BA_ "RoutingFactor" SG_ 402391152 PNI_CGW_CCU 0;
BA_ "Description" SG_ 402391152 PNI_CGW_CCU_1 "For PN ECUs, each partial networking cluster (PNC) is assigned a Partial Networking Information bit. The Partial Networking Information bit field contains the signals PNC_1 to PNC_224.







PNC_1(All ECUs), PNC_2(OTA Cooperative ECUs), PNC_3(OTA Cooperative ECUs for infotainment channel)







PNC_2, PNC_3 signal sends to support ECUs that needed to perform the OTA cooperative function.



0 : Support ECUs are not required.



1 : Support ECUs are required.







PNC_4 ~ PNC_224 signals are individually assinged to the target ECU.



Refer to ES95480-03 for details.







Detailed information is as follows: 6. PNC Configuration @ cody-ecm";
BA_ "UsrSigPurpose" SG_ 402391152 PNI_CGW_CCU_1 8;
BA_ "UserSigValidity" SG_ 402391152 PNI_CGW_CCU_1 0;
BA_REL_ "GenSigTimeoutTime" BU_SG_REL_ L_DHL_FD SG_ 402391152 PNI_CGW_CCU_1 1500;
BA_REL_ "GenSigTimeoutTime" BU_SG_REL_ L_DHRL_FD SG_ 402391152 PNI_CGW_CCU_1 1500;
BA_REL_ "GenSigTimeoutTime" BU_SG_REL_ L_DHRR_FD SG_ 402391152 PNI_CGW_CCU_1 1500;
BA_REL_ "GenSigTimeoutTime" BU_SG_REL_ L_DHR_FD SG_ 402391152 PNI_CGW_CCU_1 1500;
BA_REL_ "GenSigTimeoutTime" BU_SG_REL_ L_SAL_FD SG_ 402391152 PNI_CGW_CCU_1 1500;
BA_REL_ "GenSigTimeoutTime" BU_SG_REL_ L_TPMS_FD SG_ 402391152 PNI_CGW_CCU_1 1500;
BA_REL_ "GenSigTimeoutTime" BU_SG_REL_ L_UWB_BLE_MST_FD SG_ 402391152 PNI_CGW_CCU_1 1500;
BA_REL_ "GenSigTimeoutTime" BU_SG_REL_ L_UWB_BLE_SLV_FD SG_ 402391152 PNI_CGW_CCU_1 1500;
BA_REL_ "GenSigTimeoutTime" BU_SG_REL_ L_UWB_FL_FD SG_ 402391152 PNI_CGW_CCU_1 1500;
BA_REL_ "GenSigTimeoutTime" BU_SG_REL_ L_UWB_FRNK_FD SG_ 402391152 PNI_CGW_CCU_1 1500;
BA_REL_ "GenSigTimeoutTime" BU_SG_REL_ L_UWB_FR_FD SG_ 402391152 PNI_CGW_CCU_1 1500;
BA_REL_ "GenSigTimeoutTime" BU_SG_REL_ L_UWB_RL_FD SG_ 402391152 PNI_CGW_CCU_1 1500;
BA_REL_ "GenSigTimeoutTime" BU_SG_REL_ L_UWB_RR_FD SG_ 402391152 PNI_CGW_CCU_1 1500;
BA_REL_ "GenSigTimeoutTime" BU_SG_REL_ L_UWB_TRNK_FD SG_ 402391152 PNI_CGW_CCU_1 1500;
BA_REL_ "GenSigTimeoutTime" BU_SG_REL_ L_WPC_FD SG_ 402391152 PNI_CGW_CCU_1 1500;
BA_ "RoutingFactor" SG_ 402391152 PNI_CGW_CCU_1 0;
BA_ "UsrSigPurpose" SG_ 402391152 CBV_RMR_CGW_CCU 8;
BA_ "UserSigValidity" SG_ 402391152 CBV_RMR_CGW_CCU 0;
BA_REL_ "GenSigTimeoutTime" BU_SG_REL_ L_DHL_FD SG_ 402391152 CBV_RMR_CGW_CCU 1500;
BA_REL_ "GenSigTimeoutTime" BU_SG_REL_ L_DHRL_FD SG_ 402391152 CBV_RMR_CGW_CCU 1500;
BA_REL_ "GenSigTimeoutTime" BU_SG_REL_ L_DHRR_FD SG_ 402391152 CBV_RMR_CGW_CCU 1500;
BA_REL_ "GenSigTimeoutTime" BU_SG_REL_ L_DHR_FD SG_ 402391152 CBV_RMR_CGW_CCU 1500;
BA_REL_ "GenSigTimeoutTime" BU_SG_REL_ L_SAL_FD SG_ 402391152 CBV_RMR_CGW_CCU 1500;
BA_REL_ "GenSigTimeoutTime" BU_SG_REL_ L_TPMS_FD SG_ 402391152 CBV_RMR_CGW_CCU 1500;
BA_REL_ "GenSigTimeoutTime" BU_SG_REL_ L_UWB_BLE_MST_FD SG_ 402391152 CBV_RMR_CGW_CCU 1500;
BA_REL_ "GenSigTimeoutTime" BU_SG_REL_ L_UWB_BLE_SLV_FD SG_ 402391152 CBV_RMR_CGW_CCU 1500;
BA_REL_ "GenSigTimeoutTime" BU_SG_REL_ L_UWB_FL_FD SG_ 402391152 CBV_RMR_CGW_CCU 1500;
BA_REL_ "GenSigTimeoutTime" BU_SG_REL_ L_UWB_FRNK_FD SG_ 402391152 CBV_RMR_CGW_CCU 1500;
BA_REL_ "GenSigTimeoutTime" BU_SG_REL_ L_UWB_FR_FD SG_ 402391152 CBV_RMR_CGW_CCU 1500;
BA_REL_ "GenSigTimeoutTime" BU_SG_REL_ L_UWB_RL_FD SG_ 402391152 CBV_RMR_CGW_CCU 1500;
BA_REL_ "GenSigTimeoutTime" BU_SG_REL_ L_UWB_RR_FD SG_ 402391152 CBV_RMR_CGW_CCU 1500;
BA_REL_ "GenSigTimeoutTime" BU_SG_REL_ L_UWB_TRNK_FD SG_ 402391152 CBV_RMR_CGW_CCU 1500;
BA_REL_ "GenSigTimeoutTime" BU_SG_REL_ L_WPC_FD SG_ 402391152 CBV_RMR_CGW_CCU 1500;
BA_ "RoutingFactor" SG_ 402391152 CBV_RMR_CGW_CCU 0;
BA_ "UsrSigPurpose" SG_ 402391152 CBV_NMCoID_CGW_CCU 8;
BA_ "UserSigValidity" SG_ 402391152 CBV_NMCoID_CGW_CCU 0;
BA_REL_ "GenSigTimeoutTime" BU_SG_REL_ L_DHL_FD SG_ 402391152 CBV_NMCoID_CGW_CCU 1500;
BA_REL_ "GenSigTimeoutTime" BU_SG_REL_ L_DHRL_FD SG_ 402391152 CBV_NMCoID_CGW_CCU 1500;
BA_REL_ "GenSigTimeoutTime" BU_SG_REL_ L_DHRR_FD SG_ 402391152 CBV_NMCoID_CGW_CCU 1500;
BA_REL_ "GenSigTimeoutTime" BU_SG_REL_ L_DHR_FD SG_ 402391152 CBV_NMCoID_CGW_CCU 1500;
BA_REL_ "GenSigTimeoutTime" BU_SG_REL_ L_SAL_FD SG_ 402391152 CBV_NMCoID_CGW_CCU 1500;
BA_REL_ "GenSigTimeoutTime" BU_SG_REL_ L_TPMS_FD SG_ 402391152 CBV_NMCoID_CGW_CCU 1500;
BA_REL_ "GenSigTimeoutTime" BU_SG_REL_ L_UWB_BLE_MST_FD SG_ 402391152 CBV_NMCoID_CGW_CCU 1500;
BA_REL_ "GenSigTimeoutTime" BU_SG_REL_ L_UWB_BLE_SLV_FD SG_ 402391152 CBV_NMCoID_CGW_CCU 1500;
BA_REL_ "GenSigTimeoutTime" BU_SG_REL_ L_UWB_FL_FD SG_ 402391152 CBV_NMCoID_CGW_CCU 1500;
BA_REL_ "GenSigTimeoutTime" BU_SG_REL_ L_UWB_FRNK_FD SG_ 402391152 CBV_NMCoID_CGW_CCU 1500;
BA_REL_ "GenSigTimeoutTime" BU_SG_REL_ L_UWB_FR_FD SG_ 402391152 CBV_NMCoID_CGW_CCU 1500;
BA_REL_ "GenSigTimeoutTime" BU_SG_REL_ L_UWB_RL_FD SG_ 402391152 CBV_NMCoID_CGW_CCU 1500;
BA_REL_ "GenSigTimeoutTime" BU_SG_REL_ L_UWB_RR_FD SG_ 402391152 CBV_NMCoID_CGW_CCU 1500;
BA_REL_ "GenSigTimeoutTime" BU_SG_REL_ L_UWB_TRNK_FD SG_ 402391152 CBV_NMCoID_CGW_CCU 1500;
BA_REL_ "GenSigTimeoutTime" BU_SG_REL_ L_WPC_FD SG_ 402391152 CBV_NMCoID_CGW_CCU 1500;
BA_ "RoutingFactor" SG_ 402391152 CBV_NMCoID_CGW_CCU 0;
BA_ "VFrameFormat" BO_ 2549874733 15;
BA_ "GenMsgCycleTime" BO_ 2549874733 100;
BA_ "GenMsgCycleTimeFast" BO_ 2549874733 0;
BA_ "GenMsgDelayTime" BO_ 2549874733 10;
BA_ "GenMsgILSupport" BO_ 2549874733 0;
BA_ "GenMsgNrOfRepetition" BO_ 2549874733 0;
BA_ "NmAsrMessage" BO_ 2549874733 1;
BA_ "UsrSigPurpose" SG_ 2549874733 SNI_L_DHRR_FD 8;
BA_ "UserSigValidity" SG_ 2549874733 SNI_L_DHRR_FD 0;
BA_ "UsrSigPurpose" SG_ 2549874733 CBV_RMR_L_DHRR_FD 8;
BA_ "UserSigValidity" SG_ 2549874733 CBV_RMR_L_DHRR_FD 0;
BA_ "UsrSigPurpose" SG_ 2549874733 CBV_NMCoID_L_DHRR_FD 8;
BA_ "UserSigValidity" SG_ 2549874733 CBV_NMCoID_L_DHRR_FD 0;
BA_ "UsrSigPurpose" SG_ 2549874733 CBV_NMCoSRB_L_DHRR_FD 8;
BA_ "UserSigValidity" SG_ 2549874733 CBV_NMCoSRB_L_DHRR_FD 0;
BA_ "UsrSigPurpose" SG_ 2549874733 CBV_AWB_L_DHRR_FD 8;
BA_ "UserSigValidity" SG_ 2549874733 CBV_AWB_L_DHRR_FD 0;
BA_ "UsrSigPurpose" SG_ 2549874733 CBV_PNIB_L_DHRR_FD 8;
BA_ "UserSigValidity" SG_ 2549874733 CBV_PNIB_L_DHRR_FD 0;
BA_ "UsrSigPurpose" SG_ 2549874733 NRR_L_DHRR_FD 8;
BA_ "UserSigValidity" SG_ 2549874733 NRR_L_DHRR_FD 0;
BA_ "UsrSigPurpose" SG_ 2549874733 NM_State_L_DHRR_FD 8;
BA_ "UserSigValidity" SG_ 2549874733 NM_State_L_DHRR_FD 0;
BA_ "UsrSigPurpose" SG_ 2549874733 PNI_L_DHRR_FD 8;
BA_ "UserSigValidity" SG_ 2549874733 PNI_L_DHRR_FD 0;
BA_ "UsrSigPurpose" SG_ 2549874733 PNI_L_DHRR_FD_1 8;
BA_ "UserSigValidity" SG_ 2549874733 PNI_L_DHRR_FD_1 0;
BA_ "UsrSigPurpose" SG_ 2549874733 PNI_L_DHRR_FD_2 8;
BA_ "UserSigValidity" SG_ 2549874733 PNI_L_DHRR_FD_2 0;
BA_ "UsrSigPurpose" SG_ 2549874733 PNI_L_DHRR_FD_3 8;
BA_ "UserSigValidity" SG_ 2549874733 PNI_L_DHRR_FD_3 0;
BA_ "VFrameFormat" BO_ 2549874720 15;
BA_ "GenMsgCycleTime" BO_ 2549874720 100;
BA_ "GenMsgCycleTimeFast" BO_ 2549874720 0;
BA_ "GenMsgDelayTime" BO_ 2549874720 10;
BA_ "GenMsgILSupport" BO_ 2549874720 0;
BA_ "GenMsgNrOfRepetition" BO_ 2549874720 0;
BA_ "NmAsrMessage" BO_ 2549874720 1;
BA_ "UsrSigPurpose" SG_ 2549874720 SNI_L_UWB_BLE_MST_FD 8;
BA_ "UserSigValidity" SG_ 2549874720 SNI_L_UWB_BLE_MST_FD 0;
BA_ "UsrSigPurpose" SG_ 2549874720 CBV_RMR_L_UWB_BLE_MST_FD 8;
BA_ "UserSigValidity" SG_ 2549874720 CBV_RMR_L_UWB_BLE_MST_FD 0;
BA_ "UsrSigPurpose" SG_ 2549874720 CBV_NMCoID_L_UWB_BLE_MST_FD 8;
BA_ "UserSigValidity" SG_ 2549874720 CBV_NMCoID_L_UWB_BLE_MST_FD 0;
BA_ "UsrSigPurpose" SG_ 2549874720 CBV_NMCoSRB_L_UWB_BLE_MST_FD 8;
BA_ "UserSigValidity" SG_ 2549874720 CBV_NMCoSRB_L_UWB_BLE_MST_FD 0;
BA_ "UsrSigPurpose" SG_ 2549874720 CBV_AWB_L_UWB_BLE_MST_FD 8;
BA_ "UserSigValidity" SG_ 2549874720 CBV_AWB_L_UWB_BLE_MST_FD 0;
BA_ "UsrSigPurpose" SG_ 2549874720 CBV_PNIB_L_UWB_BLE_MST_FD 8;
BA_ "UserSigValidity" SG_ 2549874720 CBV_PNIB_L_UWB_BLE_MST_FD 0;
BA_ "UsrSigPurpose" SG_ 2549874720 NRR_L_UWB_BLE_MST_FD 8;
BA_ "UserSigValidity" SG_ 2549874720 NRR_L_UWB_BLE_MST_FD 0;
BA_ "UsrSigPurpose" SG_ 2549874720 NM_State_L_UWB_BLE_MST_FD 8;
BA_ "UserSigValidity" SG_ 2549874720 NM_State_L_UWB_BLE_MST_FD 0;
BA_ "UsrSigPurpose" SG_ 2549874720 PNI_L_UWB_BLE_MST_FD 8;
BA_ "UserSigValidity" SG_ 2549874720 PNI_L_UWB_BLE_MST_FD 0;
BA_ "UsrSigPurpose" SG_ 2549874720 PNI_L_UWB_BLE_MST_FD_1 8;
BA_ "UserSigValidity" SG_ 2549874720 PNI_L_UWB_BLE_MST_FD_1 0;
BA_ "UsrSigPurpose" SG_ 2549874720 PNI_L_UWB_BLE_MST_FD_2 8;
BA_ "UserSigValidity" SG_ 2549874720 PNI_L_UWB_BLE_MST_FD_2 0;
BA_ "UsrSigPurpose" SG_ 2549874720 PNI_L_UWB_BLE_MST_FD_3 8;
BA_ "UserSigValidity" SG_ 2549874720 PNI_L_UWB_BLE_MST_FD_3 0;
BA_ "VFrameFormat" BO_ 2549874726 15;
BA_ "GenMsgCycleTime" BO_ 2549874726 100;
BA_ "GenMsgCycleTimeFast" BO_ 2549874726 0;
BA_ "GenMsgDelayTime" BO_ 2549874726 10;
BA_ "GenMsgILSupport" BO_ 2549874726 0;
BA_ "GenMsgNrOfRepetition" BO_ 2549874726 0;
BA_ "NmAsrMessage" BO_ 2549874726 1;
BA_ "UsrSigPurpose" SG_ 2549874726 SNI_L_UWB_RR_FD 8;
BA_ "UserSigValidity" SG_ 2549874726 SNI_L_UWB_RR_FD 0;
BA_ "UsrSigPurpose" SG_ 2549874726 CBV_RMR_L_UWB_RR_FD 8;
BA_ "UserSigValidity" SG_ 2549874726 CBV_RMR_L_UWB_RR_FD 0;
BA_ "UsrSigPurpose" SG_ 2549874726 CBV_NMCoID_L_UWB_RR_FD 8;
BA_ "UserSigValidity" SG_ 2549874726 CBV_NMCoID_L_UWB_RR_FD 0;
BA_ "UsrSigPurpose" SG_ 2549874726 CBV_NMCoSRB_L_UWB_RR_FD 8;
BA_ "UserSigValidity" SG_ 2549874726 CBV_NMCoSRB_L_UWB_RR_FD 0;
BA_ "UsrSigPurpose" SG_ 2549874726 CBV_AWB_L_UWB_RR_FD 8;
BA_ "UserSigValidity" SG_ 2549874726 CBV_AWB_L_UWB_RR_FD 0;
BA_ "UsrSigPurpose" SG_ 2549874726 CBV_PNIB_L_UWB_RR_FD 8;
BA_ "UserSigValidity" SG_ 2549874726 CBV_PNIB_L_UWB_RR_FD 0;
BA_ "UsrSigPurpose" SG_ 2549874726 NRR_L_UWB_RR_FD 8;
BA_ "UserSigValidity" SG_ 2549874726 NRR_L_UWB_RR_FD 0;
BA_ "UsrSigPurpose" SG_ 2549874726 NM_State_L_UWB_RR_FD 8;
BA_ "UserSigValidity" SG_ 2549874726 NM_State_L_UWB_RR_FD 0;
BA_ "UsrSigPurpose" SG_ 2549874726 PNI_L_UWB_RR_FD 8;
BA_ "UserSigValidity" SG_ 2549874726 PNI_L_UWB_RR_FD 0;
BA_ "UsrSigPurpose" SG_ 2549874726 PNI_L_UWB_RR_FD_1 8;
BA_ "UserSigValidity" SG_ 2549874726 PNI_L_UWB_RR_FD_1 0;
BA_ "UsrSigPurpose" SG_ 2549874726 PNI_L_UWB_RR_FD_2 8;
BA_ "UserSigValidity" SG_ 2549874726 PNI_L_UWB_RR_FD_2 0;
BA_ "UsrSigPurpose" SG_ 2549874726 PNI_L_UWB_RR_FD_3 8;
BA_ "UserSigValidity" SG_ 2549874726 PNI_L_UWB_RR_FD_3 0;
BA_ "VFrameFormat" BO_ 2549874721 15;
BA_ "GenMsgCycleTime" BO_ 2549874721 100;
BA_ "GenMsgCycleTimeFast" BO_ 2549874721 0;
BA_ "GenMsgDelayTime" BO_ 2549874721 10;
BA_ "GenMsgILSupport" BO_ 2549874721 0;
BA_ "GenMsgNrOfRepetition" BO_ 2549874721 0;
BA_ "NmAsrMessage" BO_ 2549874721 1;
BA_ "UsrSigPurpose" SG_ 2549874721 SNI_L_UWB_BLE_SLV_FD 8;
BA_ "UserSigValidity" SG_ 2549874721 SNI_L_UWB_BLE_SLV_FD 0;
BA_ "UsrSigPurpose" SG_ 2549874721 CBV_RMR_L_UWB_BLE_SLV_FD 8;
BA_ "UserSigValidity" SG_ 2549874721 CBV_RMR_L_UWB_BLE_SLV_FD 0;
BA_ "UsrSigPurpose" SG_ 2549874721 CBV_NMCoID_L_UWB_BLE_SLV_FD 8;
BA_ "UserSigValidity" SG_ 2549874721 CBV_NMCoID_L_UWB_BLE_SLV_FD 0;
BA_ "UsrSigPurpose" SG_ 2549874721 CBV_NMCoSRB_L_UWB_BLE_SLV_FD 8;
BA_ "UserSigValidity" SG_ 2549874721 CBV_NMCoSRB_L_UWB_BLE_SLV_FD 0;
BA_ "UsrSigPurpose" SG_ 2549874721 CBV_AWB_L_UWB_BLE_SLV_FD 8;
BA_ "UserSigValidity" SG_ 2549874721 CBV_AWB_L_UWB_BLE_SLV_FD 0;
BA_ "UsrSigPurpose" SG_ 2549874721 CBV_PNIB_L_UWB_BLE_SLV_FD 8;
BA_ "UserSigValidity" SG_ 2549874721 CBV_PNIB_L_UWB_BLE_SLV_FD 0;
BA_ "UsrSigPurpose" SG_ 2549874721 NRR_L_UWB_BLE_SLV_FD 8;
BA_ "UserSigValidity" SG_ 2549874721 NRR_L_UWB_BLE_SLV_FD 0;
BA_ "UsrSigPurpose" SG_ 2549874721 NM_State_L_UWB_BLE_SLV_FD 8;
BA_ "UserSigValidity" SG_ 2549874721 NM_State_L_UWB_BLE_SLV_FD 0;
BA_ "UsrSigPurpose" SG_ 2549874721 PNI_L_UWB_BLE_SLV_FD 8;
BA_ "UserSigValidity" SG_ 2549874721 PNI_L_UWB_BLE_SLV_FD 0;
BA_ "UsrSigPurpose" SG_ 2549874721 PNI_L_UWB_BLE_SLV_FD_1 8;
BA_ "UserSigValidity" SG_ 2549874721 PNI_L_UWB_BLE_SLV_FD_1 0;
BA_ "UsrSigPurpose" SG_ 2549874721 PNI_L_UWB_BLE_SLV_FD_2 8;
BA_ "UserSigValidity" SG_ 2549874721 PNI_L_UWB_BLE_SLV_FD_2 0;
BA_ "UsrSigPurpose" SG_ 2549874721 PNI_L_UWB_BLE_SLV_FD_3 8;
BA_ "UserSigValidity" SG_ 2549874721 PNI_L_UWB_BLE_SLV_FD_3 0;
BA_ "VFrameFormat" BO_ 2549874723 15;
BA_ "GenMsgCycleTime" BO_ 2549874723 100;
BA_ "GenMsgCycleTimeFast" BO_ 2549874723 0;
BA_ "GenMsgDelayTime" BO_ 2549874723 10;
BA_ "GenMsgILSupport" BO_ 2549874723 0;
BA_ "GenMsgNrOfRepetition" BO_ 2549874723 0;
BA_ "NmAsrMessage" BO_ 2549874723 1;
BA_ "UsrSigPurpose" SG_ 2549874723 SNI_L_UWB_FR_FD 8;
BA_ "UserSigValidity" SG_ 2549874723 SNI_L_UWB_FR_FD 0;
BA_ "UsrSigPurpose" SG_ 2549874723 CBV_RMR_L_UWB_FR_FD 8;
BA_ "UserSigValidity" SG_ 2549874723 CBV_RMR_L_UWB_FR_FD 0;
BA_ "UsrSigPurpose" SG_ 2549874723 CBV_NMCoID_L_UWB_FR_FD 8;
BA_ "UserSigValidity" SG_ 2549874723 CBV_NMCoID_L_UWB_FR_FD 0;
BA_ "UsrSigPurpose" SG_ 2549874723 CBV_NMCoSRB_L_UWB_FR_FD 8;
BA_ "UserSigValidity" SG_ 2549874723 CBV_NMCoSRB_L_UWB_FR_FD 0;
BA_ "UsrSigPurpose" SG_ 2549874723 CBV_AWB_L_UWB_FR_FD 8;
BA_ "UserSigValidity" SG_ 2549874723 CBV_AWB_L_UWB_FR_FD 0;
BA_ "UsrSigPurpose" SG_ 2549874723 CBV_PNIB_L_UWB_FR_FD 8;
BA_ "UserSigValidity" SG_ 2549874723 CBV_PNIB_L_UWB_FR_FD 0;
BA_ "UsrSigPurpose" SG_ 2549874723 NRR_L_UWB_FR_FD 8;
BA_ "UserSigValidity" SG_ 2549874723 NRR_L_UWB_FR_FD 0;
BA_ "UsrSigPurpose" SG_ 2549874723 NM_State_L_UWB_FR_FD 8;
BA_ "UserSigValidity" SG_ 2549874723 NM_State_L_UWB_FR_FD 0;
BA_ "UsrSigPurpose" SG_ 2549874723 PNI_L_UWB_FR_FD 8;
BA_ "UserSigValidity" SG_ 2549874723 PNI_L_UWB_FR_FD 0;
BA_ "UsrSigPurpose" SG_ 2549874723 PNI_L_UWB_FR_FD_1 8;
BA_ "UserSigValidity" SG_ 2549874723 PNI_L_UWB_FR_FD_1 0;
BA_ "UsrSigPurpose" SG_ 2549874723 PNI_L_UWB_FR_FD_2 8;
BA_ "UserSigValidity" SG_ 2549874723 PNI_L_UWB_FR_FD_2 0;
BA_ "UsrSigPurpose" SG_ 2549874723 PNI_L_UWB_FR_FD_3 8;
BA_ "UserSigValidity" SG_ 2549874723 PNI_L_UWB_FR_FD_3 0;
BA_ "VFrameFormat" BO_ 2549874732 15;
BA_ "GenMsgCycleTime" BO_ 2549874732 100;
BA_ "GenMsgCycleTimeFast" BO_ 2549874732 0;
BA_ "GenMsgDelayTime" BO_ 2549874732 10;
BA_ "GenMsgILSupport" BO_ 2549874732 0;
BA_ "GenMsgNrOfRepetition" BO_ 2549874732 0;
BA_ "NmAsrMessage" BO_ 2549874732 1;
BA_ "UsrSigPurpose" SG_ 2549874732 SNI_L_DHRL_FD 8;
BA_ "UserSigValidity" SG_ 2549874732 SNI_L_DHRL_FD 0;
BA_ "UsrSigPurpose" SG_ 2549874732 CBV_RMR_L_DHRL_FD 8;
BA_ "UserSigValidity" SG_ 2549874732 CBV_RMR_L_DHRL_FD 0;
BA_ "UsrSigPurpose" SG_ 2549874732 CBV_NMCoID_L_DHRL_FD 8;
BA_ "UserSigValidity" SG_ 2549874732 CBV_NMCoID_L_DHRL_FD 0;
BA_ "UsrSigPurpose" SG_ 2549874732 CBV_NMCoSRB_L_DHRL_FD 8;
BA_ "UserSigValidity" SG_ 2549874732 CBV_NMCoSRB_L_DHRL_FD 0;
BA_ "UsrSigPurpose" SG_ 2549874732 CBV_AWB_L_DHRL_FD 8;
BA_ "UserSigValidity" SG_ 2549874732 CBV_AWB_L_DHRL_FD 0;
BA_ "UsrSigPurpose" SG_ 2549874732 CBV_PNIB_L_DHRL_FD 8;
BA_ "UserSigValidity" SG_ 2549874732 CBV_PNIB_L_DHRL_FD 0;
BA_ "UsrSigPurpose" SG_ 2549874732 NRR_L_DHRL_FD 8;
BA_ "UserSigValidity" SG_ 2549874732 NRR_L_DHRL_FD 0;
BA_ "UsrSigPurpose" SG_ 2549874732 NM_State_L_DHRL_FD 8;
BA_ "UserSigValidity" SG_ 2549874732 NM_State_L_DHRL_FD 0;
BA_ "UsrSigPurpose" SG_ 2549874732 PNI_L_DHRL_FD 8;
BA_ "UserSigValidity" SG_ 2549874732 PNI_L_DHRL_FD 0;
BA_ "UsrSigPurpose" SG_ 2549874732 PNI_L_DHRL_FD_1 8;
BA_ "UserSigValidity" SG_ 2549874732 PNI_L_DHRL_FD_1 0;
BA_ "UsrSigPurpose" SG_ 2549874732 PNI_L_DHRL_FD_2 8;
BA_ "UserSigValidity" SG_ 2549874732 PNI_L_DHRL_FD_2 0;
BA_ "UsrSigPurpose" SG_ 2549874732 PNI_L_DHRL_FD_3 8;
BA_ "UserSigValidity" SG_ 2549874732 PNI_L_DHRL_FD_3 0;
BA_ "VFrameFormat" BO_ 2549874727 15;
BA_ "GenMsgCycleTime" BO_ 2549874727 100;
BA_ "GenMsgCycleTimeFast" BO_ 2549874727 0;
BA_ "GenMsgDelayTime" BO_ 2549874727 10;
BA_ "GenMsgILSupport" BO_ 2549874727 0;
BA_ "GenMsgNrOfRepetition" BO_ 2549874727 0;
BA_ "NmAsrMessage" BO_ 2549874727 1;
BA_ "UsrSigPurpose" SG_ 2549874727 SNI_L_UWB_TRNK_FD 8;
BA_ "UserSigValidity" SG_ 2549874727 SNI_L_UWB_TRNK_FD 0;
BA_ "UsrSigPurpose" SG_ 2549874727 CBV_RMR_L_UWB_TRNK_FD 8;
BA_ "UserSigValidity" SG_ 2549874727 CBV_RMR_L_UWB_TRNK_FD 0;
BA_ "UsrSigPurpose" SG_ 2549874727 CBV_NMCoID_L_UWB_TRNK_FD 8;
BA_ "UserSigValidity" SG_ 2549874727 CBV_NMCoID_L_UWB_TRNK_FD 0;
BA_ "UsrSigPurpose" SG_ 2549874727 CBV_NMCoSRB_L_UWB_TRNK_FD 8;
BA_ "UserSigValidity" SG_ 2549874727 CBV_NMCoSRB_L_UWB_TRNK_FD 0;
BA_ "UsrSigPurpose" SG_ 2549874727 CBV_AWB_L_UWB_TRNK_FD 8;
BA_ "UserSigValidity" SG_ 2549874727 CBV_AWB_L_UWB_TRNK_FD 0;
BA_ "UsrSigPurpose" SG_ 2549874727 CBV_PNIB_L_UWB_TRNK_FD 8;
BA_ "UserSigValidity" SG_ 2549874727 CBV_PNIB_L_UWB_TRNK_FD 0;
BA_ "UsrSigPurpose" SG_ 2549874727 NRR_L_UWB_TRNK_FD 8;
BA_ "UserSigValidity" SG_ 2549874727 NRR_L_UWB_TRNK_FD 0;
BA_ "UsrSigPurpose" SG_ 2549874727 NM_State_L_UWB_TRNK_FD 8;
BA_ "UserSigValidity" SG_ 2549874727 NM_State_L_UWB_TRNK_FD 0;
BA_ "UsrSigPurpose" SG_ 2549874727 PNI_L_UWB_TRNK_FD 8;
BA_ "UserSigValidity" SG_ 2549874727 PNI_L_UWB_TRNK_FD 0;
BA_ "UsrSigPurpose" SG_ 2549874727 PNI_L_UWB_TRNK_FD_1 8;
BA_ "UserSigValidity" SG_ 2549874727 PNI_L_UWB_TRNK_FD_1 0;
BA_ "UsrSigPurpose" SG_ 2549874727 PNI_L_UWB_TRNK_FD_2 8;
BA_ "UserSigValidity" SG_ 2549874727 PNI_L_UWB_TRNK_FD_2 0;
BA_ "UsrSigPurpose" SG_ 2549874727 PNI_L_UWB_TRNK_FD_3 8;
BA_ "UserSigValidity" SG_ 2549874727 PNI_L_UWB_TRNK_FD_3 0;
BA_ "VFrameFormat" BO_ 2549874724 15;
BA_ "GenMsgCycleTime" BO_ 2549874724 100;
BA_ "GenMsgCycleTimeFast" BO_ 2549874724 0;
BA_ "GenMsgDelayTime" BO_ 2549874724 10;
BA_ "GenMsgILSupport" BO_ 2549874724 0;
BA_ "GenMsgNrOfRepetition" BO_ 2549874724 0;
BA_ "NmAsrMessage" BO_ 2549874724 1;
BA_ "UsrSigPurpose" SG_ 2549874724 SNI_L_UWB_FRNK_FD 8;
BA_ "UserSigValidity" SG_ 2549874724 SNI_L_UWB_FRNK_FD 0;
BA_ "UsrSigPurpose" SG_ 2549874724 CBV_RMR_L_UWB_FRNK_FD 8;
BA_ "UserSigValidity" SG_ 2549874724 CBV_RMR_L_UWB_FRNK_FD 0;
BA_ "UsrSigPurpose" SG_ 2549874724 CBV_NMCoID_L_UWB_FRNK_FD 8;
BA_ "UserSigValidity" SG_ 2549874724 CBV_NMCoID_L_UWB_FRNK_FD 0;
BA_ "UsrSigPurpose" SG_ 2549874724 CBV_NMCoSRB_L_UWB_FRNK_FD 8;
BA_ "UserSigValidity" SG_ 2549874724 CBV_NMCoSRB_L_UWB_FRNK_FD 0;
BA_ "UsrSigPurpose" SG_ 2549874724 CBV_AWB_L_UWB_FRNK_FD 8;
BA_ "UserSigValidity" SG_ 2549874724 CBV_AWB_L_UWB_FRNK_FD 0;
BA_ "UsrSigPurpose" SG_ 2549874724 CBV_PNIB_L_UWB_FRNK_FD 8;
BA_ "UserSigValidity" SG_ 2549874724 CBV_PNIB_L_UWB_FRNK_FD 0;
BA_ "UsrSigPurpose" SG_ 2549874724 NRR_L_UWB_FRNK_FD 8;
BA_ "UserSigValidity" SG_ 2549874724 NRR_L_UWB_FRNK_FD 0;
BA_ "UsrSigPurpose" SG_ 2549874724 NM_State_L_UWB_FRNK_FD 8;
BA_ "UserSigValidity" SG_ 2549874724 NM_State_L_UWB_FRNK_FD 0;
BA_ "UsrSigPurpose" SG_ 2549874724 PNI_L_UWB_FRNK_FD 8;
BA_ "UserSigValidity" SG_ 2549874724 PNI_L_UWB_FRNK_FD 0;
BA_ "UsrSigPurpose" SG_ 2549874724 PNI_L_UWB_FRNK_FD_1 8;
BA_ "UserSigValidity" SG_ 2549874724 PNI_L_UWB_FRNK_FD_1 0;
BA_ "UsrSigPurpose" SG_ 2549874724 PNI_L_UWB_FRNK_FD_2 8;
BA_ "UserSigValidity" SG_ 2549874724 PNI_L_UWB_FRNK_FD_2 0;
BA_ "UsrSigPurpose" SG_ 2549874724 PNI_L_UWB_FRNK_FD_3 8;
BA_ "UserSigValidity" SG_ 2549874724 PNI_L_UWB_FRNK_FD_3 0;
BA_ "VFrameFormat" BO_ 2549874722 15;
BA_ "GenMsgCycleTime" BO_ 2549874722 100;
BA_ "GenMsgCycleTimeFast" BO_ 2549874722 0;
BA_ "GenMsgDelayTime" BO_ 2549874722 10;
BA_ "GenMsgILSupport" BO_ 2549874722 0;
BA_ "GenMsgNrOfRepetition" BO_ 2549874722 0;
BA_ "NmAsrMessage" BO_ 2549874722 1;
BA_ "UsrSigPurpose" SG_ 2549874722 SNI_L_UWB_FL_FD 8;
BA_ "UserSigValidity" SG_ 2549874722 SNI_L_UWB_FL_FD 0;
BA_ "UsrSigPurpose" SG_ 2549874722 CBV_RMR_L_UWB_FL_FD 8;
BA_ "UserSigValidity" SG_ 2549874722 CBV_RMR_L_UWB_FL_FD 0;
BA_ "UsrSigPurpose" SG_ 2549874722 CBV_NMCoID_L_UWB_FL_FD 8;
BA_ "UserSigValidity" SG_ 2549874722 CBV_NMCoID_L_UWB_FL_FD 0;
BA_ "UsrSigPurpose" SG_ 2549874722 CBV_NMCoSRB_L_UWB_FL_FD 8;
BA_ "UserSigValidity" SG_ 2549874722 CBV_NMCoSRB_L_UWB_FL_FD 0;
BA_ "UsrSigPurpose" SG_ 2549874722 CBV_AWB_L_UWB_FL_FD 8;
BA_ "UserSigValidity" SG_ 2549874722 CBV_AWB_L_UWB_FL_FD 0;
BA_ "UsrSigPurpose" SG_ 2549874722 CBV_PNIB_L_UWB_FL_FD 8;
BA_ "UserSigValidity" SG_ 2549874722 CBV_PNIB_L_UWB_FL_FD 0;
BA_ "UsrSigPurpose" SG_ 2549874722 NRR_L_UWB_FL_FD 8;
BA_ "UserSigValidity" SG_ 2549874722 NRR_L_UWB_FL_FD 0;
BA_ "UsrSigPurpose" SG_ 2549874722 NM_State_L_UWB_FL_FD 8;
BA_ "UserSigValidity" SG_ 2549874722 NM_State_L_UWB_FL_FD 0;
BA_ "UsrSigPurpose" SG_ 2549874722 PNI_L_UWB_FL_FD 8;
BA_ "UserSigValidity" SG_ 2549874722 PNI_L_UWB_FL_FD 0;
BA_ "UsrSigPurpose" SG_ 2549874722 PNI_L_UWB_FL_FD_1 8;
BA_ "UserSigValidity" SG_ 2549874722 PNI_L_UWB_FL_FD_1 0;
BA_ "UsrSigPurpose" SG_ 2549874722 PNI_L_UWB_FL_FD_2 8;
BA_ "UserSigValidity" SG_ 2549874722 PNI_L_UWB_FL_FD_2 0;
BA_ "UsrSigPurpose" SG_ 2549874722 PNI_L_UWB_FL_FD_3 8;
BA_ "UserSigValidity" SG_ 2549874722 PNI_L_UWB_FL_FD_3 0;
BA_ "VFrameFormat" BO_ 2549874816 15;
BA_ "GenMsgCycleTime" BO_ 2549874816 100;
BA_ "GenMsgCycleTimeFast" BO_ 2549874816 0;
BA_ "GenMsgDelayTime" BO_ 2549874816 10;
BA_ "GenMsgILSupport" BO_ 2549874816 0;
BA_ "GenMsgNrOfRepetition" BO_ 2549874816 0;
BA_ "NmAsrMessage" BO_ 2549874816 1;
BA_ "UsrSigPurpose" SG_ 2549874816 SNI_GW_BDC_FD 8;
BA_ "UserSigValidity" SG_ 2549874816 SNI_GW_BDC_FD 0;
BA_ "UsrSigPurpose" SG_ 2549874816 CBV_RMR_GW_BDC_FD 8;
BA_ "UserSigValidity" SG_ 2549874816 CBV_RMR_GW_BDC_FD 0;
BA_ "UsrSigPurpose" SG_ 2549874816 CBV_NMCoID_GW_BDC_FD 8;
BA_ "UserSigValidity" SG_ 2549874816 CBV_NMCoID_GW_BDC_FD 0;
BA_ "UsrSigPurpose" SG_ 2549874816 CBV_NMCoSRB_GW_BDC_FD 8;
BA_ "UserSigValidity" SG_ 2549874816 CBV_NMCoSRB_GW_BDC_FD 0;
BA_ "UsrSigPurpose" SG_ 2549874816 CBV_AWB_GW_BDC_FD 8;
BA_ "UserSigValidity" SG_ 2549874816 CBV_AWB_GW_BDC_FD 0;
BA_ "UsrSigPurpose" SG_ 2549874816 CBV_PNIB_GW_BDC_FD 8;
BA_ "UserSigValidity" SG_ 2549874816 CBV_PNIB_GW_BDC_FD 0;
BA_ "UsrSigPurpose" SG_ 2549874816 NRR_GW_BDC_FD 8;
BA_ "UserSigValidity" SG_ 2549874816 NRR_GW_BDC_FD 0;
BA_ "UsrSigPurpose" SG_ 2549874816 NM_State_GW_BDC_FD 8;
BA_ "UserSigValidity" SG_ 2549874816 NM_State_GW_BDC_FD 0;
BA_ "UsrSigPurpose" SG_ 2549874816 PNI_GW_BDC_FD 8;
BA_ "UserSigValidity" SG_ 2549874816 PNI_GW_BDC_FD 0;
BA_ "UsrSigPurpose" SG_ 2549874816 PNI_GW_BDC_FD_1 8;
BA_ "UserSigValidity" SG_ 2549874816 PNI_GW_BDC_FD_1 0;
BA_ "UsrSigPurpose" SG_ 2549874816 PNI_GW_BDC_FD_2 8;
BA_ "UserSigValidity" SG_ 2549874816 PNI_GW_BDC_FD_2 0;
BA_ "UsrSigPurpose" SG_ 2549874816 PNI_GW_BDC_FD_3 8;
BA_ "UserSigValidity" SG_ 2549874816 PNI_GW_BDC_FD_3 0;
BA_ "VFrameFormat" BO_ 2549874725 15;
BA_ "GenMsgCycleTime" BO_ 2549874725 100;
BA_ "GenMsgCycleTimeFast" BO_ 2549874725 0;
BA_ "GenMsgDelayTime" BO_ 2549874725 10;
BA_ "GenMsgILSupport" BO_ 2549874725 0;
BA_ "GenMsgNrOfRepetition" BO_ 2549874725 0;
BA_ "NmAsrMessage" BO_ 2549874725 1;
BA_ "UsrSigPurpose" SG_ 2549874725 SNI_L_UWB_RL_FD 8;
BA_ "UserSigValidity" SG_ 2549874725 SNI_L_UWB_RL_FD 0;
BA_ "UsrSigPurpose" SG_ 2549874725 CBV_RMR_L_UWB_RL_FD 8;
BA_ "UserSigValidity" SG_ 2549874725 CBV_RMR_L_UWB_RL_FD 0;
BA_ "UsrSigPurpose" SG_ 2549874725 CBV_NMCoID_L_UWB_RL_FD 8;
BA_ "UserSigValidity" SG_ 2549874725 CBV_NMCoID_L_UWB_RL_FD 0;
BA_ "UsrSigPurpose" SG_ 2549874725 CBV_NMCoSRB_L_UWB_RL_FD 8;
BA_ "UserSigValidity" SG_ 2549874725 CBV_NMCoSRB_L_UWB_RL_FD 0;
BA_ "UsrSigPurpose" SG_ 2549874725 CBV_AWB_L_UWB_RL_FD 8;
BA_ "UserSigValidity" SG_ 2549874725 CBV_AWB_L_UWB_RL_FD 0;
BA_ "UsrSigPurpose" SG_ 2549874725 CBV_PNIB_L_UWB_RL_FD 8;
BA_ "UserSigValidity" SG_ 2549874725 CBV_PNIB_L_UWB_RL_FD 0;
BA_ "UsrSigPurpose" SG_ 2549874725 NRR_L_UWB_RL_FD 8;
BA_ "UserSigValidity" SG_ 2549874725 NRR_L_UWB_RL_FD 0;
BA_ "UsrSigPurpose" SG_ 2549874725 NM_State_L_UWB_RL_FD 8;
BA_ "UserSigValidity" SG_ 2549874725 NM_State_L_UWB_RL_FD 0;
BA_ "UsrSigPurpose" SG_ 2549874725 PNI_L_UWB_RL_FD 8;
BA_ "UserSigValidity" SG_ 2549874725 PNI_L_UWB_RL_FD 0;
BA_ "UsrSigPurpose" SG_ 2549874725 PNI_L_UWB_RL_FD_1 8;
BA_ "UserSigValidity" SG_ 2549874725 PNI_L_UWB_RL_FD_1 0;
BA_ "UsrSigPurpose" SG_ 2549874725 PNI_L_UWB_RL_FD_2 8;
BA_ "UserSigValidity" SG_ 2549874725 PNI_L_UWB_RL_FD_2 0;
BA_ "UsrSigPurpose" SG_ 2549874725 PNI_L_UWB_RL_FD_3 8;
BA_ "UserSigValidity" SG_ 2549874725 PNI_L_UWB_RL_FD_3 0;
BA_ "VFrameFormat" BO_ 2549874857 15;
BA_ "GenMsgCycleTime" BO_ 2549874857 100;
BA_ "GenMsgCycleTimeFast" BO_ 2549874857 0;
BA_ "GenMsgDelayTime" BO_ 2549874857 10;
BA_ "GenMsgILSupport" BO_ 2549874857 0;
BA_ "GenMsgNrOfRepetition" BO_ 2549874857 0;
BA_ "NmAsrMessage" BO_ 2549874857 1;
BA_ "UsrSigPurpose" SG_ 2549874857 SNI_L_SAL_FD 8;
BA_ "UserSigValidity" SG_ 2549874857 SNI_L_SAL_FD 0;
BA_ "UsrSigPurpose" SG_ 2549874857 CBV_RMR_L_SAL_FD 8;
BA_ "UserSigValidity" SG_ 2549874857 CBV_RMR_L_SAL_FD 0;
BA_ "UsrSigPurpose" SG_ 2549874857 CBV_NMCoID_L_SAL_FD 8;
BA_ "UserSigValidity" SG_ 2549874857 CBV_NMCoID_L_SAL_FD 0;
BA_ "UsrSigPurpose" SG_ 2549874857 CBV_NMCoSRB_L_SAL_FD 8;
BA_ "UserSigValidity" SG_ 2549874857 CBV_NMCoSRB_L_SAL_FD 0;
BA_ "UsrSigPurpose" SG_ 2549874857 CBV_AWB_L_SAL_FD 8;
BA_ "UserSigValidity" SG_ 2549874857 CBV_AWB_L_SAL_FD 0;
BA_ "UsrSigPurpose" SG_ 2549874857 CBV_PNIB_L_SAL_FD 8;
BA_ "UserSigValidity" SG_ 2549874857 CBV_PNIB_L_SAL_FD 0;
BA_ "UsrSigPurpose" SG_ 2549874857 NRR_L_SAL_FD 8;
BA_ "UserSigValidity" SG_ 2549874857 NRR_L_SAL_FD 0;
BA_ "UsrSigPurpose" SG_ 2549874857 NM_State_L_SAL_FD 8;
BA_ "UserSigValidity" SG_ 2549874857 NM_State_L_SAL_FD 0;
BA_ "UsrSigPurpose" SG_ 2549874857 PNI_L_SAL_FD 8;
BA_ "UserSigValidity" SG_ 2549874857 PNI_L_SAL_FD 0;
BA_ "UsrSigPurpose" SG_ 2549874857 PNI_L_SAL_FD_1 8;
BA_ "UserSigValidity" SG_ 2549874857 PNI_L_SAL_FD_1 0;
BA_ "UsrSigPurpose" SG_ 2549874857 PNI_L_SAL_FD_2 8;
BA_ "UserSigValidity" SG_ 2549874857 PNI_L_SAL_FD_2 0;
BA_ "UsrSigPurpose" SG_ 2549874857 PNI_L_SAL_FD_3 8;
BA_ "UserSigValidity" SG_ 2549874857 PNI_L_SAL_FD_3 0;
BA_ "VFrameFormat" BO_ 2549874718 15;
BA_ "GenMsgCycleTime" BO_ 2549874718 100;
BA_ "GenMsgCycleTimeFast" BO_ 2549874718 0;
BA_ "GenMsgDelayTime" BO_ 2549874718 10;
BA_ "GenMsgILSupport" BO_ 2549874718 0;
BA_ "GenMsgNrOfRepetition" BO_ 2549874718 0;
BA_ "NmAsrMessage" BO_ 2549874718 1;
BA_ "UsrSigPurpose" SG_ 2549874718 SNI_L_WPC_FD 8;
BA_ "UserSigValidity" SG_ 2549874718 SNI_L_WPC_FD 0;
BA_ "UsrSigPurpose" SG_ 2549874718 CBV_RMR_L_WPC_FD 8;
BA_ "UserSigValidity" SG_ 2549874718 CBV_RMR_L_WPC_FD 0;
BA_ "UsrSigPurpose" SG_ 2549874718 CBV_NMCoID_L_WPC_FD 8;
BA_ "UserSigValidity" SG_ 2549874718 CBV_NMCoID_L_WPC_FD 0;
BA_ "UsrSigPurpose" SG_ 2549874718 CBV_NMCoSRB_L_WPC_FD 8;
BA_ "UserSigValidity" SG_ 2549874718 CBV_NMCoSRB_L_WPC_FD 0;
BA_ "UsrSigPurpose" SG_ 2549874718 CBV_AWB_L_WPC_FD 8;
BA_ "UserSigValidity" SG_ 2549874718 CBV_AWB_L_WPC_FD 0;
BA_ "UsrSigPurpose" SG_ 2549874718 CBV_PNIB_L_WPC_FD 8;
BA_ "UserSigValidity" SG_ 2549874718 CBV_PNIB_L_WPC_FD 0;
BA_ "UsrSigPurpose" SG_ 2549874718 NRR_L_WPC_FD 8;
BA_ "UserSigValidity" SG_ 2549874718 NRR_L_WPC_FD 0;
BA_ "UsrSigPurpose" SG_ 2549874718 NM_State_L_WPC_FD 8;
BA_ "UserSigValidity" SG_ 2549874718 NM_State_L_WPC_FD 0;
BA_ "UsrSigPurpose" SG_ 2549874718 PNI_L_WPC_FD 8;
BA_ "UserSigValidity" SG_ 2549874718 PNI_L_WPC_FD 0;
BA_ "UsrSigPurpose" SG_ 2549874718 PNI_L_WPC_FD_1 8;
BA_ "UserSigValidity" SG_ 2549874718 PNI_L_WPC_FD_1 0;
BA_ "UsrSigPurpose" SG_ 2549874718 PNI_L_WPC_FD_2 8;
BA_ "UserSigValidity" SG_ 2549874718 PNI_L_WPC_FD_2 0;
BA_ "UsrSigPurpose" SG_ 2549874718 PNI_L_WPC_FD_3 8;
BA_ "UserSigValidity" SG_ 2549874718 PNI_L_WPC_FD_3 0;
BA_ "VFrameFormat" BO_ 2549874728 15;
BA_ "GenMsgCycleTime" BO_ 2549874728 100;
BA_ "GenMsgCycleTimeFast" BO_ 2549874728 0;
BA_ "GenMsgDelayTime" BO_ 2549874728 10;
BA_ "GenMsgILSupport" BO_ 2549874728 0;
BA_ "GenMsgNrOfRepetition" BO_ 2549874728 0;
BA_ "NmAsrMessage" BO_ 2549874728 1;
BA_ "UsrSigPurpose" SG_ 2549874728 SNI_L_TPMS_FD 8;
BA_ "UserSigValidity" SG_ 2549874728 SNI_L_TPMS_FD 0;
BA_ "UsrSigPurpose" SG_ 2549874728 CBV_RMR_L_TPMS_FD 8;
BA_ "UserSigValidity" SG_ 2549874728 CBV_RMR_L_TPMS_FD 0;
BA_ "UsrSigPurpose" SG_ 2549874728 CBV_NMCoID_L_TPMS_FD 8;
BA_ "UserSigValidity" SG_ 2549874728 CBV_NMCoID_L_TPMS_FD 0;
BA_ "UsrSigPurpose" SG_ 2549874728 CBV_NMCoSRB_L_TPMS_FD 8;
BA_ "UserSigValidity" SG_ 2549874728 CBV_NMCoSRB_L_TPMS_FD 0;
BA_ "UsrSigPurpose" SG_ 2549874728 CBV_AWB_L_TPMS_FD 8;
BA_ "UserSigValidity" SG_ 2549874728 CBV_AWB_L_TPMS_FD 0;
BA_ "UsrSigPurpose" SG_ 2549874728 CBV_PNIB_L_TPMS_FD 8;
BA_ "UserSigValidity" SG_ 2549874728 CBV_PNIB_L_TPMS_FD 0;
BA_ "UsrSigPurpose" SG_ 2549874728 NRR_L_TPMS_FD 8;
BA_ "UserSigValidity" SG_ 2549874728 NRR_L_TPMS_FD 0;
BA_ "UsrSigPurpose" SG_ 2549874728 NM_State_L_TPMS_FD 8;
BA_ "UserSigValidity" SG_ 2549874728 NM_State_L_TPMS_FD 0;
BA_ "UsrSigPurpose" SG_ 2549874728 PNI_L_TPMS_FD 8;
BA_ "UserSigValidity" SG_ 2549874728 PNI_L_TPMS_FD 0;
BA_ "UsrSigPurpose" SG_ 2549874728 PNI_L_TPMS_FD_1 8;
BA_ "UserSigValidity" SG_ 2549874728 PNI_L_TPMS_FD_1 0;
BA_ "UsrSigPurpose" SG_ 2549874728 PNI_L_TPMS_FD_2 8;
BA_ "UserSigValidity" SG_ 2549874728 PNI_L_TPMS_FD_2 0;
BA_ "UsrSigPurpose" SG_ 2549874728 PNI_L_TPMS_FD_3 8;
BA_ "UserSigValidity" SG_ 2549874728 PNI_L_TPMS_FD_3 0;
BA_ "VFrameFormat" BO_ 2549874730 15;
BA_ "GenMsgCycleTime" BO_ 2549874730 100;
BA_ "GenMsgCycleTimeFast" BO_ 2549874730 0;
BA_ "GenMsgDelayTime" BO_ 2549874730 10;
BA_ "GenMsgILSupport" BO_ 2549874730 0;
BA_ "GenMsgNrOfRepetition" BO_ 2549874730 0;
BA_ "NmAsrMessage" BO_ 2549874730 1;
BA_ "UsrSigPurpose" SG_ 2549874730 SNI_L_DHL_FD 8;
BA_ "UserSigValidity" SG_ 2549874730 SNI_L_DHL_FD 0;
BA_ "UsrSigPurpose" SG_ 2549874730 CBV_RMR_L_DHL_FD 8;
BA_ "UserSigValidity" SG_ 2549874730 CBV_RMR_L_DHL_FD 0;
BA_ "UsrSigPurpose" SG_ 2549874730 CBV_NMCoID_L_DHL_FD 8;
BA_ "UserSigValidity" SG_ 2549874730 CBV_NMCoID_L_DHL_FD 0;
BA_ "UsrSigPurpose" SG_ 2549874730 CBV_NMCoSRB_L_DHL_FD 8;
BA_ "UserSigValidity" SG_ 2549874730 CBV_NMCoSRB_L_DHL_FD 0;
BA_ "UsrSigPurpose" SG_ 2549874730 CBV_AWB_L_DHL_FD 8;
BA_ "UserSigValidity" SG_ 2549874730 CBV_AWB_L_DHL_FD 0;
BA_ "UsrSigPurpose" SG_ 2549874730 CBV_PNIB_L_DHL_FD 8;
BA_ "UserSigValidity" SG_ 2549874730 CBV_PNIB_L_DHL_FD 0;
BA_ "UsrSigPurpose" SG_ 2549874730 NRR_L_DHL_FD 8;
BA_ "UserSigValidity" SG_ 2549874730 NRR_L_DHL_FD 0;
BA_ "UsrSigPurpose" SG_ 2549874730 NM_State_L_DHL_FD 8;
BA_ "UserSigValidity" SG_ 2549874730 NM_State_L_DHL_FD 0;
BA_ "UsrSigPurpose" SG_ 2549874730 PNI_L_DHL_FD 8;
BA_ "UserSigValidity" SG_ 2549874730 PNI_L_DHL_FD 0;
BA_ "UsrSigPurpose" SG_ 2549874730 PNI_L_DHL_FD_1 8;
BA_ "UserSigValidity" SG_ 2549874730 PNI_L_DHL_FD_1 0;
BA_ "UsrSigPurpose" SG_ 2549874730 PNI_L_DHL_FD_2 8;
BA_ "UserSigValidity" SG_ 2549874730 PNI_L_DHL_FD_2 0;
BA_ "UsrSigPurpose" SG_ 2549874730 PNI_L_DHL_FD_3 8;
BA_ "UserSigValidity" SG_ 2549874730 PNI_L_DHL_FD_3 0;
BA_ "VFrameFormat" BO_ 2549874731 15;
BA_ "GenMsgCycleTime" BO_ 2549874731 100;
BA_ "GenMsgCycleTimeFast" BO_ 2549874731 0;
BA_ "GenMsgDelayTime" BO_ 2549874731 10;
BA_ "GenMsgILSupport" BO_ 2549874731 0;
BA_ "GenMsgNrOfRepetition" BO_ 2549874731 0;
BA_ "NmAsrMessage" BO_ 2549874731 1;
BA_ "UsrSigPurpose" SG_ 2549874731 SNI_L_DHR_FD 8;
BA_ "UserSigValidity" SG_ 2549874731 SNI_L_DHR_FD 0;
BA_ "UsrSigPurpose" SG_ 2549874731 CBV_RMR_L_DHR_FD 8;
BA_ "UserSigValidity" SG_ 2549874731 CBV_RMR_L_DHR_FD 0;
BA_ "UsrSigPurpose" SG_ 2549874731 CBV_NMCoID_L_DHR_FD 8;
BA_ "UserSigValidity" SG_ 2549874731 CBV_NMCoID_L_DHR_FD 0;
BA_ "UsrSigPurpose" SG_ 2549874731 CBV_NMCoSRB_L_DHR_FD 8;
BA_ "UserSigValidity" SG_ 2549874731 CBV_NMCoSRB_L_DHR_FD 0;
BA_ "UsrSigPurpose" SG_ 2549874731 CBV_AWB_L_DHR_FD 8;
BA_ "UserSigValidity" SG_ 2549874731 CBV_AWB_L_DHR_FD 0;
BA_ "UsrSigPurpose" SG_ 2549874731 CBV_PNIB_L_DHR_FD 8;
BA_ "UserSigValidity" SG_ 2549874731 CBV_PNIB_L_DHR_FD 0;
BA_ "UsrSigPurpose" SG_ 2549874731 NRR_L_DHR_FD 8;
BA_ "UserSigValidity" SG_ 2549874731 NRR_L_DHR_FD 0;
BA_ "UsrSigPurpose" SG_ 2549874731 NM_State_L_DHR_FD 8;
BA_ "UserSigValidity" SG_ 2549874731 NM_State_L_DHR_FD 0;
BA_ "UsrSigPurpose" SG_ 2549874731 PNI_L_DHR_FD 8;
BA_ "UserSigValidity" SG_ 2549874731 PNI_L_DHR_FD 0;
BA_ "UsrSigPurpose" SG_ 2549874731 PNI_L_DHR_FD_1 8;
BA_ "UserSigValidity" SG_ 2549874731 PNI_L_DHR_FD_1 0;
BA_ "UsrSigPurpose" SG_ 2549874731 PNI_L_DHR_FD_2 8;
BA_ "UserSigValidity" SG_ 2549874731 PNI_L_DHR_FD_2 0;
BA_ "UsrSigPurpose" SG_ 2549874731 PNI_L_DHR_FD_3 8;
BA_ "UserSigValidity" SG_ 2549874731 PNI_L_DHR_FD_3 0;
VAL_ 2281701488 L_WPC_FD_Crc20Val 0 "0x0x0~0xFFFF:CRCValue" 65535 "0x0x0~0xFFFF:CRCValue" ;
VAL_ 2281701488 L_WPC_FD_AlvCnt20Val 0 "0x0x0~0xFF:AlvCntValue" 255 "0x0x0~0xFF:AlvCntValue" ;
VAL_ 2281701488 WPC_Status 0 "Off" 1 "WPC Mode" 2 "NFC Scanning" 3 "NFC Communicating" 4 "LPCD Mode" 5 "PICC Detected" 6 "RESERVED" 7 "invalid" ;
VAL_ 2281701488 WPC2_Status 0 "Off" 1 "WPC Mode" 2 "NFC Scanning" 3 "NFC Communicating" 4 "LPCD Mode" 5 "PICC Detected" 6 "RESERVED" 7 "invalid" ;
VAL_ 2281701488 WPC_NFC_Opt 0 "Default(NotApplied)" 1 "Applied" 2 "RESERVED" 3 "invalid" ;
VAL_ 402391152 SNI_CGW_CCU 0 "0x0x0~0xFF:NM Source Node ID" 255 "0x0x0~0xFF:NM Source Node ID" ;
VAL_ 402391152 CBV_NMCoSRB_CGW_CCU 0 "Start of synchronized shutdown is not requested by main coordinator" 1 "Start of synchronized shutdown is requested by main coordinator" ;
VAL_ 402391152 CBV_AWB_CGW_CCU 0 "Node has not woken up the network (passive wakeup)" 1 "Node has woken up the network (active wakeup)" ;
VAL_ 402391152 PNI_CGW_CCU_2 0 "0x0~0xFFFFFFFFFFFFFFFF:NM PNC Bit" ;
VAL_ 402391152 CBV_PNIB_CGW_CCU 0 "NM PDU contains no partial network cluster information in the user data area" 1 "NM PDU contains partial network cluster information in the user data area" ;
VAL_ 402391152 NRR_CGW_CCU 0 "Default" 1 "0x1~0xFF:RESERVED" 255 "0x1~0xFF:RESERVED" ;
VAL_ 402391152 PNI_CGW_CCU_3 0 "0x0~0xFFFFFFFFFFFFFFFF:NM PNC Bit" ;
VAL_ 402391152 NM_State_CGW_CCU 0 "Default" 1 "NM_RMS_BSM" 2 "NM_RMS_PBSM" 3 "RESERVED" 4 "NM_NS_RMS" 5 "RESERVED" 6 "RESERVED" 7 "RESERVED" 8 "NM_NS_RSS" 9 "RESERVED" 10 "RESERVED" 11 "RESERVED" 12 "RESERVED" 13 "RESERVED" 14 "RESERVED" 15 "RESERVED" 16 "NM_RMS_RSS" 17 "RESERVED" 18 "RESERVED" 19 "RESERVED" 20 "RESERVED" 21 "RESERVED" 22 "RESERVED" 23 "RESERVED" 24 "RESERVED" 25 "RESERVED" 26 "RESERVED" 27 "RESERVED" 28 "RESERVED" 29 "RESERVED" 30 "RESERVED" 31 "RESERVED" 32 "NM_RMS_NS" 33 "0x21~0xFF:RESERVED" 255 "0x21~0xFF:RESERVED" ;
VAL_ 402391152 PNI_CGW_CCU 0 "0x0x0~0xFFFFFFFF:NM PNC Bit" 2147483647 "0x0x0~0xFFFFFFFF:NM PNC Bit" ;
VAL_ 402391152 PNI_CGW_CCU_1 0 "0x0~0xFFFFFFFFFFFFFFFF:NM PNC Bit" ;
VAL_ 402391152 CBV_RMR_CGW_CCU 0 "Repeat Message State not requested" 1 "Repeat Message State requested" ;
VAL_ 402391152 CBV_NMCoID_CGW_CCU 0 "NM Coordinator ID" 1 "NM Coordinator ID" 2 "NM Coordinator ID" 3 "NM Coordinator ID" ;
VAL_ 2549874733 SNI_L_DHRR_FD 0 "0x0x0~0xFF:NM Source Node ID" 255 "0x0x0~0xFF:NM Source Node ID" ;
VAL_ 2549874733 CBV_RMR_L_DHRR_FD 0 "Repeat Message State not requested" 1 "Repeat Message State requested" ;
VAL_ 2549874733 CBV_NMCoID_L_DHRR_FD 0 "NM Coordinator ID" 1 "NM Coordinator ID" 2 "NM Coordinator ID" 3 "NM Coordinator ID" ;
VAL_ 2549874733 CBV_NMCoSRB_L_DHRR_FD 0 "Start of synchronized shutdown is not requested by main coordinator" 1 "Start of synchronized shutdown is requested by main coordinator" ;
VAL_ 2549874733 CBV_AWB_L_DHRR_FD 0 "Node has not woken up the network (passive wakeup)" 1 "Node has woken up the network (active wakeup)" ;
VAL_ 2549874733 CBV_PNIB_L_DHRR_FD 0 "NM PDU contains no partial network cluster information in the user data area" 1 "NM PDU contains partial network cluster information in the user data area" ;
VAL_ 2549874733 NRR_L_DHRR_FD 0 "Default" 1 "0x1~0xFF:RESERVED" 255 "0x1~0xFF:RESERVED" ;
VAL_ 2549874733 NM_State_L_DHRR_FD 0 "Default" 1 "NM_RMS_BSM" 2 "NM_RMS_PBSM" 3 "RESERVED" 4 "NM_NS_RMS" 5 "RESERVED" 6 "RESERVED" 7 "RESERVED" 8 "NM_NS_RSS" 9 "RESERVED" 10 "RESERVED" 11 "RESERVED" 12 "RESERVED" 13 "RESERVED" 14 "RESERVED" 15 "RESERVED" 16 "NM_RMS_RSS" 17 "RESERVED" 18 "RESERVED" 19 "RESERVED" 20 "RESERVED" 21 "RESERVED" 22 "RESERVED" 23 "RESERVED" 24 "RESERVED" 25 "RESERVED" 26 "RESERVED" 27 "RESERVED" 28 "RESERVED" 29 "RESERVED" 30 "RESERVED" 31 "RESERVED" 32 "NM_RMS_NS" 33 "0x21~0xFF:RESERVED" 255 "0x21~0xFF:RESERVED" ;
VAL_ 2549874733 PNI_L_DHRR_FD 0 "0x0x0~0xFFFFFFFF:NM PNC Bit" 2147483647 "0x0x0~0xFFFFFFFF:NM PNC Bit" ;
VAL_ 2549874733 PNI_L_DHRR_FD_1 0 "0x0~0xFFFFFFFFFFFFFFFF:NM PNC Bit" ;
VAL_ 2549874733 PNI_L_DHRR_FD_2 0 "0x0~0xFFFFFFFFFFFFFFFF:NM PNC Bit" ;
VAL_ 2549874733 PNI_L_DHRR_FD_3 0 "0x0~0xFFFFFFFFFFFFFFFF:NM PNC Bit" ;
VAL_ 2549874720 SNI_L_UWB_BLE_MST_FD 0 "0x0x0~0xFF:NM Source Node ID" 255 "0x0x0~0xFF:NM Source Node ID" ;
VAL_ 2549874720 CBV_RMR_L_UWB_BLE_MST_FD 0 "Repeat Message State not requested" 1 "Repeat Message State requested" ;
VAL_ 2549874720 CBV_NMCoID_L_UWB_BLE_MST_FD 0 "NM Coordinator ID" 1 "NM Coordinator ID" 2 "NM Coordinator ID" 3 "NM Coordinator ID" ;
VAL_ 2549874720 CBV_NMCoSRB_L_UWB_BLE_MST_FD 0 "Start of synchronized shutdown is not requested by main coordinator" 1 "Start of synchronized shutdown is requested by main coordinator" ;
VAL_ 2549874720 CBV_AWB_L_UWB_BLE_MST_FD 0 "Node has not woken up the network (passive wakeup)" 1 "Node has woken up the network (active wakeup)" ;
VAL_ 2549874720 CBV_PNIB_L_UWB_BLE_MST_FD 0 "NM PDU contains no partial network cluster information in the user data area" 1 "NM PDU contains partial network cluster information in the user data area" ;
VAL_ 2549874720 NRR_L_UWB_BLE_MST_FD 0 "Default" 1 "0x1~0xFF:RESERVED" 255 "0x1~0xFF:RESERVED" ;
VAL_ 2549874720 NM_State_L_UWB_BLE_MST_FD 0 "Default" 1 "NM_RMS_BSM" 2 "NM_RMS_PBSM" 3 "RESERVED" 4 "NM_NS_RMS" 5 "RESERVED" 6 "RESERVED" 7 "RESERVED" 8 "NM_NS_RSS" 9 "RESERVED" 10 "RESERVED" 11 "RESERVED" 12 "RESERVED" 13 "RESERVED" 14 "RESERVED" 15 "RESERVED" 16 "NM_RMS_RSS" 17 "RESERVED" 18 "RESERVED" 19 "RESERVED" 20 "RESERVED" 21 "RESERVED" 22 "RESERVED" 23 "RESERVED" 24 "RESERVED" 25 "RESERVED" 26 "RESERVED" 27 "RESERVED" 28 "RESERVED" 29 "RESERVED" 30 "RESERVED" 31 "RESERVED" 32 "NM_RMS_NS" 33 "0x21~0xFF:RESERVED" 255 "0x21~0xFF:RESERVED" ;
VAL_ 2549874720 PNI_L_UWB_BLE_MST_FD 0 "0x0x0~0xFFFFFFFF:NM PNC Bit" 2147483647 "0x0x0~0xFFFFFFFF:NM PNC Bit" ;
VAL_ 2549874720 PNI_L_UWB_BLE_MST_FD_1 0 "0x0~0xFFFFFFFFFFFFFFFF:NM PNC Bit" ;
VAL_ 2549874720 PNI_L_UWB_BLE_MST_FD_2 0 "0x0~0xFFFFFFFFFFFFFFFF:NM PNC Bit" ;
VAL_ 2549874720 PNI_L_UWB_BLE_MST_FD_3 0 "0x0~0xFFFFFFFFFFFFFFFF:NM PNC Bit" ;
VAL_ 2549874726 SNI_L_UWB_RR_FD 0 "0x0x0~0xFF:NM Source Node ID" 255 "0x0x0~0xFF:NM Source Node ID" ;
VAL_ 2549874726 CBV_RMR_L_UWB_RR_FD 0 "Repeat Message State not requested" 1 "Repeat Message State requested" ;
VAL_ 2549874726 CBV_NMCoID_L_UWB_RR_FD 0 "NM Coordinator ID" 1 "NM Coordinator ID" 2 "NM Coordinator ID" 3 "NM Coordinator ID" ;
VAL_ 2549874726 CBV_NMCoSRB_L_UWB_RR_FD 0 "Start of synchronized shutdown is not requested by main coordinator" 1 "Start of synchronized shutdown is requested by main coordinator" ;
VAL_ 2549874726 CBV_AWB_L_UWB_RR_FD 0 "Node has not woken up the network (passive wakeup)" 1 "Node has woken up the network (active wakeup)" ;
VAL_ 2549874726 CBV_PNIB_L_UWB_RR_FD 0 "NM PDU contains no partial network cluster information in the user data area" 1 "NM PDU contains partial network cluster information in the user data area" ;
VAL_ 2549874726 NRR_L_UWB_RR_FD 0 "Default" 1 "0x1~0xFF:RESERVED" 255 "0x1~0xFF:RESERVED" ;
VAL_ 2549874726 NM_State_L_UWB_RR_FD 0 "Default" 1 "NM_RMS_BSM" 2 "NM_RMS_PBSM" 3 "RESERVED" 4 "NM_NS_RMS" 5 "RESERVED" 6 "RESERVED" 7 "RESERVED" 8 "NM_NS_RSS" 9 "RESERVED" 10 "RESERVED" 11 "RESERVED" 12 "RESERVED" 13 "RESERVED" 14 "RESERVED" 15 "RESERVED" 16 "NM_RMS_RSS" 17 "RESERVED" 18 "RESERVED" 19 "RESERVED" 20 "RESERVED" 21 "RESERVED" 22 "RESERVED" 23 "RESERVED" 24 "RESERVED" 25 "RESERVED" 26 "RESERVED" 27 "RESERVED" 28 "RESERVED" 29 "RESERVED" 30 "RESERVED" 31 "RESERVED" 32 "NM_RMS_NS" 33 "0x21~0xFF:RESERVED" 255 "0x21~0xFF:RESERVED" ;
VAL_ 2549874726 PNI_L_UWB_RR_FD 0 "0x0x0~0xFFFFFFFF:NM PNC Bit" 2147483647 "0x0x0~0xFFFFFFFF:NM PNC Bit" ;
VAL_ 2549874726 PNI_L_UWB_RR_FD_1 0 "0x0~0xFFFFFFFFFFFFFFFF:NM PNC Bit" ;
VAL_ 2549874726 PNI_L_UWB_RR_FD_2 0 "0x0~0xFFFFFFFFFFFFFFFF:NM PNC Bit" ;
VAL_ 2549874726 PNI_L_UWB_RR_FD_3 0 "0x0~0xFFFFFFFFFFFFFFFF:NM PNC Bit" ;
VAL_ 2549874721 SNI_L_UWB_BLE_SLV_FD 0 "0x0x0~0xFF:NM Source Node ID" 255 "0x0x0~0xFF:NM Source Node ID" ;
VAL_ 2549874721 CBV_RMR_L_UWB_BLE_SLV_FD 0 "Repeat Message State not requested" 1 "Repeat Message State requested" ;
VAL_ 2549874721 CBV_NMCoID_L_UWB_BLE_SLV_FD 0 "NM Coordinator ID" 1 "NM Coordinator ID" 2 "NM Coordinator ID" 3 "NM Coordinator ID" ;
VAL_ 2549874721 CBV_NMCoSRB_L_UWB_BLE_SLV_FD 0 "Start of synchronized shutdown is not requested by main coordinator" 1 "Start of synchronized shutdown is requested by main coordinator" ;
VAL_ 2549874721 CBV_AWB_L_UWB_BLE_SLV_FD 0 "Node has not woken up the network (passive wakeup)" 1 "Node has woken up the network (active wakeup)" ;
VAL_ 2549874721 CBV_PNIB_L_UWB_BLE_SLV_FD 0 "NM PDU contains no partial network cluster information in the user data area" 1 "NM PDU contains partial network cluster information in the user data area" ;
VAL_ 2549874721 NRR_L_UWB_BLE_SLV_FD 0 "Default" 1 "0x1~0xFF:RESERVED" 255 "0x1~0xFF:RESERVED" ;
VAL_ 2549874721 NM_State_L_UWB_BLE_SLV_FD 0 "Default" 1 "NM_RMS_BSM" 2 "NM_RMS_PBSM" 3 "RESERVED" 4 "NM_NS_RMS" 5 "RESERVED" 6 "RESERVED" 7 "RESERVED" 8 "NM_NS_RSS" 9 "RESERVED" 10 "RESERVED" 11 "RESERVED" 12 "RESERVED" 13 "RESERVED" 14 "RESERVED" 15 "RESERVED" 16 "NM_RMS_RSS" 17 "RESERVED" 18 "RESERVED" 19 "RESERVED" 20 "RESERVED" 21 "RESERVED" 22 "RESERVED" 23 "RESERVED" 24 "RESERVED" 25 "RESERVED" 26 "RESERVED" 27 "RESERVED" 28 "RESERVED" 29 "RESERVED" 30 "RESERVED" 31 "RESERVED" 32 "NM_RMS_NS" 33 "0x21~0xFF:RESERVED" 255 "0x21~0xFF:RESERVED" ;
VAL_ 2549874721 PNI_L_UWB_BLE_SLV_FD 0 "0x0x0~0xFFFFFFFF:NM PNC Bit" 2147483647 "0x0x0~0xFFFFFFFF:NM PNC Bit" ;
VAL_ 2549874721 PNI_L_UWB_BLE_SLV_FD_1 0 "0x0~0xFFFFFFFFFFFFFFFF:NM PNC Bit" ;
VAL_ 2549874721 PNI_L_UWB_BLE_SLV_FD_2 0 "0x0~0xFFFFFFFFFFFFFFFF:NM PNC Bit" ;
VAL_ 2549874721 PNI_L_UWB_BLE_SLV_FD_3 0 "0x0~0xFFFFFFFFFFFFFFFF:NM PNC Bit" ;
VAL_ 2549874723 SNI_L_UWB_FR_FD 0 "0x0x0~0xFF:NM Source Node ID" 255 "0x0x0~0xFF:NM Source Node ID" ;
VAL_ 2549874723 CBV_RMR_L_UWB_FR_FD 0 "Repeat Message State not requested" 1 "Repeat Message State requested" ;
VAL_ 2549874723 CBV_NMCoID_L_UWB_FR_FD 0 "NM Coordinator ID" 1 "NM Coordinator ID" 2 "NM Coordinator ID" 3 "NM Coordinator ID" ;
VAL_ 2549874723 CBV_NMCoSRB_L_UWB_FR_FD 0 "Start of synchronized shutdown is not requested by main coordinator" 1 "Start of synchronized shutdown is requested by main coordinator" ;
VAL_ 2549874723 CBV_AWB_L_UWB_FR_FD 0 "Node has not woken up the network (passive wakeup)" 1 "Node has woken up the network (active wakeup)" ;
VAL_ 2549874723 CBV_PNIB_L_UWB_FR_FD 0 "NM PDU contains no partial network cluster information in the user data area" 1 "NM PDU contains partial network cluster information in the user data area" ;
VAL_ 2549874723 NRR_L_UWB_FR_FD 0 "Default" 1 "0x1~0xFF:RESERVED" 255 "0x1~0xFF:RESERVED" ;
VAL_ 2549874723 NM_State_L_UWB_FR_FD 0 "Default" 1 "NM_RMS_BSM" 2 "NM_RMS_PBSM" 3 "RESERVED" 4 "NM_NS_RMS" 5 "RESERVED" 6 "RESERVED" 7 "RESERVED" 8 "NM_NS_RSS" 9 "RESERVED" 10 "RESERVED" 11 "RESERVED" 12 "RESERVED" 13 "RESERVED" 14 "RESERVED" 15 "RESERVED" 16 "NM_RMS_RSS" 17 "RESERVED" 18 "RESERVED" 19 "RESERVED" 20 "RESERVED" 21 "RESERVED" 22 "RESERVED" 23 "RESERVED" 24 "RESERVED" 25 "RESERVED" 26 "RESERVED" 27 "RESERVED" 28 "RESERVED" 29 "RESERVED" 30 "RESERVED" 31 "RESERVED" 32 "NM_RMS_NS" 33 "0x21~0xFF:RESERVED" 255 "0x21~0xFF:RESERVED" ;
VAL_ 2549874723 PNI_L_UWB_FR_FD 0 "0x0x0~0xFFFFFFFF:NM PNC Bit" 2147483647 "0x0x0~0xFFFFFFFF:NM PNC Bit" ;
VAL_ 2549874723 PNI_L_UWB_FR_FD_1 0 "0x0~0xFFFFFFFFFFFFFFFF:NM PNC Bit" ;
VAL_ 2549874723 PNI_L_UWB_FR_FD_2 0 "0x0~0xFFFFFFFFFFFFFFFF:NM PNC Bit" ;
VAL_ 2549874723 PNI_L_UWB_FR_FD_3 0 "0x0~0xFFFFFFFFFFFFFFFF:NM PNC Bit" ;
VAL_ 2549874732 SNI_L_DHRL_FD 0 "0x0x0~0xFF:NM Source Node ID" 255 "0x0x0~0xFF:NM Source Node ID" ;
VAL_ 2549874732 CBV_RMR_L_DHRL_FD 0 "Repeat Message State not requested" 1 "Repeat Message State requested" ;
VAL_ 2549874732 CBV_NMCoID_L_DHRL_FD 0 "NM Coordinator ID" 1 "NM Coordinator ID" 2 "NM Coordinator ID" 3 "NM Coordinator ID" ;
VAL_ 2549874732 CBV_NMCoSRB_L_DHRL_FD 0 "Start of synchronized shutdown is not requested by main coordinator" 1 "Start of synchronized shutdown is requested by main coordinator" ;
VAL_ 2549874732 CBV_AWB_L_DHRL_FD 0 "Node has not woken up the network (passive wakeup)" 1 "Node has woken up the network (active wakeup)" ;
VAL_ 2549874732 CBV_PNIB_L_DHRL_FD 0 "NM PDU contains no partial network cluster information in the user data area" 1 "NM PDU contains partial network cluster information in the user data area" ;
VAL_ 2549874732 NRR_L_DHRL_FD 0 "Default" 1 "0x1~0xFF:RESERVED" 255 "0x1~0xFF:RESERVED" ;
VAL_ 2549874732 NM_State_L_DHRL_FD 0 "Default" 1 "NM_RMS_BSM" 2 "NM_RMS_PBSM" 3 "RESERVED" 4 "NM_NS_RMS" 5 "RESERVED" 6 "RESERVED" 7 "RESERVED" 8 "NM_NS_RSS" 9 "RESERVED" 10 "RESERVED" 11 "RESERVED" 12 "RESERVED" 13 "RESERVED" 14 "RESERVED" 15 "RESERVED" 16 "NM_RMS_RSS" 17 "RESERVED" 18 "RESERVED" 19 "RESERVED" 20 "RESERVED" 21 "RESERVED" 22 "RESERVED" 23 "RESERVED" 24 "RESERVED" 25 "RESERVED" 26 "RESERVED" 27 "RESERVED" 28 "RESERVED" 29 "RESERVED" 30 "RESERVED" 31 "RESERVED" 32 "NM_RMS_NS" 33 "0x21~0xFF:RESERVED" 255 "0x21~0xFF:RESERVED" ;
VAL_ 2549874732 PNI_L_DHRL_FD 0 "0x0x0~0xFFFFFFFF:NM PNC Bit" 2147483647 "0x0x0~0xFFFFFFFF:NM PNC Bit" ;
VAL_ 2549874732 PNI_L_DHRL_FD_1 0 "0x0~0xFFFFFFFFFFFFFFFF:NM PNC Bit" ;
VAL_ 2549874732 PNI_L_DHRL_FD_2 0 "0x0~0xFFFFFFFFFFFFFFFF:NM PNC Bit" ;
VAL_ 2549874732 PNI_L_DHRL_FD_3 0 "0x0~0xFFFFFFFFFFFFFFFF:NM PNC Bit" ;
VAL_ 2549874727 SNI_L_UWB_TRNK_FD 0 "0x0x0~0xFF:NM Source Node ID" 255 "0x0x0~0xFF:NM Source Node ID" ;
VAL_ 2549874727 CBV_RMR_L_UWB_TRNK_FD 0 "Repeat Message State not requested" 1 "Repeat Message State requested" ;
VAL_ 2549874727 CBV_NMCoID_L_UWB_TRNK_FD 0 "NM Coordinator ID" 1 "NM Coordinator ID" 2 "NM Coordinator ID" 3 "NM Coordinator ID" ;
VAL_ 2549874727 CBV_NMCoSRB_L_UWB_TRNK_FD 0 "Start of synchronized shutdown is not requested by main coordinator" 1 "Start of synchronized shutdown is requested by main coordinator" ;
VAL_ 2549874727 CBV_AWB_L_UWB_TRNK_FD 0 "Node has not woken up the network (passive wakeup)" 1 "Node has woken up the network (active wakeup)" ;
VAL_ 2549874727 CBV_PNIB_L_UWB_TRNK_FD 0 "NM PDU contains no partial network cluster information in the user data area" 1 "NM PDU contains partial network cluster information in the user data area" ;
VAL_ 2549874727 NRR_L_UWB_TRNK_FD 0 "Default" 1 "0x1~0xFF:RESERVED" 255 "0x1~0xFF:RESERVED" ;
VAL_ 2549874727 NM_State_L_UWB_TRNK_FD 0 "Default" 1 "NM_RMS_BSM" 2 "NM_RMS_PBSM" 3 "RESERVED" 4 "NM_NS_RMS" 5 "RESERVED" 6 "RESERVED" 7 "RESERVED" 8 "NM_NS_RSS" 9 "RESERVED" 10 "RESERVED" 11 "RESERVED" 12 "RESERVED" 13 "RESERVED" 14 "RESERVED" 15 "RESERVED" 16 "NM_RMS_RSS" 17 "RESERVED" 18 "RESERVED" 19 "RESERVED" 20 "RESERVED" 21 "RESERVED" 22 "RESERVED" 23 "RESERVED" 24 "RESERVED" 25 "RESERVED" 26 "RESERVED" 27 "RESERVED" 28 "RESERVED" 29 "RESERVED" 30 "RESERVED" 31 "RESERVED" 32 "NM_RMS_NS" 33 "0x21~0xFF:RESERVED" 255 "0x21~0xFF:RESERVED" ;
VAL_ 2549874727 PNI_L_UWB_TRNK_FD 0 "0x0x0~0xFFFFFFFF:NM PNC Bit" 2147483647 "0x0x0~0xFFFFFFFF:NM PNC Bit" ;
VAL_ 2549874727 PNI_L_UWB_TRNK_FD_1 0 "0x0~0xFFFFFFFFFFFFFFFF:NM PNC Bit" ;
VAL_ 2549874727 PNI_L_UWB_TRNK_FD_2 0 "0x0~0xFFFFFFFFFFFFFFFF:NM PNC Bit" ;
VAL_ 2549874727 PNI_L_UWB_TRNK_FD_3 0 "0x0~0xFFFFFFFFFFFFFFFF:NM PNC Bit" ;
VAL_ 2549874724 SNI_L_UWB_FRNK_FD 0 "0x0x0~0xFF:NM Source Node ID" 255 "0x0x0~0xFF:NM Source Node ID" ;
VAL_ 2549874724 CBV_RMR_L_UWB_FRNK_FD 0 "Repeat Message State not requested" 1 "Repeat Message State requested" ;
VAL_ 2549874724 CBV_NMCoID_L_UWB_FRNK_FD 0 "NM Coordinator ID" 1 "NM Coordinator ID" 2 "NM Coordinator ID" 3 "NM Coordinator ID" ;
VAL_ 2549874724 CBV_NMCoSRB_L_UWB_FRNK_FD 0 "Start of synchronized shutdown is not requested by main coordinator" 1 "Start of synchronized shutdown is requested by main coordinator" ;
VAL_ 2549874724 CBV_AWB_L_UWB_FRNK_FD 0 "Node has not woken up the network (passive wakeup)" 1 "Node has woken up the network (active wakeup)" ;
VAL_ 2549874724 CBV_PNIB_L_UWB_FRNK_FD 0 "NM PDU contains no partial network cluster information in the user data area" 1 "NM PDU contains partial network cluster information in the user data area" ;
VAL_ 2549874724 NRR_L_UWB_FRNK_FD 0 "Default" 1 "0x1~0xFF:RESERVED" 255 "0x1~0xFF:RESERVED" ;
VAL_ 2549874724 NM_State_L_UWB_FRNK_FD 0 "Default" 1 "NM_RMS_BSM" 2 "NM_RMS_PBSM" 3 "RESERVED" 4 "NM_NS_RMS" 5 "RESERVED" 6 "RESERVED" 7 "RESERVED" 8 "NM_NS_RSS" 9 "RESERVED" 10 "RESERVED" 11 "RESERVED" 12 "RESERVED" 13 "RESERVED" 14 "RESERVED" 15 "RESERVED" 16 "NM_RMS_RSS" 17 "RESERVED" 18 "RESERVED" 19 "RESERVED" 20 "RESERVED" 21 "RESERVED" 22 "RESERVED" 23 "RESERVED" 24 "RESERVED" 25 "RESERVED" 26 "RESERVED" 27 "RESERVED" 28 "RESERVED" 29 "RESERVED" 30 "RESERVED" 31 "RESERVED" 32 "NM_RMS_NS" 33 "0x21~0xFF:RESERVED" 255 "0x21~0xFF:RESERVED" ;
VAL_ 2549874724 PNI_L_UWB_FRNK_FD 0 "0x0x0~0xFFFFFFFF:NM PNC Bit" 2147483647 "0x0x0~0xFFFFFFFF:NM PNC Bit" ;
VAL_ 2549874724 PNI_L_UWB_FRNK_FD_1 0 "0x0~0xFFFFFFFFFFFFFFFF:NM PNC Bit" ;
VAL_ 2549874724 PNI_L_UWB_FRNK_FD_2 0 "0x0~0xFFFFFFFFFFFFFFFF:NM PNC Bit" ;
VAL_ 2549874724 PNI_L_UWB_FRNK_FD_3 0 "0x0~0xFFFFFFFFFFFFFFFF:NM PNC Bit" ;
VAL_ 2549874722 SNI_L_UWB_FL_FD 0 "0x0x0~0xFF:NM Source Node ID" 255 "0x0x0~0xFF:NM Source Node ID" ;
VAL_ 2549874722 CBV_RMR_L_UWB_FL_FD 0 "Repeat Message State not requested" 1 "Repeat Message State requested" ;
VAL_ 2549874722 CBV_NMCoID_L_UWB_FL_FD 0 "NM Coordinator ID" 1 "NM Coordinator ID" 2 "NM Coordinator ID" 3 "NM Coordinator ID" ;
VAL_ 2549874722 CBV_NMCoSRB_L_UWB_FL_FD 0 "Start of synchronized shutdown is not requested by main coordinator" 1 "Start of synchronized shutdown is requested by main coordinator" ;
VAL_ 2549874722 CBV_AWB_L_UWB_FL_FD 0 "Node has not woken up the network (passive wakeup)" 1 "Node has woken up the network (active wakeup)" ;
VAL_ 2549874722 CBV_PNIB_L_UWB_FL_FD 0 "NM PDU contains no partial network cluster information in the user data area" 1 "NM PDU contains partial network cluster information in the user data area" ;
VAL_ 2549874722 NRR_L_UWB_FL_FD 0 "Default" 1 "0x1~0xFF:RESERVED" 255 "0x1~0xFF:RESERVED" ;
VAL_ 2549874722 NM_State_L_UWB_FL_FD 0 "Default" 1 "NM_RMS_BSM" 2 "NM_RMS_PBSM" 3 "RESERVED" 4 "NM_NS_RMS" 5 "RESERVED" 6 "RESERVED" 7 "RESERVED" 8 "NM_NS_RSS" 9 "RESERVED" 10 "RESERVED" 11 "RESERVED" 12 "RESERVED" 13 "RESERVED" 14 "RESERVED" 15 "RESERVED" 16 "NM_RMS_RSS" 17 "RESERVED" 18 "RESERVED" 19 "RESERVED" 20 "RESERVED" 21 "RESERVED" 22 "RESERVED" 23 "RESERVED" 24 "RESERVED" 25 "RESERVED" 26 "RESERVED" 27 "RESERVED" 28 "RESERVED" 29 "RESERVED" 30 "RESERVED" 31 "RESERVED" 32 "NM_RMS_NS" 33 "0x21~0xFF:RESERVED" 255 "0x21~0xFF:RESERVED" ;
VAL_ 2549874722 PNI_L_UWB_FL_FD 0 "0x0x0~0xFFFFFFFF:NM PNC Bit" 2147483647 "0x0x0~0xFFFFFFFF:NM PNC Bit" ;
VAL_ 2549874722 PNI_L_UWB_FL_FD_1 0 "0x0~0xFFFFFFFFFFFFFFFF:NM PNC Bit" ;
VAL_ 2549874722 PNI_L_UWB_FL_FD_2 0 "0x0~0xFFFFFFFFFFFFFFFF:NM PNC Bit" ;
VAL_ 2549874722 PNI_L_UWB_FL_FD_3 0 "0x0~0xFFFFFFFFFFFFFFFF:NM PNC Bit" ;
VAL_ 2549874816 SNI_GW_BDC_FD 0 "0x0x0~0xFF:NM Source Node ID" 255 "0x0x0~0xFF:NM Source Node ID" ;
VAL_ 2549874816 CBV_RMR_GW_BDC_FD 0 "Repeat Message State not requested" 1 "Repeat Message State requested" ;
VAL_ 2549874816 CBV_NMCoID_GW_BDC_FD 0 "NM Coordinator ID" 1 "NM Coordinator ID" 2 "NM Coordinator ID" 3 "NM Coordinator ID" ;
VAL_ 2549874816 CBV_NMCoSRB_GW_BDC_FD 0 "Start of synchronized shutdown is not requested by main coordinator" 1 "Start of synchronized shutdown is requested by main coordinator" ;
VAL_ 2549874816 CBV_AWB_GW_BDC_FD 0 "Node has not woken up the network (passive wakeup)" 1 "Node has woken up the network (active wakeup)" ;
VAL_ 2549874816 CBV_PNIB_GW_BDC_FD 0 "NM PDU contains no partial network cluster information in the user data area" 1 "NM PDU contains partial network cluster information in the user data area" ;
VAL_ 2549874816 NRR_GW_BDC_FD 0 "Default" 1 "0x1~0xFF:RESERVED" 255 "0x1~0xFF:RESERVED" ;
VAL_ 2549874816 NM_State_GW_BDC_FD 0 "Default" 1 "NM_RMS_BSM" 2 "NM_RMS_PBSM" 3 "RESERVED" 4 "NM_NS_RMS" 5 "RESERVED" 6 "RESERVED" 7 "RESERVED" 8 "NM_NS_RSS" 9 "RESERVED" 10 "RESERVED" 11 "RESERVED" 12 "RESERVED" 13 "RESERVED" 14 "RESERVED" 15 "RESERVED" 16 "NM_RMS_RSS" 17 "RESERVED" 18 "RESERVED" 19 "RESERVED" 20 "RESERVED" 21 "RESERVED" 22 "RESERVED" 23 "RESERVED" 24 "RESERVED" 25 "RESERVED" 26 "RESERVED" 27 "RESERVED" 28 "RESERVED" 29 "RESERVED" 30 "RESERVED" 31 "RESERVED" 32 "NM_RMS_NS" 33 "0x21~0xFF:RESERVED" 255 "0x21~0xFF:RESERVED" ;
VAL_ 2549874816 PNI_GW_BDC_FD 0 "0x0x0~0xFFFFFFFF:NM PNC Bit" 2147483647 "0x0x0~0xFFFFFFFF:NM PNC Bit" ;
VAL_ 2549874816 PNI_GW_BDC_FD_1 0 "0x0~0xFFFFFFFFFFFFFFFF:NM PNC Bit" ;
VAL_ 2549874816 PNI_GW_BDC_FD_2 0 "0x0~0xFFFFFFFFFFFFFFFF:NM PNC Bit" ;
VAL_ 2549874816 PNI_GW_BDC_FD_3 0 "0x0~0xFFFFFFFFFFFFFFFF:NM PNC Bit" ;
VAL_ 2549874725 SNI_L_UWB_RL_FD 0 "0x0x0~0xFF:NM Source Node ID" 255 "0x0x0~0xFF:NM Source Node ID" ;
VAL_ 2549874725 CBV_RMR_L_UWB_RL_FD 0 "Repeat Message State not requested" 1 "Repeat Message State requested" ;
VAL_ 2549874725 CBV_NMCoID_L_UWB_RL_FD 0 "NM Coordinator ID" 1 "NM Coordinator ID" 2 "NM Coordinator ID" 3 "NM Coordinator ID" ;
VAL_ 2549874725 CBV_NMCoSRB_L_UWB_RL_FD 0 "Start of synchronized shutdown is not requested by main coordinator" 1 "Start of synchronized shutdown is requested by main coordinator" ;
VAL_ 2549874725 CBV_AWB_L_UWB_RL_FD 0 "Node has not woken up the network (passive wakeup)" 1 "Node has woken up the network (active wakeup)" ;
VAL_ 2549874725 CBV_PNIB_L_UWB_RL_FD 0 "NM PDU contains no partial network cluster information in the user data area" 1 "NM PDU contains partial network cluster information in the user data area" ;
VAL_ 2549874725 NRR_L_UWB_RL_FD 0 "Default" 1 "0x1~0xFF:RESERVED" 255 "0x1~0xFF:RESERVED" ;
VAL_ 2549874725 NM_State_L_UWB_RL_FD 0 "Default" 1 "NM_RMS_BSM" 2 "NM_RMS_PBSM" 3 "RESERVED" 4 "NM_NS_RMS" 5 "RESERVED" 6 "RESERVED" 7 "RESERVED" 8 "NM_NS_RSS" 9 "RESERVED" 10 "RESERVED" 11 "RESERVED" 12 "RESERVED" 13 "RESERVED" 14 "RESERVED" 15 "RESERVED" 16 "NM_RMS_RSS" 17 "RESERVED" 18 "RESERVED" 19 "RESERVED" 20 "RESERVED" 21 "RESERVED" 22 "RESERVED" 23 "RESERVED" 24 "RESERVED" 25 "RESERVED" 26 "RESERVED" 27 "RESERVED" 28 "RESERVED" 29 "RESERVED" 30 "RESERVED" 31 "RESERVED" 32 "NM_RMS_NS" 33 "0x21~0xFF:RESERVED" 255 "0x21~0xFF:RESERVED" ;
VAL_ 2549874725 PNI_L_UWB_RL_FD 0 "0x0x0~0xFFFFFFFF:NM PNC Bit" 2147483647 "0x0x0~0xFFFFFFFF:NM PNC Bit" ;
VAL_ 2549874725 PNI_L_UWB_RL_FD_1 0 "0x0~0xFFFFFFFFFFFFFFFF:NM PNC Bit" ;
VAL_ 2549874725 PNI_L_UWB_RL_FD_2 0 "0x0~0xFFFFFFFFFFFFFFFF:NM PNC Bit" ;
VAL_ 2549874725 PNI_L_UWB_RL_FD_3 0 "0x0~0xFFFFFFFFFFFFFFFF:NM PNC Bit" ;
VAL_ 2549874857 SNI_L_SAL_FD 0 "0x0x0~0xFF:NM Source Node ID" 255 "0x0x0~0xFF:NM Source Node ID" ;
VAL_ 2549874857 CBV_RMR_L_SAL_FD 0 "Repeat Message State not requested" 1 "Repeat Message State requested" ;
VAL_ 2549874857 CBV_NMCoID_L_SAL_FD 0 "NM Coordinator ID" 1 "NM Coordinator ID" 2 "NM Coordinator ID" 3 "NM Coordinator ID" ;
VAL_ 2549874857 CBV_NMCoSRB_L_SAL_FD 0 "Start of synchronized shutdown is not requested by main coordinator" 1 "Start of synchronized shutdown is requested by main coordinator" ;
VAL_ 2549874857 CBV_AWB_L_SAL_FD 0 "Node has not woken up the network (passive wakeup)" 1 "Node has woken up the network (active wakeup)" ;
VAL_ 2549874857 CBV_PNIB_L_SAL_FD 0 "NM PDU contains no partial network cluster information in the user data area" 1 "NM PDU contains partial network cluster information in the user data area" ;
VAL_ 2549874857 NRR_L_SAL_FD 0 "Default" 1 "0x1~0xFF:RESERVED" 255 "0x1~0xFF:RESERVED" ;
VAL_ 2549874857 NM_State_L_SAL_FD 0 "Default" 1 "NM_RMS_BSM" 2 "NM_RMS_PBSM" 3 "RESERVED" 4 "NM_NS_RMS" 5 "RESERVED" 6 "RESERVED" 7 "RESERVED" 8 "NM_NS_RSS" 9 "RESERVED" 10 "RESERVED" 11 "RESERVED" 12 "RESERVED" 13 "RESERVED" 14 "RESERVED" 15 "RESERVED" 16 "NM_RMS_RSS" 17 "RESERVED" 18 "RESERVED" 19 "RESERVED" 20 "RESERVED" 21 "RESERVED" 22 "RESERVED" 23 "RESERVED" 24 "RESERVED" 25 "RESERVED" 26 "RESERVED" 27 "RESERVED" 28 "RESERVED" 29 "RESERVED" 30 "RESERVED" 31 "RESERVED" 32 "NM_RMS_NS" 33 "0x21~0xFF:RESERVED" 255 "0x21~0xFF:RESERVED" ;
VAL_ 2549874857 PNI_L_SAL_FD 0 "0x0x0~0xFFFFFFFF:NM PNC Bit" 2147483647 "0x0x0~0xFFFFFFFF:NM PNC Bit" ;
VAL_ 2549874857 PNI_L_SAL_FD_1 0 "0x0~0xFFFFFFFFFFFFFFFF:NM PNC Bit" ;
VAL_ 2549874857 PNI_L_SAL_FD_2 0 "0x0~0xFFFFFFFFFFFFFFFF:NM PNC Bit" ;
VAL_ 2549874857 PNI_L_SAL_FD_3 0 "0x0~0xFFFFFFFFFFFFFFFF:NM PNC Bit" ;
VAL_ 2549874718 SNI_L_WPC_FD 0 "0x0x0~0xFF:NM Source Node ID" 255 "0x0x0~0xFF:NM Source Node ID" ;
VAL_ 2549874718 CBV_RMR_L_WPC_FD 0 "Repeat Message State not requested" 1 "Repeat Message State requested" ;
VAL_ 2549874718 CBV_NMCoID_L_WPC_FD 0 "NM Coordinator ID" 1 "NM Coordinator ID" 2 "NM Coordinator ID" 3 "NM Coordinator ID" ;
VAL_ 2549874718 CBV_NMCoSRB_L_WPC_FD 0 "Start of synchronized shutdown is not requested by main coordinator" 1 "Start of synchronized shutdown is requested by main coordinator" ;
VAL_ 2549874718 CBV_AWB_L_WPC_FD 0 "Node has not woken up the network (passive wakeup)" 1 "Node has woken up the network (active wakeup)" ;
VAL_ 2549874718 CBV_PNIB_L_WPC_FD 0 "NM PDU contains no partial network cluster information in the user data area" 1 "NM PDU contains partial network cluster information in the user data area" ;
VAL_ 2549874718 NRR_L_WPC_FD 0 "Default" 1 "0x1~0xFF:RESERVED" 255 "0x1~0xFF:RESERVED" ;
VAL_ 2549874718 NM_State_L_WPC_FD 0 "Default" 1 "NM_RMS_BSM" 2 "NM_RMS_PBSM" 3 "RESERVED" 4 "NM_NS_RMS" 5 "RESERVED" 6 "RESERVED" 7 "RESERVED" 8 "NM_NS_RSS" 9 "RESERVED" 10 "RESERVED" 11 "RESERVED" 12 "RESERVED" 13 "RESERVED" 14 "RESERVED" 15 "RESERVED" 16 "NM_RMS_RSS" 17 "RESERVED" 18 "RESERVED" 19 "RESERVED" 20 "RESERVED" 21 "RESERVED" 22 "RESERVED" 23 "RESERVED" 24 "RESERVED" 25 "RESERVED" 26 "RESERVED" 27 "RESERVED" 28 "RESERVED" 29 "RESERVED" 30 "RESERVED" 31 "RESERVED" 32 "NM_RMS_NS" 33 "0x21~0xFF:RESERVED" 255 "0x21~0xFF:RESERVED" ;
VAL_ 2549874718 PNI_L_WPC_FD 0 "0x0x0~0xFFFFFFFF:NM PNC Bit" 2147483647 "0x0x0~0xFFFFFFFF:NM PNC Bit" ;
VAL_ 2549874718 PNI_L_WPC_FD_1 0 "0x0~0xFFFFFFFFFFFFFFFF:NM PNC Bit" ;
VAL_ 2549874718 PNI_L_WPC_FD_2 0 "0x0~0xFFFFFFFFFFFFFFFF:NM PNC Bit" ;
VAL_ 2549874718 PNI_L_WPC_FD_3 0 "0x0~0xFFFFFFFFFFFFFFFF:NM PNC Bit" ;
VAL_ 2549874728 SNI_L_TPMS_FD 0 "0x0x0~0xFF:NM Source Node ID" 255 "0x0x0~0xFF:NM Source Node ID" ;
VAL_ 2549874728 CBV_RMR_L_TPMS_FD 0 "Repeat Message State not requested" 1 "Repeat Message State requested" ;
VAL_ 2549874728 CBV_NMCoID_L_TPMS_FD 0 "NM Coordinator ID" 1 "NM Coordinator ID" 2 "NM Coordinator ID" 3 "NM Coordinator ID" ;
VAL_ 2549874728 CBV_NMCoSRB_L_TPMS_FD 0 "Start of synchronized shutdown is not requested by main coordinator" 1 "Start of synchronized shutdown is requested by main coordinator" ;
VAL_ 2549874728 CBV_AWB_L_TPMS_FD 0 "Node has not woken up the network (passive wakeup)" 1 "Node has woken up the network (active wakeup)" ;
VAL_ 2549874728 CBV_PNIB_L_TPMS_FD 0 "NM PDU contains no partial network cluster information in the user data area" 1 "NM PDU contains partial network cluster information in the user data area" ;
VAL_ 2549874728 NRR_L_TPMS_FD 0 "Default" 1 "0x1~0xFF:RESERVED" 255 "0x1~0xFF:RESERVED" ;
VAL_ 2549874728 NM_State_L_TPMS_FD 0 "Default" 1 "NM_RMS_BSM" 2 "NM_RMS_PBSM" 3 "RESERVED" 4 "NM_NS_RMS" 5 "RESERVED" 6 "RESERVED" 7 "RESERVED" 8 "NM_NS_RSS" 9 "RESERVED" 10 "RESERVED" 11 "RESERVED" 12 "RESERVED" 13 "RESERVED" 14 "RESERVED" 15 "RESERVED" 16 "NM_RMS_RSS" 17 "RESERVED" 18 "RESERVED" 19 "RESERVED" 20 "RESERVED" 21 "RESERVED" 22 "RESERVED" 23 "RESERVED" 24 "RESERVED" 25 "RESERVED" 26 "RESERVED" 27 "RESERVED" 28 "RESERVED" 29 "RESERVED" 30 "RESERVED" 31 "RESERVED" 32 "NM_RMS_NS" 33 "0x21~0xFF:RESERVED" 255 "0x21~0xFF:RESERVED" ;
VAL_ 2549874728 PNI_L_TPMS_FD 0 "0x0x0~0xFFFFFFFF:NM PNC Bit" 2147483647 "0x0x0~0xFFFFFFFF:NM PNC Bit" ;
VAL_ 2549874728 PNI_L_TPMS_FD_1 0 "0x0~0xFFFFFFFFFFFFFFFF:NM PNC Bit" ;
VAL_ 2549874728 PNI_L_TPMS_FD_2 0 "0x0~0xFFFFFFFFFFFFFFFF:NM PNC Bit" ;
VAL_ 2549874728 PNI_L_TPMS_FD_3 0 "0x0~0xFFFFFFFFFFFFFFFF:NM PNC Bit" ;
VAL_ 2549874730 SNI_L_DHL_FD 0 "0x0x0~0xFF:NM Source Node ID" 255 "0x0x0~0xFF:NM Source Node ID" ;
VAL_ 2549874730 CBV_RMR_L_DHL_FD 0 "Repeat Message State not requested" 1 "Repeat Message State requested" ;
VAL_ 2549874730 CBV_NMCoID_L_DHL_FD 0 "NM Coordinator ID" 1 "NM Coordinator ID" 2 "NM Coordinator ID" 3 "NM Coordinator ID" ;
VAL_ 2549874730 CBV_NMCoSRB_L_DHL_FD 0 "Start of synchronized shutdown is not requested by main coordinator" 1 "Start of synchronized shutdown is requested by main coordinator" ;
VAL_ 2549874730 CBV_AWB_L_DHL_FD 0 "Node has not woken up the network (passive wakeup)" 1 "Node has woken up the network (active wakeup)" ;
VAL_ 2549874730 CBV_PNIB_L_DHL_FD 0 "NM PDU contains no partial network cluster information in the user data area" 1 "NM PDU contains partial network cluster information in the user data area" ;
VAL_ 2549874730 NRR_L_DHL_FD 0 "Default" 1 "0x1~0xFF:RESERVED" 255 "0x1~0xFF:RESERVED" ;
VAL_ 2549874730 NM_State_L_DHL_FD 0 "Default" 1 "NM_RMS_BSM" 2 "NM_RMS_PBSM" 3 "RESERVED" 4 "NM_NS_RMS" 5 "RESERVED" 6 "RESERVED" 7 "RESERVED" 8 "NM_NS_RSS" 9 "RESERVED" 10 "RESERVED" 11 "RESERVED" 12 "RESERVED" 13 "RESERVED" 14 "RESERVED" 15 "RESERVED" 16 "NM_RMS_RSS" 17 "RESERVED" 18 "RESERVED" 19 "RESERVED" 20 "RESERVED" 21 "RESERVED" 22 "RESERVED" 23 "RESERVED" 24 "RESERVED" 25 "RESERVED" 26 "RESERVED" 27 "RESERVED" 28 "RESERVED" 29 "RESERVED" 30 "RESERVED" 31 "RESERVED" 32 "NM_RMS_NS" 33 "0x21~0xFF:RESERVED" 255 "0x21~0xFF:RESERVED" ;
VAL_ 2549874730 PNI_L_DHL_FD 0 "0x0x0~0xFFFFFFFF:NM PNC Bit" 2147483647 "0x0x0~0xFFFFFFFF:NM PNC Bit" ;
VAL_ 2549874730 PNI_L_DHL_FD_1 0 "0x0~0xFFFFFFFFFFFFFFFF:NM PNC Bit" ;
VAL_ 2549874730 PNI_L_DHL_FD_2 0 "0x0~0xFFFFFFFFFFFFFFFF:NM PNC Bit" ;
VAL_ 2549874730 PNI_L_DHL_FD_3 0 "0x0~0xFFFFFFFFFFFFFFFF:NM PNC Bit" ;
VAL_ 2549874731 SNI_L_DHR_FD 0 "0x0x0~0xFF:NM Source Node ID" 255 "0x0x0~0xFF:NM Source Node ID" ;
VAL_ 2549874731 CBV_RMR_L_DHR_FD 0 "Repeat Message State not requested" 1 "Repeat Message State requested" ;
VAL_ 2549874731 CBV_NMCoID_L_DHR_FD 0 "NM Coordinator ID" 1 "NM Coordinator ID" 2 "NM Coordinator ID" 3 "NM Coordinator ID" ;
VAL_ 2549874731 CBV_NMCoSRB_L_DHR_FD 0 "Start of synchronized shutdown is not requested by main coordinator" 1 "Start of synchronized shutdown is requested by main coordinator" ;
VAL_ 2549874731 CBV_AWB_L_DHR_FD 0 "Node has not woken up the network (passive wakeup)" 1 "Node has woken up the network (active wakeup)" ;
VAL_ 2549874731 CBV_PNIB_L_DHR_FD 0 "NM PDU contains no partial network cluster information in the user data area" 1 "NM PDU contains partial network cluster information in the user data area" ;
VAL_ 2549874731 NRR_L_DHR_FD 0 "Default" 1 "0x1~0xFF:RESERVED" 255 "0x1~0xFF:RESERVED" ;
VAL_ 2549874731 NM_State_L_DHR_FD 0 "Default" 1 "NM_RMS_BSM" 2 "NM_RMS_PBSM" 3 "RESERVED" 4 "NM_NS_RMS" 5 "RESERVED" 6 "RESERVED" 7 "RESERVED" 8 "NM_NS_RSS" 9 "RESERVED" 10 "RESERVED" 11 "RESERVED" 12 "RESERVED" 13 "RESERVED" 14 "RESERVED" 15 "RESERVED" 16 "NM_RMS_RSS" 17 "RESERVED" 18 "RESERVED" 19 "RESERVED" 20 "RESERVED" 21 "RESERVED" 22 "RESERVED" 23 "RESERVED" 24 "RESERVED" 25 "RESERVED" 26 "RESERVED" 27 "RESERVED" 28 "RESERVED" 29 "RESERVED" 30 "RESERVED" 31 "RESERVED" 32 "NM_RMS_NS" 33 "0x21~0xFF:RESERVED" 255 "0x21~0xFF:RESERVED" ;
VAL_ 2549874731 PNI_L_DHR_FD 0 "0x0x0~0xFFFFFFFF:NM PNC Bit" 2147483647 "0x0x0~0xFFFFFFFF:NM PNC Bit" ;
VAL_ 2549874731 PNI_L_DHR_FD_1 0 "0x0~0xFFFFFFFFFFFFFFFF:NM PNC Bit" ;
VAL_ 2549874731 PNI_L_DHR_FD_2 0 "0x0~0xFFFFFFFFFFFFFFFF:NM PNC Bit" ;
VAL_ 2549874731 PNI_L_DHR_FD_3 0 "0x0~0xFFFFFFFFFFFFFFFF:NM PNC Bit" ;
